VERSION "2021.24.4"

NS_ :

BS_:

BU_: VEH CH Receiver X

BA_DEF_ BO_ "GenMsgSendType" ENUM "Cyclic";
BA_DEF_ BO_ "GenMsgCycleTime" INT 0 10000;

BA_ "GenMsgSendType" BO_ 528 0;
BA_ "GenMsgCycleTime" BO_ 528 100;

BA_ "GenMsgSendType" BO_ 1879 0;
BA_ "GenMsgCycleTime" BO_ 1879 100;

BA_ "GenMsgSendType" BO_ 1621 0;
BA_ "GenMsgCycleTime" BO_ 1621 100;

BA_ "GenMsgSendType" BO_ 1680 0;
BA_ "GenMsgCycleTime" BO_ 1680 100;

BA_ "GenMsgSendType" BO_ 802 0;
BA_ "GenMsgCycleTime" BO_ 802 1000;

BA_ "GenMsgSendType" BO_ 1019 0;
BA_ "GenMsgCycleTime" BO_ 1019 1000;

BA_ "GenMsgSendType" BO_ 12 0;
BA_ "GenMsgCycleTime" BO_ 12 1000;

BO_ 963 VCRIGHT_switchStatus: 8 Vector__XXX
 SG_ VCRIGHT_3RowRightBuckleSwitch m0 : 62|2@1+ (1,0) [0|0] "" Vector__XXX
 SG_ VCRIGHT_3RowLeftBuckleSwitch m0 : 60|2@1+ (1,0) [0|0] "" Vector__XXX
 SG_ VCRIGHT_hvacHeatingAllowedRight m1 : 59|1@1+ (1,0) [0|0] "" Vector__XXX
 SG_ VCRIGHT_3RowRightOccupancySwitch m0 : 58|2@1+ (1,0) [0|0] "" Vector__XXX
 SG_ VCRIGHT_3RowLeftOccupancySwitch m0 : 56|2@1+ (1,0) [0|0] "" Vector__XXX
 SG_ VCRIGHT_frontSeatResistiveOccupancy m1 : 54|2@1+ (1,0) [0|0] "" Vector__XXX
 SG_ VCRIGHT_rearRightOccupancySwitch m0 : 54|2@1+ (1,0) [0|0] "" Vector__XXX
 SG_ VCRIGHT_liftgateShutfaceSwitchPressed m0 : 53|1@1+ (1,0) [0|0] "" Vector__XXX
 SG_ VCRIGHT_btnWindowSwPackAutoDwnRR m0 : 52|1@1+ (1,0) [0|0] "" Vector__XXX
 SG_ VCRIGHT_btnWindowSwPackDownRR m0 : 51|1@1+ (1,0) [0|0] "" Vector__XXX
 SG_ VCRIGHT_btnWindowSwPackAutoUpRR m0 : 50|1@1+ (1,0) [0|0] "" Vector__XXX
 SG_ VCRIGHT_btnWindowSwPackUpRR m0 : 49|1@1+ (1,0) [0|0] "" Vector__XXX
 SG_ VCRIGHT_trunkExtReleasePressed m0 : 48|1@1+ (1,0) [0|0] "" Vector__XXX
 SG_ VCRIGHT_gloveboxLightCurrent m1 : 47|5@1+ (2,0) [0|0] "" Vector__XXX
 SG_ VCRIGHT_rearRightBuckleSwitch m0 : 46|2@1+ (1,0) [0|0] "" Vector__XXX
 SG_ VCRIGHT_rearCenterBuckleSwitch m0 : 44|2@1+ (1,0) [0|0] "" Vector__XXX
 SG_ VCRIGHT_frontOccupancySwitch m0 : 42|2@1+ (1,0) [0|0] "" Vector__XXX
 SG_ VCRIGHT_frontBuckleSwitch m0 : 40|2@1+ (1,0) [0|0] "" Vector__XXX
 SG_ VCRIGHT_rearHandlePWM m1 : 40|7@1+ (1,0) [0|0] "" Vector__XXX
 SG_ VCRIGHT_btnWindowSwPackAutoDwnLR m0 : 39|1@1+ (1,0) [0|0] "" Vector__XXX
 SG_ VCRIGHT_hvacHeatingAllowedLeft m1 : 39|1@1+ (1,0) [0|0] "" Vector__XXX
 SG_ VCRIGHT_btnWindowSwPackDownLR m0 : 38|1@1+ (1,0) [0|0] "" Vector__XXX
 SG_ VCRIGHT_btnWindowSwPackAutoUpLR m0 : 37|1@1+ (1,0) [0|0] "" Vector__XXX
 SG_ VCRIGHT_btnWindowSwPackUpLR m0 : 36|1@1+ (1,0) [0|0] "" Vector__XXX
 SG_ VCRIGHT_btnWindowSwPackAutoDwnLF m0 : 35|1@1+ (1,0) [0|0] "" Vector__XXX
 SG_ VCRIGHT_btnWindowSwPackDownLF m0 : 34|1@1+ (1,0) [0|0] "" Vector__XXX
 SG_ VCRIGHT_btnWindowSwPackAutoUpLF m0 : 33|1@1+ (1,0) [0|0] "" Vector__XXX
 SG_ VCRIGHT_btnWindowSwPackUpLF m0 : 32|1@1+ (1,0) [0|0] "" Vector__XXX
 SG_ VCRIGHT_frontHandlePWM m1 : 32|7@1+ (1,0) [0|0] "" Vector__XXX
 SG_ VCRIGHT_btnWindowAutoDownRR m0 : 31|1@1+ (1,0) [0|0] "" Vector__XXX
 SG_ VCRIGHT_btnWindowDownRR m0 : 30|1@1+ (1,0) [0|0] "" Vector__XXX
 SG_ VCRIGHT_btnWindowAutoUpRR m0 : 29|1@1+ (1,0) [0|0] "" Vector__XXX
 SG_ VCRIGHT_btnWindowUpRR m0 : 28|1@1+ (1,0) [0|0] "" Vector__XXX
 SG_ VCRIGHT_2RowSeatBackrestFoldSwitch m1 : 27|1@1+ (1,0) [0|0] "" Vector__XXX
 SG_ VCRIGHT_btnWindowAutoDownRF m0 : 27|1@1+ (1,0) [0|0] "" Vector__XXX
 SG_ VCRIGHT_2RowSeatReclineSwitch m1 : 26|1@1+ (1,0) [0|0] "" Vector__XXX
 SG_ VCRIGHT_btnWindowDownRF m0 : 26|1@1+ (1,0) [0|0] "" Vector__XXX
 SG_ VCRIGHT_btnWindowAutoUpRF m0 : 25|1@1+ (1,0) [0|0] "" Vector__XXX
 SG_ VCRIGHT_btnWindowUpRF m0 : 24|1@1+ (1,0) [0|0] "" Vector__XXX
 SG_ VCRIGHT_frontSeatLumbarOut m1 : 24|2@1+ (1,0) [0|0] "" Vector__XXX
 SG_ VCRIGHT_frontSeatLumbarIn m1 : 22|2@1+ (1,0) [0|0] "" Vector__XXX
 SG_ VCRIGHT_frontSeatLumbarUp m1 : 20|2@1+ (1,0) [0|0] "" Vector__XXX
 SG_ VCRIGHT_frontSeatLumbarDown m1 : 18|2@1+ (1,0) [0|0] "" Vector__XXX
 SG_ VCRIGHT_frontSeatBackrestForward m1 : 16|2@1+ (1,0) [0|0] "" Vector__XXX
 SG_ VCRIGHT_frontSeatBackrestBack m1 : 14|2@1+ (1,0) [0|0] "" Vector__XXX
 SG_ VCRIGHT_frontSeatLiftUp m1 : 12|2@1+ (1,0) [0|0] "" Vector__XXX
 SG_ VCRIGHT_frontSeatLiftDown m1 : 10|2@1+ (1,0) [0|0] "" Vector__XXX
 SG_ VCRIGHT_frontSeatTiltUp m1 : 8|2@1+ (1,0) [0|0] "" Vector__XXX
 SG_ VCRIGHT_frontSeatTiltDown m1 : 6|2@1+ (1,0) [0|0] "" Vector__XXX
 SG_ VCRIGHT_frontSeatTrackForward m1 : 4|2@1+ (1,0) [0|0] "" Vector__XXX
 SG_ VCRIGHT_frontSeatTrackBack m1 : 2|2@1+ (1,0) [0|0] "" Vector__XXX
 SG_ VCRIGHT_trunkExtReleasePressedPersist m1 : 1|1@1+ (1,0) [0|0] "" Vector__XXX
 SG_ VCRIGHT_switchStatusIndex M : 0|1@1+ (1,0) [0|0] "" Vector__XXX

BO_ 989 CP_loggingSlow: 8 Vector__XXX
 SG_ CP_doorPushLockoutActive m4 : 63|1@1+ (1,0) [0|0] "" Vector__XXX
 SG_ CP_faultLineSetByCP m2 : 62|1@1+ (1,0) [0|0] "" Vector__XXX
 SG_ CP_pilotWakeCounter m6 : 61|3@1+ (1,0) [0|0] "" Vector__XXX
 SG_ CP_proximityWakeCounter m5 : 61|3@1+ (1,0) [0|0] "" Vector__XXX
 SG_ CP_wakeOnPushCounter m4 : 60|3@1+ (1,0) [0|0] "" Vector__XXX
 SG_ CP_backCover2State m1 : 59|3@1+ (1,0) [0|0] "" Vector__XXX
 SG_ CP_inletHeaterDuty m3 : 57|7@1+ (1,0) [0|0] "" Vector__XXX
 SG_ CP_backCoverState m1 : 56|3@1+ (1,0) [0|0] "" Vector__XXX
 SG_ CP_doorCloseLimiterMaxRequestType m5 : 56|5@1+ (1,0) [0|0] "" Vector__XXX
 SG_ CP_uhfDoorRequestCounts m7 : 56|5@1+ (1,0) [0|0] "" Vector__XXX
 SG_ CP_inletHeaterState m3 : 55|2@1+ (1,0) [0|0] "" Vector__XXX
 SG_ CP_acNumRetries m6 : 53|8@1+ (1,0) [0|0] "" Vector__XXX
 SG_ CP_doorCloseLimiterMaxCount m5 : 52|4@1+ (1,0) [0|0] "" Vector__XXX
 SG_ CP_faultLineV m2 : 52|10@1+ (0.004550576735092864,0) [0|0] "" Vector__XXX
 SG_ CP_inlet2HarnessIdValue m3 : 52|3@1+ (1,0) [0|0] "" Vector__XXX
 SG_ CP_inlet2HarnessIdState m3 : 50|2@1+ (1,0) [0|0] "" Vector__XXX
 SG_ CP_inlet2HarnessV m0 : 50|14@1+ (0.001,0) [0|0] "" Vector__XXX
 SG_ CP_doorOpenLimiterMaxRequestType m5 : 48|4@1+ (1,0) [0|0] "" Vector__XXX
 SG_ CP_sensorExtV m1 : 48|8@1+ (0.01968504,0) [0|0] "" Vector__XXX
 SG_ CP_inlet1HarnessIdValue m3 : 47|3@1+ (1,0) [0|0] "" Vector__XXX
 SG_ CP_inlet1HarnessIdState m3 : 45|2@1+ (1,0) [0|0] "" Vector__XXX
 SG_ CP_doorOpenLimiterMaxCount m5 : 44|4@1+ (1,0) [0|0] "" Vector__XXX
 SG_ CP_nvm_pilotDiodeFaultCount m5 : 41|3@1+ (1,0) [0|0] "" Vector__XXX
 SG_ CP_nvm_badPilotDiodeDetected m5 : 40|1@1+ (1,0) [0|0] "" Vector__XXX
 SG_ CP_pilotHighValue_intervalMin10s m2 : 40|12@1- (0.01,0) [0|0] "" Vector__XXX
 SG_ CP_plcV m1 : 40|8@1+ (0.01294118,0) [0|0] "" Vector__XXX
 SG_ CP_nvm_doorPresentValid m5 : 39|1@1+ (1,0) [0|0] "" Vector__XXX
 SG_ CP_acNextRetryTimeoutS m6 : 38|15@1+ (1,0) [0|0] "" Vector__XXX
 SG_ CP_nvm_doorPresent m5 : 38|1@1+ (1,0) [0|0] "" Vector__XXX
 SG_ CP_nvm_doorOpen m5 : 37|1@1+ (1,0) [0|0] "" Vector__XXX
 SG_ CP_doorId_intervalMax10s m4 : 36|8@1+ (0.0196078431372549,0) [0|0] "" Vector__XXX
 SG_ CP_inlet1HarnessV m0 : 36|14@1+ (0.001,0) [0|0] "" Vector__XXX
 SG_ CP_latchI m3 : 33|12@1+ (0.0025,0) [0|0] "" Vector__XXX
 SG_ CP_ivledV m1 : 32|8@1+ (0.01968504,0) [0|0] "" Vector__XXX
 SG_ CP_doorId_intervalMin10s m4 : 28|8@1+ (0.0196078431372549,0) [0|0] "" Vector__XXX
 SG_ CP_inductiveSensorBaseline m7 : 28|28@1+ (0.08083879947662354,0) [0|0] "" Vector__XXX
 SG_ CP_ivledState m1 : 28|2@1+ (1,0) [0|0] "" Vector__XXX
 SG_ CP_pilotHighValue_intervalMax10s m2 : 28|12@1- (0.01,0) [0|0] "" Vector__XXX
 SG_ CP_UHF_selfTestRssi m3 : 25|8@1+ (1,0) [0|0] "" Vector__XXX
 SG_ CP_acRetryTimeoutS m6 : 23|15@1+ (1,0) [0|0] "" Vector__XXX
 SG_ CP_nvm_doorCloseCycles m5 : 21|16@1+ (1,0) [0|0] "" Vector__XXX
 SG_ CP_proximityV_intervalMin10s m0 : 20|16@1+ (0.0001,0) [0|0] "" Vector__XXX
 SG_ CP_refVoltage m4 : 20|8@1+ (0.0070588235,0) [0|0] "" Vector__XXX
 SG_ CP_doorButtonPressDurationMs m7 : 18|10@1+ (1,0) [0|0] "" Vector__XXX
 SG_ CP_UHF_rxNumBytes m3 : 17|8@1+ (1,0) [0|0] "" Vector__XXX
 SG_ CP_UHF_rxOverflow m3 : 16|1@1+ (1,0) [0|0] "" Vector__XXX
 SG_ CP_backCover2Counts m1 : 16|12@1+ (0.025,0) [0|0] "" Vector__XXX
 SG_ CP_pilotLowValue_intervalMin10s m2 : 16|12@1- (0.01,0) [0|0] "" Vector__XXX
 SG_ CP_tlsMemoryUsage_intervalMin10s m6 : 16|7@1+ (0.7874015748031497,0) [0|0] "" Vector__XXX
 SG_ CP_boardTemperature m4 : 12|8@1+ (1.29411764706,-50) [0|0] "" Vector__XXX
 SG_ CP_cpuUtilization_intervalMin10s m7 : 11|7@1+ (0.7874015748031497,0) [0|0] "" Vector__XXX
 SG_ CP_UHF_rssi m3 : 8|8@1+ (1,0) [0|0] "" Vector__XXX
 SG_ CP_tlsMemoryUsage_intervalMax10s m6 : 8|7@1+ (0.7874015748031497,0) [0|0] "" Vector__XXX
 SG_ CP_nvm_doorOpenCycles m5 : 5|16@1+ (1,0) [0|0] "" Vector__XXX
 SG_ CP_5vSwV m4 : 4|8@1+ (0.027450980392156862,0) [0|0] "" Vector__XXX
 SG_ CP_UHF_chipState m3 : 4|3@1+ (1,0) [0|0] "" Vector__XXX
 SG_ CP_backCoverCounts m1 : 4|12@1+ (0.025,0) [0|0] "" Vector__XXX
 SG_ CP_cpuUtilization_intervalMax10s m7 : 4|7@1+ (0.7874015748031497,0) [0|0] "" Vector__XXX
 SG_ CP_nvm_dataValid m5 : 4|1@1+ (1,0) [0|0] "" Vector__XXX
 SG_ CP_pilotLowValue_intervalMax10s m2 : 4|12@1- (0.01,0) [0|0] "" Vector__XXX
 SG_ CP_proximityV_intervalMax10s m0 : 4|16@1+ (0.0001,0) [0|0] "" Vector__XXX
 SG_ CP_loggingSlowSelect M : 0|4@1+ (1,0) [0|0] "" Vector__XXX

BO_ 1014 VCFRONT_lightStatus: 8 Vector__XXX
 SG_ VC_hcmrMigrationWindowOpen m0 : 63|1@1+ (1,0) [0|0] "" Vector__XXX
 SG_ VC_hcmrMigrationStallDetectionEnabled m0 : 62|1@1+ (1,0) [0|0] "" Vector__XXX
 SG_ VC_hcmrMigrationMigrationNotStarted m0 : 61|1@1+ (1,0) [0|0] "" Vector__XXX
 SG_ VC_hcmrMigrationOnLVSupport m0 : 60|1@1+ (1,0) [0|0] "" Vector__XXX
 SG_ VC_hcmrMigrationVehicleUpdateActive m0 : 59|1@1+ (1,0) [0|0] "" Vector__XXX
 SG_ VC_hcmrMigrationOTAStateNotActive m0 : 58|1@1+ (1,0) [0|0] "" Vector__XXX
 SG_ VC_hcmrMigrationOTAStateWasActive m0 : 57|1@1+ (1,0) [0|0] "" Vector__XXX
 SG_ VC_hcmrMigrationValidWeather m0 : 56|1@1+ (1,0) [0|0] "" Vector__XXX
 SG_ VCFRONT_headlampRoadClass m1 : 55|2@1+ (1,0) [0|0] "" Vector__XXX
 SG_ VC_hcmlMigrationWindowOpen m0 : 55|1@1+ (1,0) [0|0] "" Vector__XXX
 SG_ VC_hcmlMigrationStallDetectionEnabled m0 : 54|1@1+ (1,0) [0|0] "" Vector__XXX
 SG_ VC_hcmlMigrationMigrationNotStarted m0 : 53|1@1+ (1,0) [0|0] "" Vector__XXX
 SG_ VC_hcmlMigrationOnLVSupport m0 : 52|1@1+ (1,0) [0|0] "" Vector__XXX
 SG_ VC_hcmlMigrationVehicleUpdateActive m0 : 51|1@1+ (1,0) [0|0] "" Vector__XXX
 SG_ VC_hcmlMigrationOTAStateNotActive m0 : 50|1@1+ (1,0) [0|0] "" Vector__XXX
 SG_ VC_hcmlMigrationOTAStateWasActive m0 : 49|1@1+ (1,0) [0|0] "" Vector__XXX
 SG_ VC_hcmlMigrationValidWeather m0 : 48|1@1+ (1,0) [0|0] "" Vector__XXX
 SG_ VCFRONT_headlampBendAngle m1 : 47|8@1- (0.1,0) [0|0] "" Vector__XXX
 SG_ VCFRONT_advancedDrivingBeamStatus m1 : 45|2@1+ (1,0) [0|0] "" Vector__XXX
 SG_ VCFRONT_isBendLightingAvailable m1 : 44|1@1+ (1,0) [0|0] "" Vector__XXX
 SG_ VCFRONT_isAdaptiveHighBeamFaulted m1 : 43|1@1+ (1,0) [0|0] "" Vector__XXX
 SG_ VCFRONT_isAdaptiveHighBeamAvailable m1 : 42|1@1+ (1,0) [0|0] "" Vector__XXX
 SG_ VCFRONT_lightStatusMuxIndex M : 39|3@1+ (1,0) [0|0] "" Vector__XXX
 SG_ VC_leftHeadlampHealth : 36|3@1+ (1,0) [0|0] "" Vector__XXX
 SG_ VC_rightHeadlampHealth : 33|3@1+ (1,0) [0|0] "" Vector__XXX
 SG_ VCFRONT_lowBeamsOnForDRL : 32|1@1+ (1,0) [0|0] "" Vector__XXX
 SG_ VCFRONT_lowBeamRightReadyForAiming : 31|1@1+ (1,0) [0|0] "" Vector__XXX
 SG_ VCFRONT_lowBeamLeftReadyForAiming : 30|1@1+ (1,0) [0|0] "" Vector__XXX
 SG_ VCFRONT_parkRightStatus : 28|2@1+ (1,0) [0|0] "" Vector__XXX
 SG_ VCFRONT_parkLeftStatus : 26|2@1+ (1,0) [0|0] "" Vector__XXX
 SG_ VCFRONT_turnSignalRightStatus : 24|2@1+ (1,0) [0|0] "" Vector__XXX
 SG_ VCFRONT_turnSignalLeftStatus : 22|2@1+ (1,0) [0|0] "" Vector__XXX
 SG_ VCFRONT_sideRepeaterRightStatus : 20|2@1+ (1,0) [0|0] "" Vector__XXX
 SG_ VCFRONT_sideRepeaterLeftStatus : 18|2@1+ (1,0) [0|0] "" Vector__XXX
 SG_ VCFRONT_sideMarkersStatus : 16|2@1+ (1,0) [0|0] "" Vector__XXX
 SG_ VCFRONT_fogRightStatus : 14|2@1+ (1,0) [0|0] "" Vector__XXX
 SG_ VCFRONT_fogLeftStatus : 12|2@1+ (1,0) [0|0] "" Vector__XXX
 SG_ VCFRONT_DRLRightStatus : 10|2@1+ (1,0) [0|0] "" Vector__XXX
 SG_ VCFRONT_DRLLeftStatus : 8|2@1+ (1,0) [0|0] "" Vector__XXX
 SG_ VCFRONT_highBeamRightStatus : 6|2@1+ (1,0) [0|0] "" Vector__XXX
 SG_ VCFRONT_highBeamLeftStatus : 4|2@1+ (1,0) [0|0] "" Vector__XXX
 SG_ VCFRONT_lowBeamRightStatus : 2|2@1+ (1,0) [0|0] "" Vector__XXX
 SG_ VCFRONT_lowBeamLeftStatus : 0|2@1+ (1,0) [0|0] "" Vector__XXX

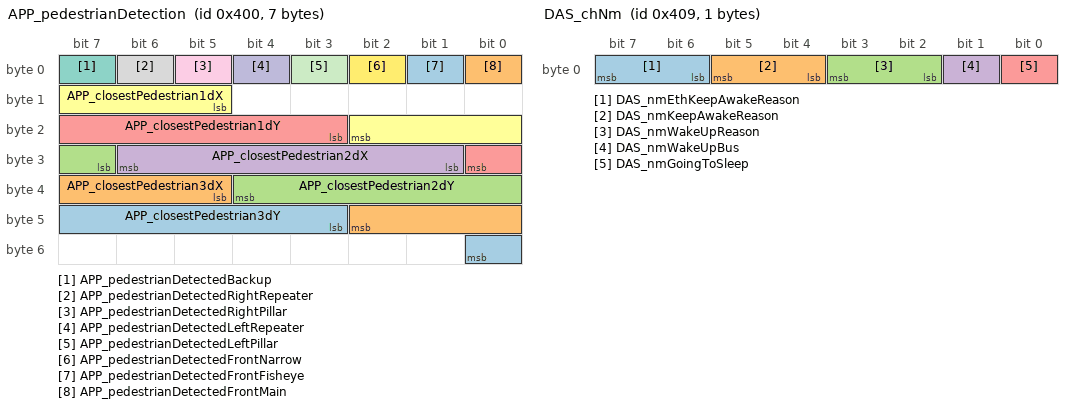
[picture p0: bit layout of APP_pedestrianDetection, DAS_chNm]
BO_ 1024 APP_pedestrianDetection: 7 Vector__XXX
 SG_ APP_closestPedestrian3dY : 43|6@1- (0.4,0) [0|0] "" Vector__XXX
 SG_ APP_closestPedestrian3dX : 37|6@1- (0.4,0) [0|0] "" Vector__XXX
 SG_ APP_closestPedestrian2dY : 31|6@1- (0.4,0) [0|0] "" Vector__XXX
 SG_ APP_closestPedestrian2dX : 25|6@1- (0.4,0) [0|0] "" Vector__XXX
 SG_ APP_closestPedestrian1dY : 19|6@1- (0.4,0) [0|0] "" Vector__XXX
 SG_ APP_closestPedestrian1dX : 13|6@1- (0.4,0) [0|0] "" Vector__XXX
 SG_ APP_pedestrianDetectedBackup : 7|1@1+ (1,0) [0|0] "" Vector__XXX
 SG_ APP_pedestrianDetectedRightRepeater : 6|1@1+ (1,0) [0|0] "" Vector__XXX
 SG_ APP_pedestrianDetectedRightPillar : 5|1@1+ (1,0) [0|0] "" Vector__XXX
 SG_ APP_pedestrianDetectedLeftRepeater : 4|1@1+ (1,0) [0|0] "" Vector__XXX
 SG_ APP_pedestrianDetectedLeftPillar : 3|1@1+ (1,0) [0|0] "" Vector__XXX
 SG_ APP_pedestrianDetectedFrontNarrow : 2|1@1+ (1,0) [0|0] "" Vector__XXX
 SG_ APP_pedestrianDetectedFrontFisheye : 1|1@1+ (1,0) [0|0] "" Vector__XXX
 SG_ APP_pedestrianDetectedFrontMain : 0|1@1+ (1,0) [0|0] "" Vector__XXX

BO_ 1031 DAS_bodyControls2: 8 Vector__XXX
 SG_ DAS_windowLockoutMode : 56|3@1+ (1,0) [0|0] "" Vector__XXX
 SG_ DAS_lightingAnimationRequest : 45|3@1+ (1,0) [0|0] "" Vector__XXX
 SG_ DAS_rearTrunkLockRequest : 43|2@1+ (1,0) [0|0] "" Vector__XXX
 SG_ DAS_doorLockRequestRR : 41|2@1+ (1,0) [0|0] "" Vector__XXX
 SG_ DAS_doorLockRequestRL : 39|2@1+ (1,0) [0|0] "" Vector__XXX
 SG_ DAS_doorLockRequestFR : 37|2@1+ (1,0) [0|0] "" Vector__XXX
 SG_ DAS_doorLockRequestFL : 35|2@1+ (1,0) [0|0] "" Vector__XXX
 SG_ DAS_frunkRequest : 33|2@1+ (1,0) [0|0] "" Vector__XXX
 SG_ DAS_windowRequestActiveRR : 32|1@1+ (1,0) [0|0] "" Vector__XXX
 SG_ DAS_windowRequestActiveRL : 31|1@1+ (1,0) [0|0] "" Vector__XXX
 SG_ DAS_windowRequestActiveFR : 30|1@1+ (1,0) [0|0] "" Vector__XXX
 SG_ DAS_windowRequestActiveFL : 29|1@1+ (1,0) [0|0] "" Vector__XXX
 SG_ DAS_windowRequest : 26|3@1+ (1,0) [0|0] "" Vector__XXX
 SG_ DAS_trunkRequest : 24|2@1+ (1,0) [0|0] "" Vector__XXX
 SG_ DAS_hornRequest : 22|2@1+ (1,0) [0|0] "" Vector__XXX
 SG_ DAS_parkingLightDimRequest : 21|1@1+ (1,0) [0|0] "" Vector__XXX
 SG_ DAS_airTankDischargeCmd : 20|1@1+ (1,0) [0|0] "" Vector__XXX
 SG_ DAS_airCleanPillarBackupCmd : 19|1@1+ (1,0) [0|0] "" Vector__XXX
 SG_ DAS_airCleanRepeaterCmd : 18|1@1+ (1,0) [0|0] "" Vector__XXX
 SG_ DAS_fluidCleanPillarBackupCmd : 17|1@1+ (1,0) [0|0] "" Vector__XXX
 SG_ DAS_fluidCleanRightRepeaterCmd : 16|1@1+ (1,0) [0|0] "" Vector__XXX
 SG_ DAS_fluidCleanLeftRepeaterCmd : 15|1@1+ (1,0) [0|0] "" Vector__XXX
 SG_ DAS_fluidCleanFasciaCmd : 14|1@1+ (1,0) [0|0] "" Vector__XXX
 SG_ DAS_narrowWipeRequest : 13|1@1+ (1,0) [0|0] "" Vector__XXX
 SG_ DAS_narrowWiperWashRequest : 12|1@1+ (1,0) [0|0] "" Vector__XXX
 SG_ DAS_bodyControls2Counter : 8|4@1+ (1,0) [0|0] "" Vector__XXX
 SG_ DAS_bodyControls2Checksum : 0|8@1+ (1,0) [0|0] "" Vector__XXX

BO_ 1033 DAS_chNm: 1 Vector__XXX
 SG_ DAS_nmEthKeepAwakeReason : 6|2@1+ (1,0) [0|0] "" Vector__XXX
 SG_ DAS_nmKeepAwakeReason : 4|2@1+ (1,0) [0|0] "" Vector__XXX
 SG_ DAS_nmWakeUpReason : 2|2@1+ (1,0) [0|0] "" Vector__XXX
 SG_ DAS_nmWakeUpBus : 1|1@1+ (1,0) [0|0] "" Vector__XXX
 SG_ DAS_nmGoingToSleep : 0|1@1+ (1,0) [0|0] "" Vector__XXX

BO_ 1044 GTW_chargingID: 8 Vector__XXX
 SG_ GTW_chargingIDHigh m16 : 47|24@0+ (1,0) [0|0] "" Vector__XXX
 SG_ GTW_chargingIDLow m18 : 15|56@0+ (1,0) [0|0] "" Vector__XXX
 SG_ GTW_chargingIDMid m17 : 15|56@0+ (1,0) [0|0] "" Vector__XXX
 SG_ GTW_chargingIDIndex M : 7|8@0+ (1,0) [0|0] "" Vector__XXX

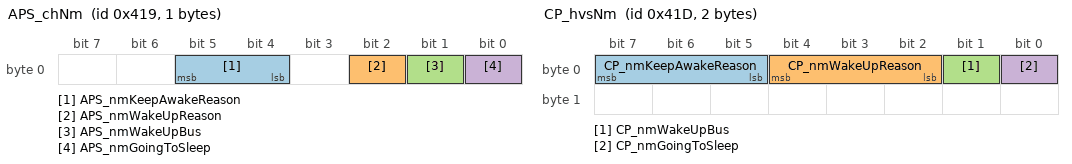
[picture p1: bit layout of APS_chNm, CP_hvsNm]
BO_ 1049 APS_chNm: 1 Vector__XXX
 SG_ APS_nmKeepAwakeReason : 4|2@1+ (1,0) [0|0] "" Vector__XXX
 SG_ APS_nmWakeUpReason : 2|1@1+ (1,0) [0|0] "" Vector__XXX
 SG_ APS_nmWakeUpBus : 1|1@1+ (1,0) [0|0] "" Vector__XXX
 SG_ APS_nmGoingToSleep : 0|1@1+ (1,0) [0|0] "" Vector__XXX

BO_ 1053 CP_hvsNm: 2 Vector__XXX
 SG_ CP_nmKeepAwakeReason : 5|3@1+ (1,0) [0|0] "" Vector__XXX
 SG_ CP_nmWakeUpReason : 2|3@1+ (1,0) [0|0] "" Vector__XXX
 SG_ CP_nmWakeUpBus : 1|1@1+ (1,0) [0|0] "" Vector__XXX
 SG_ CP_nmGoingToSleep : 0|1@1+ (1,0) [0|0] "" Vector__XXX

BO_ 1056 APS_state: 8 Vector__XXX
 SG_ APS_stateCounter : 55|4@1+ (1,0) [0|0] "" Vector__XXX
 SG_ APS_B_faultInduced : 54|1@1+ (1,0) [0|0] "" Vector__XXX
 SG_ APS_A_faultInduced : 53|1@1+ (1,0) [0|0] "" Vector__XXX
 SG_ APS_eplannerState : 50|3@1+ (1,0) [0|0] "" Vector__XXX
 SG_ APS_B_autosteerMonitorState : 47|3@1+ (1,0) [0|0] "" Vector__XXX
 SG_ APS_A_autosteerMonitorState : 44|3@1+ (1,0) [0|0] "" Vector__XXX
 SG_ APS_B_faultState : 39|5@1+ (1,0) [0|0] "" Vector__XXX
 SG_ APS_B_resetState : 36|3@1+ (1,0) [0|0] "" Vector__XXX
 SG_ APS_B_sleepState : 32|4@1+ (1,0) [0|0] "" Vector__XXX
 SG_ APS_B_powerState : 27|5@1+ (1,0) [0|0] "" Vector__XXX
 SG_ APS_B_arbState : 24|3@1+ (1,0) [0|0] "" Vector__XXX
 SG_ APS_secondaryTurbo : 22|2@1+ (1,0) [0|0] "" Vector__XXX
 SG_ APS_A_faultState : 17|5@1+ (1,0) [0|0] "" Vector__XXX
 SG_ APS_A_resetState : 14|3@1+ (1,0) [0|0] "" Vector__XXX
 SG_ APS_A_sleepState : 10|4@1+ (1,0) [0|0] "" Vector__XXX
 SG_ APS_A_powerState : 5|5@1+ (1,0) [0|0] "" Vector__XXX
 SG_ APS_A_arbState : 2|3@1+ (1,0) [0|0] "" Vector__XXX
 SG_ APS_primaryTurbo : 0|2@1+ (1,0) [0|0] "" Vector__XXX

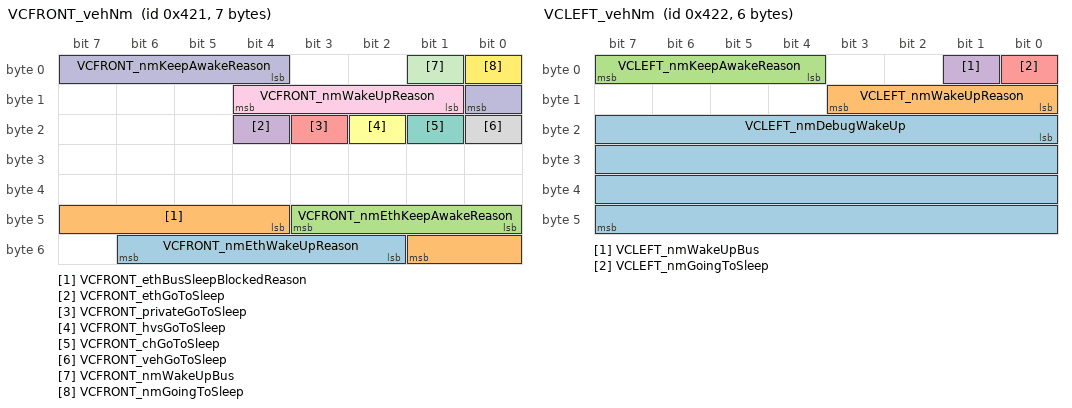
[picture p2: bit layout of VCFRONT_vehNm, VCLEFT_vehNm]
BO_ 1057 VCFRONT_vehNm: 7 Vector__XXX
 SG_ VCFRONT_nmEthWakeUpReason : 50|5@1+ (1,0) [0|0] "" Vector__XXX
 SG_ VCFRONT_ethBusSleepBlockedReason : 44|6@1+ (1,0) [0|0] "" Vector__XXX
 SG_ VCFRONT_nmEthKeepAwakeReason : 40|4@1+ (1,0) [0|0] "" Vector__XXX
 SG_ VCFRONT_ethGoToSleep : 20|1@1+ (1,0) [0|0] "" Vector__XXX
 SG_ VCFRONT_privateGoToSleep : 19|1@1+ (1,0) [0|0] "" Vector__XXX
 SG_ VCFRONT_hvsGoToSleep : 18|1@1+ (1,0) [0|0] "" Vector__XXX
 SG_ VCFRONT_chGoToSleep : 17|1@1+ (1,0) [0|0] "" Vector__XXX
 SG_ VCFRONT_vehGoToSleep : 16|1@1+ (1,0) [0|0] "" Vector__XXX
 SG_ VCFRONT_nmWakeUpReason : 9|4@1+ (1,0) [0|0] "" Vector__XXX
 SG_ VCFRONT_nmKeepAwakeReason : 4|5@1+ (1,0) [0|0] "" Vector__XXX
 SG_ VCFRONT_nmWakeUpBus : 1|1@1+ (1,0) [0|0] "" Vector__XXX
 SG_ VCFRONT_nmGoingToSleep : 0|1@1+ (1,0) [0|0] "" Vector__XXX

BO_ 1058 VCLEFT_vehNm: 6 Vector__XXX
 SG_ VCLEFT_nmDebugWakeUp : 16|32@1+ (1,0) [0|0] "" Vector__XXX
 SG_ VCLEFT_nmWakeUpReason : 8|4@1+ (1,0) [0|0] "" Vector__XXX
 SG_ VCLEFT_nmKeepAwakeReason : 4|4@1+ (1,0) [0|0] "" Vector__XXX
 SG_ VCLEFT_nmWakeUpBus : 1|1@1+ (1,0) [0|0] "" Vector__XXX
 SG_ VCLEFT_nmGoingToSleep : 0|1@1+ (1,0) [0|0] "" Vector__XXX

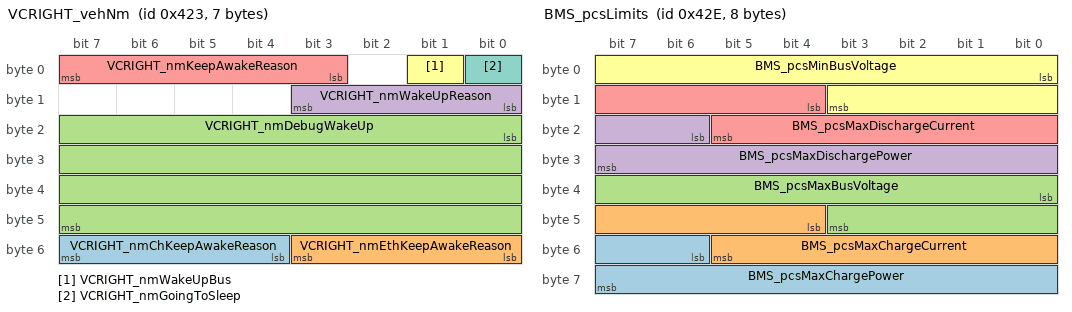
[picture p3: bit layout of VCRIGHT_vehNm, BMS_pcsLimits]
BO_ 1059 VCRIGHT_vehNm: 7 Vector__XXX
 SG_ VCRIGHT_nmChKeepAwakeReason : 52|4@1+ (1,0) [0|0] "" Vector__XXX
 SG_ VCRIGHT_nmEthKeepAwakeReason : 48|4@1+ (1,0) [0|0] "" Vector__XXX
 SG_ VCRIGHT_nmDebugWakeUp : 16|32@1+ (1,0) [0|0] "" Vector__XXX
 SG_ VCRIGHT_nmWakeUpReason : 8|4@1+ (1,0) [0|0] "" Vector__XXX
 SG_ VCRIGHT_nmKeepAwakeReason : 3|5@1+ (1,0) [0|0] "" Vector__XXX
 SG_ VCRIGHT_nmWakeUpBus : 1|1@1+ (1,0) [0|0] "" Vector__XXX
 SG_ VCRIGHT_nmGoingToSleep : 0|1@1+ (1,0) [0|0] "" Vector__XXX

BO_ 1070 BMS_pcsLimits: 8 Vector__XXX
 SG_ BMS_pcsMaxChargePower : 54|10@1+ (0.025,0) [0|0] "" Vector__XXX
 SG_ BMS_pcsMaxChargeCurrent : 44|10@1+ (0.1,0) [0|0] "" Vector__XXX
 SG_ BMS_pcsMaxBusVoltage : 32|12@1+ (0.25,0) [0|0] "" Vector__XXX
 SG_ BMS_pcsMaxDischargePower : 22|10@1+ (0.025,0) [0|0] "" Vector__XXX
 SG_ BMS_pcsMaxDischargeCurrent : 12|10@1+ (0.1,0) [0|0] "" Vector__XXX
 SG_ BMS_pcsMinBusVoltage : 0|12@1+ (0.25,0) [0|0] "" Vector__XXX

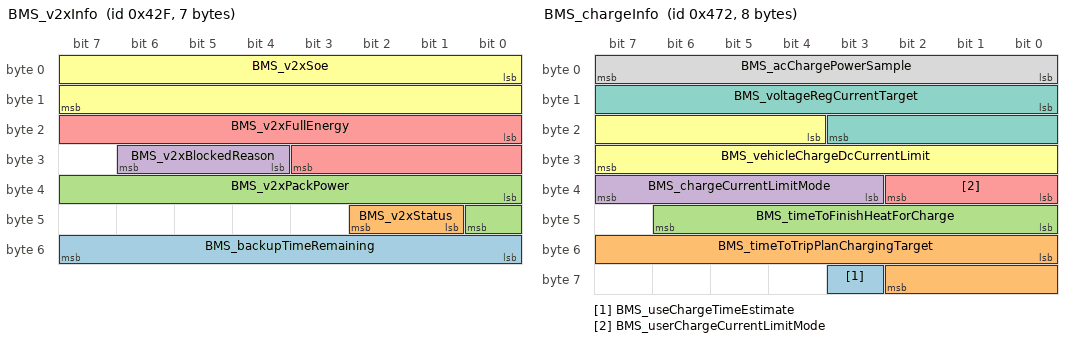
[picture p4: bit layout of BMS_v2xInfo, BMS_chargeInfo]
BO_ 1071 BMS_v2xInfo: 7 Vector__XXX
 SG_ BMS_backupTimeRemaining : 48|8@1+ (1,0) [0|0] "" Vector__XXX
 SG_ BMS_v2xStatus : 41|2@1+ (1,0) [0|0] "" Vector__XXX
 SG_ BMS_v2xPackPower : 32|9@1+ (0.1,-25) [0|0] "" Vector__XXX
 SG_ BMS_v2xBlockedReason : 28|3@1+ (1,0) [0|0] "" Vector__XXX
 SG_ BMS_v2xFullEnergy : 16|12@1+ (0.05,0) [0|0] "" Vector__XXX
 SG_ BMS_v2xSoe : 0|16@1+ (0.002,0) [0|0] "" Vector__XXX

BO_ 1083 VCSEC_peripheralOTAStatus: 8 Vector__XXX
 SG_ VCSEC_TPMSUpdateRetryLimitReached0 m0 : 59|1@1+ (1,0) [0|0] "" Vector__XXX
 SG_ VCSEC_TPMSUpdateRetryLimitReached1 m1 : 59|1@1+ (1,0) [0|0] "" Vector__XXX
 SG_ VCSEC_TPMSUpdateRetryLimitReached2 m2 : 59|1@1+ (1,0) [0|0] "" Vector__XXX
 SG_ VCSEC_TPMSUpdateRetryLimitReached3 m3 : 59|1@1+ (1,0) [0|0] "" Vector__XXX
 SG_ VCSEC_TPMSUpdateHasStarted0 m0 : 58|1@1+ (1,0) [0|0] "" Vector__XXX
 SG_ VCSEC_TPMSUpdateHasStarted1 m1 : 58|1@1+ (1,0) [0|0] "" Vector__XXX
 SG_ VCSEC_TPMSUpdateHasStarted2 m2 : 58|1@1+ (1,0) [0|0] "" Vector__XXX
 SG_ VCSEC_TPMSUpdateHasStarted3 m3 : 58|1@1+ (1,0) [0|0] "" Vector__XXX
 SG_ VCSEC_TPMSUpdateHasUpdated0 m0 : 57|1@1+ (1,0) [0|0] "" Vector__XXX
 SG_ VCSEC_TPMSUpdateHasUpdated1 m1 : 57|1@1+ (1,0) [0|0] "" Vector__XXX
 SG_ VCSEC_TPMSUpdateHasUpdated2 m2 : 57|1@1+ (1,0) [0|0] "" Vector__XXX
 SG_ VCSEC_TPMSUpdateHasUpdated3 m3 : 57|1@1+ (1,0) [0|0] "" Vector__XXX
 SG_ VCSEC_keyWhitelistIndexBeingUpdated m4 : 57|5@1+ (1,0) [0|0] "" Vector__XXX
 SG_ VCSEC_KeyfobUpdateExpectReconnect m4 : 56|1@1+ (1,0) [0|0] "" Vector__XXX
 SG_ VCSEC_TPMSUpdateExpectReconnect0 m0 : 56|1@1+ (1,0) [0|0] "" Vector__XXX
 SG_ VCSEC_TPMSUpdateExpectReconnect1 m1 : 56|1@1+ (1,0) [0|0] "" Vector__XXX
 SG_ VCSEC_TPMSUpdateExpectReconnect2 m2 : 56|1@1+ (1,0) [0|0] "" Vector__XXX
 SG_ VCSEC_TPMSUpdateExpectReconnect3 m3 : 56|1@1+ (1,0) [0|0] "" Vector__XXX
 SG_ VCSEC_KeyfobUpdateWaitForFlashCount m4 : 52|4@1+ (1,0) [0|0] "" Vector__XXX
 SG_ VCSEC_TPMSUpdateWaitForFlashCount0 m0 : 52|4@1+ (1,0) [0|0] "" Vector__XXX
 SG_ VCSEC_TPMSUpdateWaitForFlashCount1 m1 : 52|4@1+ (1,0) [0|0] "" Vector__XXX
 SG_ VCSEC_TPMSUpdateWaitForFlashCount2 m2 : 52|4@1+ (1,0) [0|0] "" Vector__XXX
 SG_ VCSEC_TPMSUpdateWaitForFlashCount3 m3 : 52|4@1+ (1,0) [0|0] "" Vector__XXX
 SG_ VCSEC_KeyfobUpdateStalledBlockCount m4 : 48|4@1+ (1,0) [0|0] "" Vector__XXX
 SG_ VCSEC_TPMSUpdateStalledBlockCount0 m0 : 48|4@1+ (1,0) [0|0] "" Vector__XXX
 SG_ VCSEC_TPMSUpdateStalledBlockCount1 m1 : 48|4@1+ (1,0) [0|0] "" Vector__XXX
 SG_ VCSEC_TPMSUpdateStalledBlockCount2 m2 : 48|4@1+ (1,0) [0|0] "" Vector__XXX
 SG_ VCSEC_TPMSUpdateStalledBlockCount3 m3 : 48|4@1+ (1,0) [0|0] "" Vector__XXX
 SG_ VCSEC_KeyfobUpdateLocationSetCount m4 : 44|4@1+ (1,0) [0|0] "" Vector__XXX
 SG_ VCSEC_TPMSUpdateLocationSetCount0 m0 : 44|4@1+ (1,0) [0|0] "" Vector__XXX
 SG_ VCSEC_TPMSUpdateLocationSetCount1 m1 : 44|4@1+ (1,0) [0|0] "" Vector__XXX
 SG_ VCSEC_TPMSUpdateLocationSetCount2 m2 : 44|4@1+ (1,0) [0|0] "" Vector__XXX
 SG_ VCSEC_TPMSUpdateLocationSetCount3 m3 : 44|4@1+ (1,0) [0|0] "" Vector__XXX
 SG_ VCSEC_KeyfobUpdateCRCRequestTimeoutCount m4 : 40|4@1+ (1,0) [0|0] "" Vector__XXX
 SG_ VCSEC_TPMSUpdateCRCRequestTimeoutCount0 m0 : 40|4@1+ (1,0) [0|0] "" Vector__XXX
 SG_ VCSEC_TPMSUpdateCRCRequestTimeoutCount1 m1 : 40|4@1+ (1,0) [0|0] "" Vector__XXX
 SG_ VCSEC_TPMSUpdateCRCRequestTimeoutCount2 m2 : 40|4@1+ (1,0) [0|0] "" Vector__XXX
 SG_ VCSEC_TPMSUpdateCRCRequestTimeoutCount3 m3 : 40|4@1+ (1,0) [0|0] "" Vector__XXX
 SG_ VCSEC_KeyfobUpdateBlockErrorCount m4 : 36|4@1+ (1,0) [0|0] "" Vector__XXX
 SG_ VCSEC_TPMSUpdateBlockErrorCount0 m0 : 36|4@1+ (1,0) [0|0] "" Vector__XXX
 SG_ VCSEC_TPMSUpdateBlockErrorCount1 m1 : 36|4@1+ (1,0) [0|0] "" Vector__XXX
 SG_ VCSEC_TPMSUpdateBlockErrorCount2 m2 : 36|4@1+ (1,0) [0|0] "" Vector__XXX
 SG_ VCSEC_TPMSUpdateBlockErrorCount3 m3 : 36|4@1+ (1,0) [0|0] "" Vector__XXX
 SG_ VCSEC_KeyfobUpdateBlockTimeoutCount m4 : 32|4@1+ (1,0) [0|0] "" Vector__XXX
 SG_ VCSEC_TPMSUpdateBlockTimeoutCount0 m0 : 32|4@1+ (1,0) [0|0] "" Vector__XXX
 SG_ VCSEC_TPMSUpdateBlockTimeoutCount1 m1 : 32|4@1+ (1,0) [0|0] "" Vector__XXX
 SG_ VCSEC_TPMSUpdateBlockTimeoutCount2 m2 : 32|4@1+ (1,0) [0|0] "" Vector__XXX
 SG_ VCSEC_TPMSUpdateBlockTimeoutCount3 m3 : 32|4@1+ (1,0) [0|0] "" Vector__XXX
 SG_ VCSEC_KeyfobUpdateLastRespStatus m4 : 24|8@1+ (1,0) [0|0] "" Vector__XXX
 SG_ VCSEC_TPMSUpdateLastStatus0 m0 : 24|8@1+ (1,0) [0|0] "" Vector__XXX
 SG_ VCSEC_TPMSUpdateLastStatus1 m1 : 24|8@1+ (1,0) [0|0] "" Vector__XXX
 SG_ VCSEC_TPMSUpdateLastStatus2 m2 : 24|8@1+ (1,0) [0|0] "" Vector__XXX
 SG_ VCSEC_TPMSUpdateLastStatus3 m3 : 24|8@1+ (1,0) [0|0] "" Vector__XXX
 SG_ VCSEC_KeyfobUpdateLastTxStatus m4 : 16|8@1+ (1,0) [0|0] "" Vector__XXX
 SG_ VCSEC_TPMSUpdateState0 m0 : 16|8@1+ (1,0) [0|0] "" Vector__XXX
 SG_ VCSEC_TPMSUpdateState1 m1 : 16|8@1+ (1,0) [0|0] "" Vector__XXX
 SG_ VCSEC_TPMSUpdateState2 m2 : 16|8@1+ (1,0) [0|0] "" Vector__XXX
 SG_ VCSEC_TPMSUpdateState3 m3 : 16|8@1+ (1,0) [0|0] "" Vector__XXX
 SG_ VCSEC_KeyfobStagingProgress m4 : 8|7@1+ (1,0) [0|0] "" Vector__XXX
 SG_ VCSEC_TPMSStagingProgress0 m0 : 8|7@1+ (1,0) [0|0] "" Vector__XXX
 SG_ VCSEC_TPMSStagingProgress1 m1 : 8|7@1+ (1,0) [0|0] "" Vector__XXX
 SG_ VCSEC_TPMSStagingProgress2 m2 : 8|7@1+ (1,0) [0|0] "" Vector__XXX
 SG_ VCSEC_TPMSStagingProgress3 m3 : 8|7@1+ (1,0) [0|0] "" Vector__XXX
 SG_ VCSEC_peripheralOTAStatusIndex M : 0|3@1+ (1,0) [0|0] "" Vector__XXX

BO_ 1089 VC_pcsInterface: 8 Vector__XXX
 SG_ VC_pcsInterfaceChecksum : 56|8@1+ (1,0) [0|0] "" Vector__XXX
 SG_ VC_pcsInterfaceCounter : 50|4@1+ (1,0) [0|0] "" Vector__XXX
 SG_ VC_pcsInterfaceMuxIndex M : 48|1@1+ (1,0) [0|0] "" Vector__XXX
 SG_ VC_LVBatteryCannotSupportVehicle m0 : 47|1@1+ (1,0) [0|0] "" Vector__XXX
 SG_ VC_goodForPCSPowerCycle m0 : 46|1@1+ (1,0) [0|0] "" Vector__XXX
 SG_ VC_lvBatteryDischargeRequest m1 : 42|1@1+ (1,0) [0|0] "" Vector__XXX
 SG_ VC_lvHwProtSelfTestActive m1 : 41|1@1+ (1,0) [0|0] "" Vector__XXX
 SG_ VC_defaultPcsLVVoltageTarget m1 : 28|13@1+ (0.01,0) [0|0] "" Vector__XXX
 SG_ VC_pcsLVMaxVoltageLimit m0 : 27|13@1+ (0.01,0) [0|0] "" Vector__XXX
 SG_ VC_pcsLVMaxDchrgCurrentLimit m1 : 16|12@1+ (0.1,0) [0|0] "" Vector__XXX
 SG_ VC_pcsLVMinVoltageLimit m0 : 13|13@1+ (0.01,0) [0|0] "" Vector__XXX
 SG_ VC_pcsLVVoltageTarget m0 : 0|13@1+ (0.01,0) [0|0] "" Vector__XXX
 SG_ VC_pcsResistanceFiltered m1 : 0|16@1+ (0.01,0) [0|0] "" Vector__XXX

BO_ 1091 VC_pcsManagement: 6 Vector__XXX
 SG_ VC_dcdcLVInputPowerLimit m0 : 36|8@1+ (50,0) [0|0] "" Vector__XXX
 SG_ VC_dcdcLVVoltageTargetMin m0 : 26|10@1+ (0.1,0) [0|0] "" Vector__XXX
 SG_ VC_dcdcLVVoltageTargetMax m0 : 16|10@1+ (0.1,0) [0|0] "" Vector__XXX
 SG_ VC_pcsManagementMuxIndex M : 12|1@1+ (1,0) [0|0] "" Vector__XXX
 SG_ VC_pcsManagementCounter : 8|4@1+ (1,0) [0|0] "" Vector__XXX
 SG_ VC_pcsManagementChecksum : 0|8@1+ (1,0) [0|0] "" Vector__XXX

BO_ 1106 BMS_voltageRegGain: 3 Vector__XXX
 SG_ BMS_driveGainKi : 10|11@1+ (1,0) [0|0] "" Vector__XXX
 SG_ BMS_driveGainKp : 0|10@1+ (8,0) [0|0] "" Vector__XXX

BO_ 1107 VEH_billing: 4 Vector__XXX
 SG_ VEH_pricebookId : 0|32@1+ (1,0) [0|0] "" Vector__XXX

BO_ 1114 VCRIGHT_AP_hvacState10Hz: 8 Vector__XXX
 SG_ VCRIGHT_AP_solarFluxOnLeftWindow m1 : 56|8@1+ (5,0) [0|0] "" Vector__XXX
 SG_ VCRIGHT_AP_tempDuctDefrost m0 : 56|8@1+ (0.5,-22) [0|0] "" Vector__XXX
 SG_ VCRIGHT_AP_hvacMassflowTarget m0 : 48|8@1+ (1,0) [0|0] "" Vector__XXX
 SG_ VCRIGHT_AP_solarFluxOnRightWindow m1 : 48|8@1+ (5,0) [0|0] "" Vector__XXX
 SG_ VCRIGHT_AP_hvacEstimateWindshieldRH m0 : 40|8@1+ (1,0) [0|0] "" Vector__XXX
 SG_ VCRIGHT_AP_turnCameraFanOffReason m1 : 38|3@1+ (1,0) [0|0] "" Vector__XXX
 SG_ VCRIGHT_AP_hvacAirDistributionMode m0 : 37|3@1+ (1,0) [0|0] "" Vector__XXX
 SG_ VCRIGHT_AP_turnForwardCameraHeaterOnReason m1 : 34|4@1+ (1,0) [0|0] "" Vector__XXX
 SG_ VCRIGHT_AP_hvacRecircDoorPercent m0 : 31|6@1+ (1.6,0) [0|0] "" Vector__XXX
 SG_ VCRIGHT_ah_defogSystemState m1 : 31|3@1+ (1,0) [0|0] "" Vector__XXX
 SG_ VCRIGHT_AP_cameraFanDutyRequest m1 : 24|7@1+ (1,0) [0|0] "" Vector__XXX
 SG_ VCRIGHT_AP_cabinTempSideGlassLeft m0 : 23|8@1+ (0.5,-40) [0|0] "" Vector__XXX
 SG_ VCRIGHT_ah_defoggingTimeNeeded m1 : 19|5@1+ (1,0) [0|0] "" Vector__XXX
 SG_ VCRIGHT_AP_cabinTempSideGlassRight m0 : 15|8@1+ (0.5,-40) [0|0] "" Vector__XXX
 SG_ VCRIGHT_ah_hvacFaultSurvivabilityTime m1 : 14|5@1+ (10,0) [0|0] "" Vector__XXX
 SG_ VCRIGHT_AP_cameraDefogType m1 : 11|3@1+ (1,0) [0|0] "" Vector__XXX
 SG_ VCRIGHT_AP_cabinTempWindshield m0 : 7|8@1+ (0.5,-40) [0|0] "" Vector__XXX
 SG_ VCRIGHT_AP_hvacModelInitStatus m0 : 4|3@1+ (1,0) [0|0] "" Vector__XXX
 SG_ VCRIGHT_AP_hvacFlashFoggingDetected m0 : 3|1@1+ (1,0) [0|0] "" Vector__XXX
 SG_ VCRIGHT_AP_autoDefogAvailable m0 : 2|1@1+ (1,0) [0|0] "" Vector__XXX
 SG_ VCRIGHT_AP_cameraTurnOnTime m1 : 2|9@1+ (5,0) [0|0] "" Vector__XXX
 SG_ VCRIGHT_AP_hvacState10HzIndex M : 0|2@1+ (1,0) [0|0] "" Vector__XXX

BO_ 1115 VCRIGHT_AP_hvacState0Point1Hz: 2 Vector__XXX
 SG_ VCRIGHT_AP_VOCPurgeRunCount m0 : 2|10@1+ (1,0) [0|0] "" Vector__XXX
 SG_ VCRIGHT_AP_hvacState0Point1HzIndex M : 0|1@1+ (1,0) [0|0] "" Vector__XXX

BO_ 1138 BMS_chargeInfo: 8 Vector__XXX
 SG_ BMS_useChargeTimeEstimate : 59|1@1+ (1,0) [0|0] "" Vector__XXX
 SG_ BMS_timeToTripPlanChargingTarget : 48|11@1+ (1,0) [0|0] "" Vector__XXX
 SG_ BMS_timeToFinishHeatForCharge : 40|7@1+ (5,0) [0|0] "" Vector__XXX
 SG_ BMS_chargeCurrentLimitMode : 35|5@1+ (1,0) [0|0] "" Vector__XXX
 SG_ BMS_userChargeCurrentLimitMode : 32|3@1+ (1,0) [0|0] "" Vector__XXX
 SG_ BMS_vehicleChargeDcCurrentLimit : 20|12@1+ (0.5,0) [0|0] "" Vector__XXX
 SG_ BMS_voltageRegCurrentTarget : 8|12@1+ (0.5,0) [0|0] "" Vector__XXX
 SG_ BMS_acChargePowerSample : 0|8@1+ (0.1,0) [0|0] "" Vector__XXX

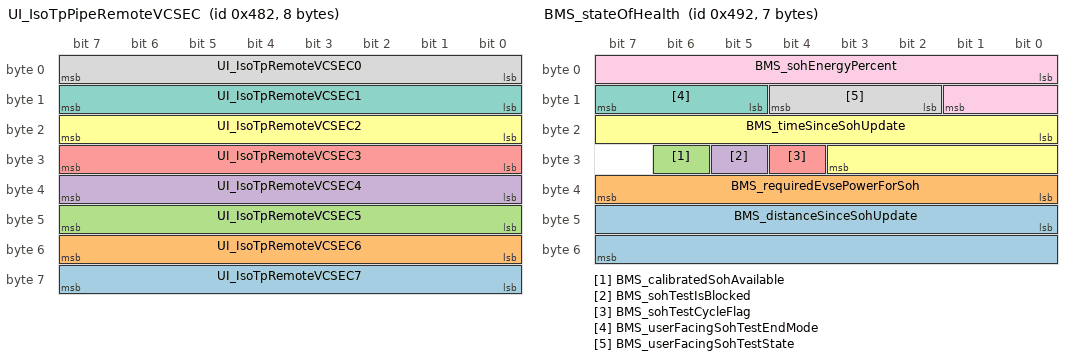
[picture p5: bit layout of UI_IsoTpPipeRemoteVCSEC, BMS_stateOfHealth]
BO_ 1154 UI_IsoTpPipeRemoteVCSEC: 8 Vector__XXX
 SG_ UI_IsoTpRemoteVCSEC7 : 63|8@0+ (1,0) [0|0] "" Vector__XXX
 SG_ UI_IsoTpRemoteVCSEC6 : 55|8@0+ (1,0) [0|0] "" Vector__XXX
 SG_ UI_IsoTpRemoteVCSEC5 : 47|8@0+ (1,0) [0|0] "" Vector__XXX
 SG_ UI_IsoTpRemoteVCSEC4 : 39|8@0+ (1,0) [0|0] "" Vector__XXX
 SG_ UI_IsoTpRemoteVCSEC3 : 31|8@0+ (1,0) [0|0] "" Vector__XXX
 SG_ UI_IsoTpRemoteVCSEC2 : 23|8@0+ (1,0) [0|0] "" Vector__XXX
 SG_ UI_IsoTpRemoteVCSEC1 : 15|8@0+ (1,0) [0|0] "" Vector__XXX
 SG_ UI_IsoTpRemoteVCSEC0 : 7|8@0+ (1,0) [0|0] "" Vector__XXX

BO_ 1170 BMS_stateOfHealth: 7 Vector__XXX
 SG_ BMS_distanceSinceSohUpdate : 40|16@1+ (1,0) [0|0] "" Vector__XXX
 SG_ BMS_requiredEvsePowerForSoh : 32|8@1+ (0.125,0) [0|0] "" Vector__XXX
 SG_ BMS_calibratedSohAvailable : 30|1@1+ (1,0) [0|0] "" Vector__XXX
 SG_ BMS_sohTestIsBlocked : 29|1@1+ (1,0) [0|0] "" Vector__XXX
 SG_ BMS_sohTestCycleFlag : 28|1@1+ (1,0) [0|0] "" Vector__XXX
 SG_ BMS_timeSinceSohUpdate : 16|12@1+ (1,0) [0|0] "" Vector__XXX
 SG_ BMS_userFacingSohTestEndMode : 13|3@1+ (1,0) [0|0] "" Vector__XXX
 SG_ BMS_userFacingSohTestState : 10|3@1+ (1,0) [0|0] "" Vector__XXX
 SG_ BMS_sohEnergyPercent : 0|10@1+ (0.1,0) [0|0] "" Vector__XXX

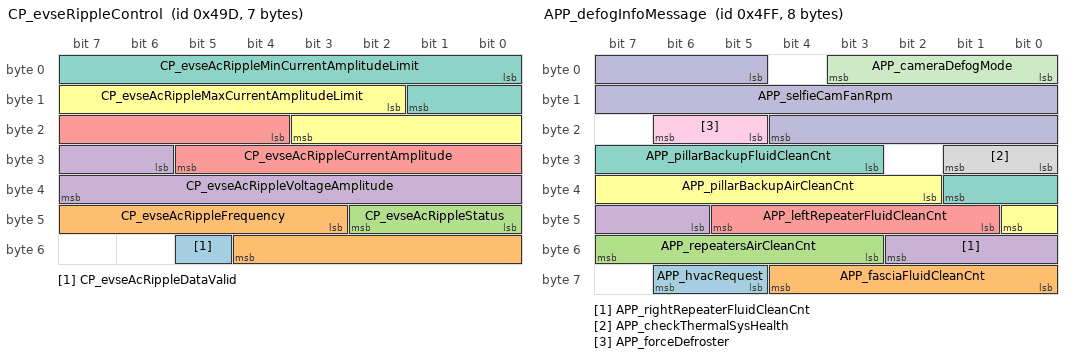
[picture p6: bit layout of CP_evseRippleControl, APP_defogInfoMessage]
BO_ 1181 CP_evseRippleControl: 7 Vector__XXX
 SG_ CP_evseAcRippleDataValid : 53|1@1+ (1,0) [0|0] "" Vector__XXX
 SG_ CP_evseAcRippleFrequency : 43|10@1+ (1,0) [0|0] "" Vector__XXX
 SG_ CP_evseAcRippleStatus : 40|3@1+ (1,0) [0|0] "" Vector__XXX
 SG_ CP_evseAcRippleVoltageAmplitude : 30|10@1+ (1,0) [0|0] "" Vector__XXX
 SG_ CP_evseAcRippleCurrentAmplitude : 20|10@1+ (1,0) [0|0] "" Vector__XXX
 SG_ CP_evseAcRippleMaxCurrentAmplitudeLimit : 10|10@1+ (1,0) [0|0] "" Vector__XXX
 SG_ CP_evseAcRippleMinCurrentAmplitudeLimit : 0|10@1+ (1,0) [0|0] "" Vector__XXX

BO_ 1267 UI_frontSeatRequests: 4 Vector__XXX
 SG_ UI_seatAdjustmentSource : 24|3@1+ (1,0) [0|0] "" Vector__XXX
 SG_ UI_frontRightSeatLumbarOut : 23|1@1+ (1,0) [0|0] "" Vector__XXX
 SG_ UI_frontRightSeatLumbarIn : 22|1@1+ (1,0) [0|0] "" Vector__XXX
 SG_ UI_frontLeftSeatLumbarOut : 21|1@1+ (1,0) [0|0] "" Vector__XXX
 SG_ UI_frontLeftSeatLumbarIn : 20|1@1+ (1,0) [0|0] "" Vector__XXX
 SG_ UI_frontRightSeatLumbarDown : 19|1@1+ (1,0) [0|0] "" Vector__XXX
 SG_ UI_frontRightSeatLumbarUp : 18|1@1+ (1,0) [0|0] "" Vector__XXX
 SG_ UI_frontLeftSeatLumbarDown : 17|1@1+ (1,0) [0|0] "" Vector__XXX
 SG_ UI_frontLeftSeatLumbarUp : 16|1@1+ (1,0) [0|0] "" Vector__XXX
 SG_ UI_frontLeftSeatLiftDown : 15|1@1+ (1,0) [0|0] "" Vector__XXX
 SG_ UI_frontLeftSeatLiftUp : 14|1@1+ (1,0) [0|0] "" Vector__XXX
 SG_ UI_frontRightSeatLiftDown : 13|1@1+ (1,0) [0|0] "" Vector__XXX
 SG_ UI_frontRightSeatLiftUp : 12|1@1+ (1,0) [0|0] "" Vector__XXX
 SG_ UI_frontLeftSeatTiltDown : 11|1@1+ (1,0) [0|0] "" Vector__XXX
 SG_ UI_frontLeftSeatTiltUp : 10|1@1+ (1,0) [0|0] "" Vector__XXX
 SG_ UI_frontRightSeatTiltDown : 9|1@1+ (1,0) [0|0] "" Vector__XXX
 SG_ UI_frontRightSeatTiltUp : 8|1@1+ (1,0) [0|0] "" Vector__XXX
 SG_ UI_frontLeftSeatBackrestForward : 7|1@1+ (1,0) [0|0] "" Vector__XXX
 SG_ UI_frontLeftSeatBackrestBack : 6|1@1+ (1,0) [0|0] "" Vector__XXX
 SG_ UI_frontRightSeatBackrestForward : 5|1@1+ (1,0) [0|0] "" Vector__XXX
 SG_ UI_frontRightSeatBackrestBack : 4|1@1+ (1,0) [0|0] "" Vector__XXX
 SG_ UI_frontLeftSeatTrackBack : 3|1@1+ (1,0) [0|0] "" Vector__XXX
 SG_ UI_frontLeftSeatTrackForward : 2|1@1+ (1,0) [0|0] "" Vector__XXX
 SG_ UI_frontRightSeatTrackBack : 1|1@1+ (1,0) [0|0] "" Vector__XXX
 SG_ UI_frontRightSeatTrackForward : 0|1@1+ (1,0) [0|0] "" Vector__XXX

BO_ 1279 APP_defogInfoMessage: 8 Vector__XXX
 SG_ APP_hvacRequest : 61|2@1+ (1,0) [0|0] "" Vector__XXX
 SG_ APP_fasciaFluidCleanCnt : 56|5@1+ (1,0) [0|0] "" Vector__XXX
 SG_ APP_repeatersAirCleanCnt : 51|5@1+ (1,0) [0|0] "" Vector__XXX
 SG_ APP_rightRepeaterFluidCleanCnt : 46|5@1+ (1,0) [0|0] "" Vector__XXX
 SG_ APP_leftRepeaterFluidCleanCnt : 41|5@1+ (1,0) [0|0] "" Vector__XXX
 SG_ APP_pillarBackupAirCleanCnt : 34|7@1+ (1,0) [0|0] "" Vector__XXX
 SG_ APP_pillarBackupFluidCleanCnt : 27|7@1+ (1,0) [0|0] "" Vector__XXX
 SG_ APP_checkThermalSysHealth : 24|2@1+ (1,0) [0|0] "" Vector__XXX
 SG_ APP_forceDefroster : 21|2@1+ (1,0) [0|0] "" Vector__XXX
 SG_ APP_selfieCamFanRpm : 5|16@1+ (1,0) [0|0] "" Vector__XXX
 SG_ APP_cameraDefogMode : 0|4@1+ (1,0) [0|0] "" Vector__XXX

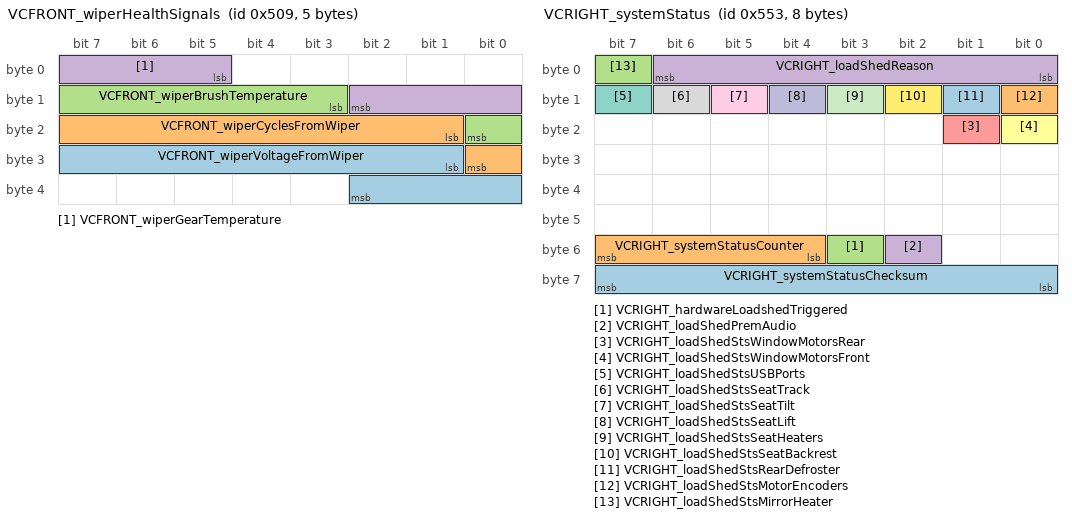
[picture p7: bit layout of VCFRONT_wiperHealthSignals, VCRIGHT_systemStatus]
BO_ 1289 VCFRONT_wiperHealthSignals: 5 Vector__XXX
 SG_ VCFRONT_wiperVoltageFromWiper : 25|10@1+ (0.01,8) [0|0] "" Vector__XXX
 SG_ VCFRONT_wiperCyclesFromWiper : 17|8@1+ (6000,0) [0|0] "" Vector__XXX
 SG_ VCFRONT_wiperBrushTemperature : 11|6@1+ (1.6,100) [0|0] "" Vector__XXX
 SG_ VCFRONT_wiperGearTemperature : 5|6@1+ (1,40) [0|0] "" Vector__XXX

BO_ 1304 VCRIGHT_alertCleared: 2 Vector__XXX
 SG_ VCRIGHT_alertClearedID : 0|10@1+ (1,0) [0|0] "" Vector__XXX

BO_ 1314 VCLEFT_alertCleared: 2 Vector__XXX
 SG_ VCLEFT_alertClearedID : 0|10@1+ (1,0) [0|0] "" Vector__XXX

BO_ 1321 SCCM_bootID: 8 Vector__XXX
 SG_ SCCM_firmwareType : 48|2@1+ (1,0) [0|0] "" Vector__XXX
 SG_ SCCM_usageID : 32|16@1+ (1,0) [0|0] "" Vector__XXX
 SG_ SCCM_assemblyID : 24|8@1+ (1,0) [0|0] "" Vector__XXX
 SG_ SCCM_pcbaID : 16|8@1+ (1,0) [0|0] "" Vector__XXX
 SG_ SCCM_componentID : 0|16@1+ (1,0) [0|0] "" Vector__XXX

BO_ 1327 GTW_epochTimeGtw: 8 Vector__XXX
 SG_ GTW_epoch_ns : 7|64@0+ (1,0) [0|0] "" Vector__XXX

BO_ 1349 VCFRONT_systemStatus: 8 Vector__XXX
 SG_ VCFRONT_systemStatusChecksum : 56|8@1+ (1,0) [0|0] "" Vector__XXX
 SG_ VCFRONT_systemStatusCounter : 52|4@1+ (1,0) [0|0] "" Vector__XXX
 SG_ VCFRONT_loadShedAutoPilot m2 : 51|1@1+ (1,0) [0|0] "" Vector__XXX
 SG_ VCFRONT_loadShedUI m2 : 50|1@1+ (1,0) [0|0] "" Vector__XXX
 SG_ VCFRONT_LVUnhealthyVehicleLoadShedActive m1 : 46|1@1+ (1,0) [0|0] "" Vector__XXX
 SG_ VCFRONT_HVFaultLoadShedStateDBG m1 : 44|2@1+ (1,0) [0|0] "" Vector__XXX
 SG_ VCFRONT_loadShedPCSLeakyBktCtDBG m2 : 44|6@1+ (100,0) [0|0] "" Vector__XXX
 SG_ VCFRONT_DIVehLoadShedActive m1 : 43|1@1+ (1,0) [0|0] "" Vector__XXX
 SG_ VCFRONT_anyVehicleLoadShedActive m1 : 42|1@1+ (1,0) [0|0] "" Vector__XXX
 SG_ VCFRONT_factoryVehicleLoadShedActive m1 : 41|1@1+ (1,0) [0|0] "" Vector__XXX
 SG_ VCFRONT_HVFaultVehicleLoadShedActive m1 : 40|1@1+ (1,0) [0|0] "" Vector__XXX
 SG_ VCFRONT_vcrightVoltage m0 : 40|12@1+ (0.005443676098,0) [0|0] "" Vector__XXX
 SG_ VCFRONT_postCrashVehicleLoadShedActive m1 : 39|1@1+ (1,0) [0|0] "" Vector__XXX
 SG_ VCFRONT_HVFaultVehicleLoadShedRequest m1 : 38|1@1+ (1,0) [0|0] "" Vector__XXX
 SG_ VCFRONT_loadShedBackStopBktCntDBG m2 : 38|5@1+ (0.05,0) [0|0] "" Vector__XXX
 SG_ VCFRONT_loadShedTAS m2 : 37|1@1+ (1,0) [0|0] "" Vector__XXX
 SG_ VCFRONT_loadShedPCSMIATriggerDBG m2 : 36|1@1+ (1,0) [0|0] "" Vector__XXX
 SG_ VCFRONT_vehicleLoadShedStage m1 : 36|2@1+ (1,0) [0|0] "" Vector__XXX
 SG_ VCFRONT_loadShedGTWDownstrmRails m2 : 35|1@1+ (1,0) [0|0] "" Vector__XXX
 SG_ VCFRONT_loadShedPcs m2 : 33|1@1+ (1,0) [0|0] "" Vector__XXX
 SG_ VCFRONT_DCDCSaturationLoadShedStage m1 : 28|5@1+ (1,0) [0|0] "" Vector__XXX
 SG_ VCFRONT_vcleftVoltage m0 : 28|12@1+ (0.005443676098,0) [0|0] "" Vector__XXX
 SG_ VCFRONT_loadShedAhLeakyBktCntDBG m2 : 23|9@1+ (0.001,0) [0|0] "" Vector__XXX
 SG_ VCFRONT_VCLeftEFuseLoadShedStage m1 : 20|5@1+ (1,0) [0|0] "" Vector__XXX
 SG_ VCFRONT_IBSCurrentRMS_loadShed m2 : 16|7@1+ (0.05,0) [0|0] "" Vector__XXX
 SG_ VCFRONT_vcrightCurrent m0 : 16|12@1+ (0.05,0) [0|0] "" Vector__XXX
 SG_ VCFRONT_loadShedStsMCUGraphics m2 : 15|1@1+ (1,0) [0|0] "" Vector__XXX
 SG_ VCFRONT_loadShedStsAPGlassHeater m2 : 14|1@1+ (1,0) [0|0] "" Vector__XXX
 SG_ VCFRONT_loadShedStsBatteryPump m2 : 13|1@1+ (1,0) [0|0] "" Vector__XXX
 SG_ VCFRONT_VCRightEFuseLoadShedStage m1 : 12|5@1+ (1,0) [0|0] "" Vector__XXX
 SG_ VCFRONT_loadShedPCSSatTriggerDBG m2 : 12|1@1+ (1,0) [0|0] "" Vector__XXX
 SG_ VCFRONT_loadShedHVDownTriggerDBG m2 : 11|1@1+ (1,0) [0|0] "" Vector__XXX
 SG_ VCFRONT_loadShedMCUAudio m2 : 10|1@1+ (1,0) [0|0] "" Vector__XXX
 SG_ VCFRONT_loadShedStsPTPump m2 : 6|1@1+ (1,0) [0|0] "" Vector__XXX
 SG_ VCFRONT_vcleftCurrent m0 : 4|12@1+ (0.05,0) [0|0] "" Vector__XXX
 SG_ VCFRONT_loadShedReason m1 : 3|9@1+ (1,0) [0|0] "" Vector__XXX
 SG_ VCFRONT_loadShedStsCondenserFan m2 : 3|1@1+ (1,0) [0|0] "" Vector__XXX
 SG_ VCFRONT_systemStatusMuxIndex M : 0|2@1+ (1,0) [0|0] "" Vector__XXX

BO_ 1362 VCLEFT_systemStatus: 8 Vector__XXX
 SG_ VCLEFT_systemStatusChecksum : 56|8@1+ (1,0) [0|0] "" Vector__XXX
 SG_ VCLEFT_systemStatusCounter : 52|4@1+ (1,0) [0|0] "" Vector__XXX
 SG_ VCLEFT_alcoholInterlockState : 22|2@1+ (1,0) [0|0] "" Vector__XXX
 SG_ VCLEFT_loadShedStsWindowMotorsRear : 21|1@1+ (1,0) [0|0] "" Vector__XXX
 SG_ VCLEFT_loadShedStsWindowMotorsFront : 20|1@1+ (1,0) [0|0] "" Vector__XXX
 SG_ VCLEFT_loadShedStsUSBPorts : 19|1@1+ (1,0) [0|0] "" Vector__XXX
 SG_ VCLEFT_loadShedStsSTWUpDown : 18|1@1+ (1,0) [0|0] "" Vector__XXX
 SG_ VCLEFT_loadShedStsSTWInOut : 17|1@1+ (1,0) [0|0] "" Vector__XXX
 SG_ VCLEFT_loadShedStsSeatTrack : 16|1@1+ (1,0) [0|0] "" Vector__XXX
 SG_ VCLEFT_loadShedStsSeatTilt : 15|1@1+ (1,0) [0|0] "" Vector__XXX
 SG_ VCLEFT_loadShedStsSeatLift : 14|1@1+ (1,0) [0|0] "" Vector__XXX
 SG_ VCLEFT_loadShedStsSeatHeaters : 13|1@1+ (1,0) [0|0] "" Vector__XXX
 SG_ VCLEFT_loadShedStsSeatBackrest : 12|1@1+ (1,0) [0|0] "" Vector__XXX
 SG_ VCLEFT_loadShedStsMotorEncoders : 11|1@1+ (1,0) [0|0] "" Vector__XXX
 SG_ VCLEFT_loadShedStsMirrorHeater : 10|1@1+ (1,0) [0|0] "" Vector__XXX
 SG_ VCLEFT_loadShedStsLiftgate : 9|1@1+ (1,0) [0|0] "" Vector__XXX
 SG_ VCLEFT_loadShedStsHVACBlower : 8|1@1+ (1,0) [0|0] "" Vector__XXX
 SG_ VCLEFT_loadShedSts12VAUXLoads : 7|1@1+ (1,0) [0|0] "" Vector__XXX
 SG_ VCLEFT_loadShedReason : 0|7@1+ (1,0) [0|0] "" Vector__XXX

BO_ 1363 VCRIGHT_systemStatus: 8 Vector__XXX
 SG_ VCRIGHT_systemStatusChecksum : 56|8@1+ (1,0) [0|0] "" Vector__XXX
 SG_ VCRIGHT_systemStatusCounter : 52|4@1+ (1,0) [0|0] "" Vector__XXX
 SG_ VCRIGHT_hardwareLoadshedTriggered : 51|1@1+ (1,0) [0|0] "" Vector__XXX
 SG_ VCRIGHT_loadShedPremAudio : 50|1@1+ (1,0) [0|0] "" Vector__XXX
 SG_ VCRIGHT_loadShedStsWindowMotorsRear : 17|1@1+ (1,0) [0|0] "" Vector__XXX
 SG_ VCRIGHT_loadShedStsWindowMotorsFront : 16|1@1+ (1,0) [0|0] "" Vector__XXX
 SG_ VCRIGHT_loadShedStsUSBPorts : 15|1@1+ (1,0) [0|0] "" Vector__XXX
 SG_ VCRIGHT_loadShedStsSeatTrack : 14|1@1+ (1,0) [0|0] "" Vector__XXX
 SG_ VCRIGHT_loadShedStsSeatTilt : 13|1@1+ (1,0) [0|0] "" Vector__XXX
 SG_ VCRIGHT_loadShedStsSeatLift : 12|1@1+ (1,0) [0|0] "" Vector__XXX
 SG_ VCRIGHT_loadShedStsSeatHeaters : 11|1@1+ (1,0) [0|0] "" Vector__XXX
 SG_ VCRIGHT_loadShedStsSeatBackrest : 10|1@1+ (1,0) [0|0] "" Vector__XXX
 SG_ VCRIGHT_loadShedStsRearDefroster : 9|1@1+ (1,0) [0|0] "" Vector__XXX
 SG_ VCRIGHT_loadShedStsMotorEncoders : 8|1@1+ (1,0) [0|0] "" Vector__XXX
 SG_ VCRIGHT_loadShedStsMirrorHeater : 7|1@1+ (1,0) [0|0] "" Vector__XXX
 SG_ VCRIGHT_loadShedReason : 0|7@1+ (1,0) [0|0] "" Vector__XXX

BO_ 1364 PMR_mfgData: 7 Vector__XXX
 SG_ PMR_processorDieIdY : 44|12@1+ (1,0) [0|0] "" Vector__XXX
 SG_ PMR_processorDieIdX : 32|12@1+ (1,0) [0|0] "" Vector__XXX
 SG_ PMR_processorDieIdWafer : 24|8@1+ (1,0) [0|0] "" Vector__XXX
 SG_ PMR_processorDieIdLot : 0|24@1+ (1,0) [0|0] "" Vector__XXX

BO_ 1524 PMR_bootID: 8 Vector__XXX
 SG_ PMR_firmwareType : 63|8@0+ (1,0) [0|0] "" Vector__XXX
 SG_ PMR_usageID : 39|16@0+ (1,0) [0|0] "" Vector__XXX
 SG_ PMR_assemblyID : 31|8@0+ (1,0) [0|0] "" Vector__XXX
 SG_ PMR_pcbaID : 23|8@0+ (1,0) [0|0] "" Vector__XXX
 SG_ PMR_componentID : 7|16@0+ (1,0) [0|0] "" Vector__XXX

BO_ 1536 UDS_vcfrontRequest: 8 Vector__XXX
 SG_ UDS_vcfrontRequestData : 7|64@0+ (1,0) [0|0] "" Vector__XXX

BO_ 1537 VCFRONT_udsResponse: 8 Vector__XXX
 SG_ VCFRONT_udsResponseData : 7|64@0+ (1,0) [0|0] "" Vector__XXX

BO_ 1541 UDS_difRequest: 8 Vector__XXX
 SG_ UDS_difRequestData : 7|64@0+ (1,0) [0|0] "" Vector__XXX

BO_ 1542 UDS_dirRequest: 8 Vector__XXX
 SG_ UDS_dirRequestData : 7|64@0+ (1,0) [0|0] "" Vector__XXX

BO_ 1544 UDS_vcrightRequest: 8 Vector__XXX
 SG_ UDS_vcrightRequestData_L : 39|32@0+ (1,0) [0|0] "" Vector__XXX
 SG_ UDS_vcrightRequestData_H : 7|32@0+ (1,0) [0|0] "" Vector__XXX

BO_ 1545 VCRIGHT_udsResponse: 8 Vector__XXX
 SG_ VCRIGHT_udsResponseData_L : 39|32@0+ (1,0) [0|0] "" Vector__XXX
 SG_ VCRIGHT_udsResponseData_H : 7|32@0+ (1,0) [0|0] "" Vector__XXX

BO_ 1546 UDS_vcsecRequest: 8 Vector__XXX
 SG_ UDS_vcsecRequestData : 7|64@0+ (1,0) [0|0] "" Vector__XXX

BO_ 1547 VCSEC_udsResponse: 8 Vector__XXX
 SG_ VCSEC_udsResponseData : 7|64@0+ (1,0) [0|0] "" Vector__XXX

BO_ 1550 UDS_cpRequest: 8 Vector__XXX
 SG_ UDS_cpRequestData : 7|64@0+ (1,0) [0|0] "" Vector__XXX

BO_ 1558 DIR_udsResponse: 8 Vector__XXX
 SG_ DIR_udsResponseData : 7|64@0+ (1,0) [0|0] "" Vector__XXX

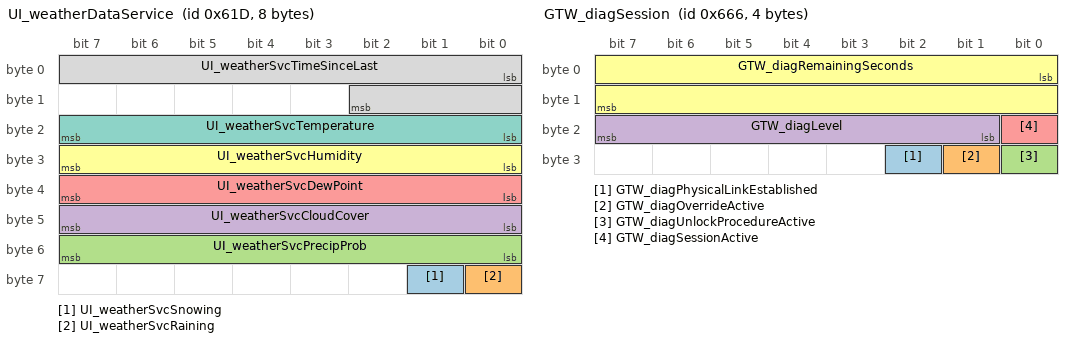
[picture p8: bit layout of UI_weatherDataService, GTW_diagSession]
BO_ 1565 UI_weatherDataService: 8 Vector__XXX
 SG_ UI_weatherSvcSnowing : 57|1@1+ (1,0) [0|0] "" Vector__XXX
 SG_ UI_weatherSvcRaining : 56|1@1+ (1,0) [0|0] "" Vector__XXX
 SG_ UI_weatherSvcPrecipProb : 48|8@1+ (0.5,0) [0|0] "" Vector__XXX
 SG_ UI_weatherSvcCloudCover : 40|8@1+ (0.5,0) [0|0] "" Vector__XXX
 SG_ UI_weatherSvcDewPoint : 32|8@1+ (0.5,0) [0|0] "" Vector__XXX
 SG_ UI_weatherSvcHumidity : 24|8@1+ (0.5,0) [0|0] "" Vector__XXX
 SG_ UI_weatherSvcTemperature : 16|8@1- (0.5,0) [0|0] "" Vector__XXX
 SG_ UI_weatherSvcTimeSinceLast : 0|11@1+ (1,0) [0|0] "" Vector__XXX

BO_ 1566 CP_udsResponse: 8 Vector__XXX
 SG_ CP_udsResponseData : 7|64@0+ (1,0) [0|0] "" Vector__XXX

BO_ 1570 UDS_vcleftRequest: 8 Vector__XXX
 SG_ UDS_vcleftRequestData_L : 39|32@0+ (1,0) [0|0] "" Vector__XXX
 SG_ UDS_vcleftRequestData_H : 7|32@0+ (1,0) [0|0] "" Vector__XXX

BO_ 1571 VCLEFT_udsResponse: 8 Vector__XXX
 SG_ VCLEFT_udsResponseData_L : 39|32@0+ (1,0) [0|0] "" Vector__XXX
 SG_ VCLEFT_udsResponseData_H : 7|32@0+ (1,0) [0|0] "" Vector__XXX

BO_ 1572 UDS_epblRequest: 8 Vector__XXX
 SG_ UDS_epblRequestData_L : 39|32@0+ (1,0) [0|0] "" Vector__XXX
 SG_ UDS_epblRequestData_H : 7|32@0+ (1,0) [0|0] "" Vector__XXX

BO_ 1573 EPBL_udsResponse: 8 Vector__XXX
 SG_ EPBL_udsResponseData_L : 39|32@0+ (1,0) [0|0] "" Vector__XXX
 SG_ EPBL_udsResponseData_H : 7|32@0+ (1,0) [0|0] "" Vector__XXX

BO_ 1574 UDS_epbrRequest: 8 Vector__XXX
 SG_ UDS_epbrRequestData_L : 39|32@0+ (1,0) [0|0] "" Vector__XXX
 SG_ UDS_epbrRequestData_H : 7|32@0+ (1,0) [0|0] "" Vector__XXX

BO_ 1575 EPBR_udsResponse: 8 Vector__XXX
 SG_ EPBR_udsResponseData_L : 39|32@0+ (1,0) [0|0] "" Vector__XXX
 SG_ EPBR_udsResponseData_H : 7|32@0+ (1,0) [0|0] "" Vector__XXX

BO_ 1576 UDS_pcsRequest: 8 Vector__XXX
 SG_ UDS_pcsRequestData : 7|64@0+ (1,0) [0|0] "" Vector__XXX

BO_ 1577 PCS_udsResponse: 8 Vector__XXX
 SG_ PCS_udsResponseData : 7|64@0+ (1,0) [0|0] "" Vector__XXX

BO_ 1588 CMPD_bootID: 8 Vector__XXX
 SG_ CMPD_bootFirmwareType : 63|8@0+ (1,0) [0|0] "" Vector__XXX
 SG_ CMPD_bootUsageId : 39|16@0+ (1,0) [0|0] "" Vector__XXX
 SG_ CMPD_bootAssemblyId : 31|8@0+ (1,0) [0|0] "" Vector__XXX
 SG_ CMPD_bootPcbaId : 23|8@0+ (1,0) [0|0] "" Vector__XXX
 SG_ CMPD_bootComponentId : 7|16@0+ (1,0) [0|0] "" Vector__XXX

BO_ 1617 RCM_udsResponse: 8 Vector__XXX
 SG_ RCM_udsResponseData : 7|64@0+ (1,0) [0|0] "" Vector__XXX

BO_ 1638 GTW_diagSession: 4 Vector__XXX
 SG_ GTW_diagPhysicalLinkEstablished : 26|1@1+ (1,0) [0|0] "" Vector__XXX
 SG_ GTW_diagOverrideActive : 25|1@1+ (1,0) [0|0] "" Vector__XXX
 SG_ GTW_diagUnlockProcedureActive : 24|1@1+ (1,0) [0|0] "" Vector__XXX
 SG_ GTW_diagLevel : 17|7@1+ (1,0) [0|0] "" Vector__XXX
 SG_ GTW_diagSessionActive : 16|1@1+ (1,0) [0|0] "" Vector__XXX
 SG_ GTW_diagRemainingSeconds : 0|16@1+ (1,0) [0|0] "" Vector__XXX

BO_ 1651 VEH_isoTpToEvse: 8 Vector__XXX
 SG_ VEH_isoTpToEvseData : 0|64@1+ (1,0) [0|0] "" Vector__XXX

BO_ 1655 VC_LVBMS_statusHigh: 8 Vector__XXX
 SG_ VC_LVBMS_minBrickVoltageIndex m4 : 56|8@1+ (1,0) [0|0] "" Vector__XXX
 SG_ VC_LVBMS_MOSTemperature m0 : 50|12@1+ (0.5,-50) [0|0] "" Vector__XXX
 SG_ VC_LVBMS_maxAllowedDischargeCurrent m3 : 50|13@1+ (0.1,0) [0|0] "" Vector__XXX
 SG_ VC_LVBMS_estimatedPackOcv m2 : 48|16@1+ (0.001,0) [0|0] "" Vector__XXX
 SG_ VC_LVBMS_packTemperature m0 : 41|9@1+ (0.5,-50) [0|0] "" Vector__XXX
 SG_ VC_LVBMS_maxBrickVoltageIndex m1 : 40|8@1+ (1,0) [0|0] "" Vector__XXX
 SG_ VC_LVBMS_minBrickVoltage m4 : 40|13@1+ (0.001,0) [0|0] "" Vector__XXX
 SG_ VC_LVBMS_maxAllowedChargeCurrent m3 : 37|13@1+ (0.1,0) [0|0] "" Vector__XXX
 SG_ VC_LVPackCurrent m2 : 34|14@1- (0.1,0) [0|0] "" Vector__XXX
 SG_ VC_LVBMS_packVoltage m0 : 25|16@1+ (0.001,0) [0|0] "" Vector__XXX
 SG_ VC_LVBMS_avgBrickVoltage m4 : 24|13@1+ (0.001,0) [0|0] "" Vector__XXX
 SG_ VC_LVBMS_maxBrickVoltage m1 : 24|13@1+ (0.001,0) [0|0] "" Vector__XXX
 SG_ VC_LVPackChargeCurrentLimit m2 : 22|12@1+ (0.1,0) [0|0] "" Vector__XXX
 SG_ VC_LVBMS_cellAndArcProtEnabled m4 : 19|1@1+ (1,0) [0|0] "" Vector__XXX
 SG_ VC_LVBMS_currentTarget m3 : 19|18@1+ (0.001,-122) [0|0] "" Vector__XXX
 SG_ VC_LVBMS_chargeType m4 : 16|3@1+ (1,0) [0|0] "" Vector__XXX
 SG_ VC_LVBMS_LINWakeDisabled m4 : 14|1@1+ (1,0) [0|0] "" Vector__XXX
 SG_ VC_LVBMS_VehicleState m4 : 12|2@1+ (1,0) [0|0] "" Vector__XXX
 SG_ VC_LVBMS_MOSState m4 : 10|2@1+ (1,0) [0|0] "" Vector__XXX
 SG_ VC_LVBMS_ECPAState m4 : 8|2@1+ (1,0) [0|0] "" Vector__XXX
 SG_ VC_LVBMS_sumCellVoltage m1 : 8|16@1+ (0.001,0) [0|0] "" Vector__XXX
 SG_ VC_totalLVLoadCurrent m2 : 8|14@1- (0.1,0) [0|0] "" Vector__XXX
 SG_ VC_LVBMS_EnterHibernationCommand m4 : 7|1@1+ (1,0) [0|0] "" Vector__XXX
 SG_ VC_LVBMS_ResetLVBMSCommand m4 : 6|1@1+ (1,0) [0|0] "" Vector__XXX
 SG_ VC_LVBMS_ClearHistoricFaultCommand m4 : 5|1@1+ (1,0) [0|0] "" Vector__XXX
 SG_ VC_LVBMS_ClearErrorCntrCommand m4 : 4|1@1+ (1,0) [0|0] "" Vector__XXX
 SG_ VC_LVBMS_MOSCommand m4 : 3|1@1+ (1,0) [0|0] "" Vector__XXX
 SG_ VC_LVBMS_packCurrent m0 : 3|22@1+ (0.001,-2000) [0|0] "" Vector__XXX
 SG_ VC_LVBMS_voltageTarget m3 : 3|16@1+ (0.001,0) [0|0] "" Vector__XXX
 SG_ VC_lvbmsStatusHighIndex M : 0|3@1+ (1,0) [0|0] "" Vector__XXX

BO_ 1662 EVSE_isoTpToVeh: 8 Vector__XXX
 SG_ EVSE_isoTpToVehData : 0|64@1+ (1,0) [0|0] "" Vector__XXX

BO_ 1666 HVP_hvpFaults: 8 Vector__XXX
 SG_ HVP_hvpFaultsChecksum : 56|8@1+ (1,0) [0|0] "" Vector__XXX
 SG_ HVP_hvpFaultsCounter : 52|4@1+ (1,0) [0|0] "" Vector__XXX
 SG_ HVP_shuntOverTemperature : 51|1@1+ (1,0) [0|0] "" Vector__XXX
 SG_ HVP_bmbBmbDataIntegrityLossFault : 49|1@1+ (1,0) [0|0] "" Vector__XXX
 SG_ HVP_bmbCommunicationFault : 48|1@1+ (1,0) [0|0] "" Vector__XXX
 SG_ HVP_configMinorVersion : 40|8@1+ (1,0) [0|0] "" Vector__XXX
 SG_ HVP_configMajorVersion : 32|8@1+ (1,0) [0|0] "" Vector__XXX
 SG_ HVP_hvilStatus : 30|2@1+ (1,0) [0|0] "" Vector__XXX
 SG_ HVP_hvilFault : 26|1@1+ (1,0) [0|0] "" Vector__XXX
 SG_ HVP_unsupportedBmbAsicType : 25|1@1+ (1,0) [0|0] "" Vector__XXX
 SG_ HVP_missingPartNumber : 24|1@1+ (1,0) [0|0] "" Vector__XXX
 SG_ HVP_missingConfigBlock : 23|1@1+ (1,0) [0|0] "" Vector__XXX
 SG_ HVP_fastVshFailureFault : 22|1@1+ (1,0) [0|0] "" Vector__XXX
 SG_ HVP_gpoRequestActive : 21|1@1+ (1,0) [0|0] "" Vector__XXX
 SG_ HVP_battery12vDisconnected : 20|1@1+ (1,0) [0|0] "" Vector__XXX
 SG_ HVP_packNegativeCtrArcFault : 19|1@1+ (1,0) [0|0] "" Vector__XXX
 SG_ HVP_packPositiveCtrArcFault : 18|1@1+ (1,0) [0|0] "" Vector__XXX
 SG_ HVP_ensMiaFault : 17|1@1+ (1,0) [0|0] "" Vector__XXX
 SG_ HVP_crashEvent : 16|1@1+ (1,0) [0|0] "" Vector__XXX
 SG_ HVP_packVoltageMismatchFault : 15|1@1+ (1,0) [0|0] "" Vector__XXX
 SG_ HVP_supply12vFault : 14|1@1+ (1,0) [0|0] "" Vector__XXX
 SG_ HVP_fcContactorHwFault : 13|1@1+ (1,0) [0|0] "" Vector__XXX
 SG_ HVP_packContactorHwFault : 12|1@1+ (1,0) [0|0] "" Vector__XXX
 SG_ HVP_pyroMiaWarning : 11|1@1+ (1,0) [0|0] "" Vector__XXX
 SG_ HVP_pyroMiaFault : 10|1@1+ (1,0) [0|0] "" Vector__XXX
 SG_ HVP_shuntHwAndBmsMiaFault : 9|1@1+ (1,0) [0|0] "" Vector__XXX
 SG_ HVP_shuntHwMiaFault : 8|1@1+ (1,0) [0|0] "" Vector__XXX
 SG_ HVP_cpFault : 7|1@1+ (1,0) [0|0] "" Vector__XXX
 SG_ HVP_pcsMiaFault : 6|1@1+ (1,0) [0|0] "" Vector__XXX
 SG_ HVP_cpMiaFault : 5|1@1+ (1,0) [0|0] "" Vector__XXX
 SG_ HVP_bmsMiaFault : 4|1@1+ (1,0) [0|0] "" Vector__XXX
 SG_ HVP_primaryBmbMiaFault : 3|1@1+ (1,0) [0|0] "" Vector__XXX
 SG_ HVP_underVoltageFault : 2|1@1+ (1,0) [0|0] "" Vector__XXX
 SG_ HVP_overVoltageFault : 1|1@1+ (1,0) [0|0] "" Vector__XXX
 SG_ HVP_overTemperatureFault : 0|1@1+ (1,0) [0|0] "" Vector__XXX

BO_ 1698 PMR_stateLowFlow: 4 Vector__XXX
 SG_ PMR_fluidError : 24|7@1+ (0.01,0) [0|0] "" Vector__XXX
 SG_ PMR_deltahsError : 16|7@1+ (0.01,0) [0|0] "" Vector__XXX
 SG_ PMR_hs2Error : 8|7@1+ (0.01,0) [0|0] "" Vector__XXX
 SG_ PMR_hs1Error : 0|7@1+ (0.01,0) [0|0] "" Vector__XXX

BO_ 1723 UDS_sdcrRequest: 8 Vector__XXX
 SG_ UDS_sdcrRequestData : 7|64@0+ (1,0) [0|0] "" Vector__XXX

BO_ 1736 EPBL_statsOutput: 8 Vector__XXX
 SG_ EPBL_staticApplyCountsVeryCold m0 : 44|20@1+ (1,0) [0|0] "" Vector__XXX
 SG_ EPBL_staticApplyCountsCold m0 : 24|20@1+ (1,0) [0|0] "" Vector__XXX
 SG_ EPBL_dynamicApplyCounts m1 : 8|32@1+ (1,0) [0|0] "" Vector__XXX
 SG_ EPBL_staticApplyCounts m0 : 2|20@1+ (1,0) [0|0] "" Vector__XXX
 SG_ EPBL_statsOutputIndex M : 0|2@1+ (1,0) [0|0] "" Vector__XXX

BO_ 1768 EPBR_statsOutput: 8 Vector__XXX
 SG_ EPBR_staticApplyCountsVeryCold m0 : 44|20@1+ (1,0) [0|0] "" Vector__XXX
 SG_ EPBR_staticApplyCountsCold m0 : 24|20@1+ (1,0) [0|0] "" Vector__XXX
 SG_ EPBR_dynamicApplyCounts m1 : 8|32@1+ (1,0) [0|0] "" Vector__XXX
 SG_ EPBR_staticApplyCounts m0 : 2|20@1+ (1,0) [0|0] "" Vector__XXX
 SG_ EPBR_statsOutputIndex M : 0|2@1+ (1,0) [0|0] "" Vector__XXX

BO_ 1799 DBG_intrusionSensor: 8 Vector__XXX
 SG_ DBG_IS_Reserved_06 : 23|1@1+ (1,0) [0|0] "" Vector__XXX
 SG_ DBG_IS_Siren_Alarm_Cycles : 22|1@1+ (1,0) [0|0] "" Vector__XXX
 SG_ DBG_IS_Siren_Tone : 21|1@1+ (1,0) [0|0] "" Vector__XXX
 SG_ DBG_IS_Siren_Beep_Duration : 19|2@1+ (1,0) [0|0] "" Vector__XXX
 SG_ DBG_IS_Siren_Beep_Type : 17|2@1+ (1,0) [0|0] "" Vector__XXX
 SG_ DBG_IS_Siren_Alarm : 16|1@1+ (1,0) [0|0] "" Vector__XXX
 SG_ DBG_IS_Reserved_05 : 15|1@1+ (1,0) [0|0] "" Vector__XXX
 SG_ DBG_IS_Reserved_04 : 14|1@1+ (1,0) [0|0] "" Vector__XXX
 SG_ DBG_IS_Reserved_03 : 13|1@1+ (1,0) [0|0] "" Vector__XXX
 SG_ DBG_IS_Reserved_02 : 12|1@1+ (1,0) [0|0] "" Vector__XXX
 SG_ DBG_IS_Vehicles_Settings : 8|4@1+ (1,0) [0|0] "" Vector__XXX
 SG_ DBG_IS_Suspensions : 7|1@1+ (1,0) [0|0] "" Vector__XXX
 SG_ DBG_IS_Reserved_01 : 6|1@1+ (1,0) [0|0] "" Vector__XXX
 SG_ DBG_IS_Window : 5|1@1+ (1,0) [0|0] "" Vector__XXX
 SG_ DBG_IS_Heater : 4|1@1+ (1,0) [0|0] "" Vector__XXX
 SG_ DBG_IS_Air_Conditioned : 3|1@1+ (1,0) [0|0] "" Vector__XXX
 SG_ DBG_IS_USS_Operation : 0|3@1+ (1,0) [0|0] "" Vector__XXX

BO_ 1800 EPBL_CPULoad: 5 Vector__XXX
 SG_ EPBL_CPULoad1000msTask : 32|8@1+ (1,0) [0|0] "" Vector__XXX
 SG_ EPBL_CPULoad100msTask : 24|8@1+ (1,0) [0|0] "" Vector__XXX
 SG_ EPBL_CPULoad10msTask : 16|8@1+ (1,0) [0|0] "" Vector__XXX
 SG_ EPBL_CPULoad1msTask : 8|8@1+ (1,0) [0|0] "" Vector__XXX
 SG_ EPBL_CPULoadTotal : 0|8@1+ (1,0) [0|0] "" Vector__XXX

BO_ 1802 VCLEFT_logging0point1Hz: 5 Vector__XXX
 SG_ VCLEFT_leftBrakeLightCurrentSenseState m0 : 37|3@1+ (1,0) [0|0] "" Vector__XXX
 SG_ VCLEFT_leftBrakeLightCurrent m0 : 28|9@1+ (0.005,0) [0|0] "" Vector__XXX
 SG_ VCLEFT_leftRearTurnLightCurrentSenseState m0 : 24|3@1+ (1,0) [0|0] "" Vector__XXX
 SG_ VCLEFT_leftRearTurnLightCurrent m0 : 14|9@1+ (0.002,0) [0|0] "" Vector__XXX
 SG_ VCLEFT_leftTailLightCurrentSenseState m0 : 11|3@1+ (1,0) [0|0] "" Vector__XXX
 SG_ VCLEFT_leftTailLightCurrent m0 : 2|9@1+ (0.002,0) [0|0] "" Vector__XXX
 SG_ VCLEFT_logging0point1HzIndex M : 0|1@1+ (1,0) [0|0] "" Vector__XXX

BO_ 1803 VCRIGHT_logging0point1Hz: 8 Vector__XXX
 SG_ VCRIGHT_exteriorNightLightCurrentSenseState m0 : 61|3@1+ (1,0) [0|0] "" Vector__XXX
 SG_ VCRIGHT_leftTrunkLightCurrentSenseState m1 : 61|3@1+ (1,0) [0|0] "" Vector__XXX
 SG_ VCRIGHT_cabinTempBreathLevelF5minCooling m8 : 56|8@1+ (0.5,-40) [0|0] "" Vector__XXX
 SG_ VCRIGHT_hvacIntakeEndStop m3 : 56|8@1+ (0.02,0) [0|0] "" Vector__XXX
 SG_ VCRIGHT_hvacIntakeZeroStop m4 : 56|8@1+ (0.02,0) [0|0] "" Vector__XXX
 SG_ VCRIGHT_interiorCameraLedCurrent m6 : 56|8@1+ (8,0) [0|0] "" Vector__XXX
 SG_ VCRIGHT_airDistributionModeAdjustmentFactor m2 : 55|9@1+ (0.001,1) [0|0] "" Vector__XXX
 SG_ VCRIGHT_exteriorNightLightCurrent m0 : 52|9@1+ (0.002,0) [0|0] "" Vector__XXX
 SG_ VCRIGHT_leftTrunkLightCurrent m1 : 52|9@1+ (0.002,0) [0|0] "" Vector__XXX
 SG_ VCRIGHT_rearFogLightCurrentSenseState m1 : 49|3@1+ (1,0) [0|0] "" Vector__XXX
 SG_ VCRIGHT_rightTailLightCurrentSenseState m0 : 49|3@1+ (1,0) [0|0] "" Vector__XXX
 SG_ VCRIGHT_cabinTempBreathLevelF5minHeating m8 : 48|8@1+ (0.5,-40) [0|0] "" Vector__XXX
 SG_ VCRIGHT_hvacLowerModeEndStop m3 : 48|8@1+ (0.02,0) [0|0] "" Vector__XXX
 SG_ VCRIGHT_hvacLowerModeZeroStop m4 : 48|8@1+ (0.02,0) [0|0] "" Vector__XXX
 SG_ VCRIGHT_silentWakeRecordCount m6 : 48|5@1+ (1,0) [0|0] "" Vector__XXX
 SG_ VCRIGHT_cabinTempBreathLevelFOff m2 : 47|8@1+ (0.5,-40) [0|0] "" Vector__XXX
 SG_ VCRIGHT_cabinFilterHealthScore m2 : 40|7@1+ (1,0) [0|0] "" Vector__XXX
 SG_ VCRIGHT_cabinTempBreathLevelF10minCooling m8 : 40|8@1+ (0.5,-40) [0|0] "" Vector__XXX
 SG_ VCRIGHT_hvacUpperModeEndStop m3 : 40|8@1+ (0.02,0) [0|0] "" Vector__XXX
 SG_ VCRIGHT_hvacUpperModeZeroStop m4 : 40|8@1+ (0.02,0) [0|0] "" Vector__XXX
 SG_ VCRIGHT_rearFogLightCurrent m1 : 40|9@1+ (0.002,0) [0|0] "" Vector__XXX
 SG_ VCRIGHT_rightTailLightCurrent m0 : 40|9@1+ (0.002,0) [0|0] "" Vector__XXX
 SG_ VCRIGHT_thsSolarIrradianceLimp m6 : 40|8@1+ (5,0) [0|0] "" Vector__XXX
 SG_ VCRIGHT_rightBrakeLightCurrentSenseState m0 : 37|3@1+ (1,0) [0|0] "" Vector__XXX
 SG_ VCRIGHT_rightTrunkLightCurrentSenseState m1 : 37|3@1+ (1,0) [0|0] "" Vector__XXX
 SG_ VCRIGHT_cabinTempBreathLevelF10minHeating m8 : 32|8@1+ (0.5,-40) [0|0] "" Vector__XXX
 SG_ VCRIGHT_hepaFilterHealthScore m2 : 32|7@1+ (1,0) [0|0] "" Vector__XXX
 SG_ VCRIGHT_hvacRHVaneEndStop m3 : 32|8@1+ (0.02,0) [0|0] "" Vector__XXX
 SG_ VCRIGHT_hvacRHVaneZeroStop m4 : 32|8@1+ (0.02,0) [0|0] "" Vector__XXX
 SG_ VCRIGHT_thsCabinWaterMassLimp m6 : 32|8@1+ (0.5,0) [0|0] "" Vector__XXX
 SG_ VCRIGHT_rightBrakeLightCurrent m0 : 28|9@1+ (0.005,0) [0|0] "" Vector__XXX
 SG_ VCRIGHT_rightTrunkLightCurrent m1 : 28|9@1+ (0.002,0) [0|0] "" Vector__XXX
 SG_ VCRIGHT_rightPTCCompromisedRod m2 : 27|3@1+ (1,0) [0|0] "" Vector__XXX
 SG_ VCRIGHT_leftLiftgateTailLightCurrentSenseState m0 : 25|3@1+ (1,0) [0|0] "" Vector__XXX
 SG_ VCRIGHT_reverseLightCurrentSenseState m1 : 25|3@1+ (1,0) [0|0] "" Vector__XXX
 SG_ VCRIGHT_hvacLHVaneEndStop m3 : 24|8@1+ (0.02,0) [0|0] "" Vector__XXX
 SG_ VCRIGHT_hvacLHVaneZeroStop m4 : 24|8@1+ (0.02,0) [0|0] "" Vector__XXX
 SG_ VCRIGHT_leftPTCCompromisedRod m2 : 24|3@1+ (1,0) [0|0] "" Vector__XXX
 SG_ VCRIGHT_tempIncarCabinDeep m8 : 24|8@1+ (0.5,-40) [0|0] "" Vector__XXX
 SG_ VCRIGHT_thsTempLimp m6 : 24|8@1+ (0.5,-40) [0|0] "" Vector__XXX
 SG_ VCRIGHT_rightRearTurnLightCurrentSenseState m0 : 22|3@1+ (1,0) [0|0] "" Vector__XXX
 SG_ VCRIGHT_HEPAAirFilterLifeRemaining m2 : 17|7@1+ (1,0) [0|0] "" Vector__XXX
 SG_ VCRIGHT_cabinProbeTempLimp m6 : 16|8@1+ (0.5,-40) [0|0] "" Vector__XXX
 SG_ VCRIGHT_evapLoadInRecirc m8 : 16|8@1+ (35,0) [0|0] "" Vector__XXX
 SG_ VCRIGHT_hvacRHBleedEndStop m3 : 16|8@1+ (0.02,0) [0|0] "" Vector__XXX
 SG_ VCRIGHT_hvacRHBleedZeroStop m4 : 16|8@1+ (0.02,0) [0|0] "" Vector__XXX
 SG_ VCRIGHT_reverseLightCurrent m1 : 16|9@1+ (0.002,0) [0|0] "" Vector__XXX
 SG_ VCRIGHT_licensePlateLightCurrentSenseState m1 : 13|3@1+ (1,0) [0|0] "" Vector__XXX
 SG_ VCRIGHT_rightRearTurnLightCurrent m0 : 13|9@1+ (0.002,0) [0|0] "" Vector__XXX
 SG_ VCRIGHT_cabinAirFilterLifeRemaining m2 : 10|7@1+ (1,0) [0|0] "" Vector__XXX
 SG_ VCRIGHT_ambientTempLimp m6 : 8|8@1+ (0.5,-40) [0|0] "" Vector__XXX
 SG_ VCRIGHT_evapCondensateMass m7 : 8|8@1+ (2,0) [0|0] "" Vector__XXX
 SG_ VCRIGHT_evapLoadInFresh m8 : 8|8@1+ (35,0) [0|0] "" Vector__XXX
 SG_ VCRIGHT_hvacLHBleedEndStop m3 : 8|8@1+ (0.02,0) [0|0] "" Vector__XXX
 SG_ VCRIGHT_hvacLHBleedZeroStop m4 : 8|8@1+ (0.02,0) [0|0] "" Vector__XXX
 SG_ VCRIGHT_foggingMonitorRuntime m9 : 4|12@1+ (10,0) [0|0] "" Vector__XXX
 SG_ VCRIGHT_leftLiftgateTailLightCurrent m0 : 4|7@1+ (0.002,0) [0|0] "" Vector__XXX
 SG_ VCRIGHT_licensePlateLightCurrent m1 : 4|9@1+ (0.002,0) [0|0] "" Vector__XXX
 SG_ VCRIGHT_logging0point1HzIndex M : 0|4@1+ (1,0) [0|0] "" Vector__XXX

BO_ 1810 BMS_packTemperatureMeasurements: 8 Vector__XXX
 SG_ BMS_packTemperature12 m3 : 48|16@1- (0.01,0) [0|0] "" Vector__XXX
 SG_ BMS_packTemperature15 m4 : 48|16@1- (0.01,0) [0|0] "" Vector__XXX
 SG_ BMS_packTemperature18 m5 : 48|16@1- (0.01,0) [0|0] "" Vector__XXX
 SG_ BMS_packTemperature3 m0 : 48|16@1- (0.01,0) [0|0] "" Vector__XXX
 SG_ BMS_packTemperature6 m1 : 48|16@1- (0.01,0) [0|0] "" Vector__XXX
 SG_ BMS_packTemperature9 m2 : 48|16@1- (0.01,0) [0|0] "" Vector__XXX
 SG_ BMS_packTemperature11 m3 : 32|16@1- (0.01,0) [0|0] "" Vector__XXX
 SG_ BMS_packTemperature14 m4 : 32|16@1- (0.01,0) [0|0] "" Vector__XXX
 SG_ BMS_packTemperature17 m5 : 32|16@1- (0.01,0) [0|0] "" Vector__XXX
 SG_ BMS_packTemperature2 m0 : 32|16@1- (0.01,0) [0|0] "" Vector__XXX
 SG_ BMS_packTemperature5 m1 : 32|16@1- (0.01,0) [0|0] "" Vector__XXX
 SG_ BMS_packTemperature8 m2 : 32|16@1- (0.01,0) [0|0] "" Vector__XXX
 SG_ BMS_packTemperature1 m0 : 16|16@1- (0.01,0) [0|0] "" Vector__XXX
 SG_ BMS_packTemperature10 m3 : 16|16@1- (0.01,0) [0|0] "" Vector__XXX
 SG_ BMS_packTemperature13 m4 : 16|16@1- (0.01,0) [0|0] "" Vector__XXX
 SG_ BMS_packTemperature16 m5 : 16|16@1- (0.01,0) [0|0] "" Vector__XXX
 SG_ BMS_packTemperature4 m1 : 16|16@1- (0.01,0) [0|0] "" Vector__XXX
 SG_ BMS_packTemperature7 m2 : 16|16@1- (0.01,0) [0|0] "" Vector__XXX
 SG_ BMS_packTemperatureCounter : 14|2@1+ (1,0) [0|0] "" Vector__XXX
 SG_ BMS_packTemperatureStatus12 m3 : 12|2@1+ (1,0) [0|0] "" Vector__XXX
 SG_ BMS_packTemperatureStatus15 m4 : 12|2@1+ (1,0) [0|0] "" Vector__XXX
 SG_ BMS_packTemperatureStatus18 m5 : 12|2@1+ (1,0) [0|0] "" Vector__XXX
 SG_ BMS_packTemperatureStatus3 m0 : 12|2@1+ (1,0) [0|0] "" Vector__XXX
 SG_ BMS_packTemperatureStatus6 m1 : 12|2@1+ (1,0) [0|0] "" Vector__XXX
 SG_ BMS_packTemperatureStatus9 m2 : 12|2@1+ (1,0) [0|0] "" Vector__XXX
 SG_ BMS_packTemperatureStatus11 m3 : 10|2@1+ (1,0) [0|0] "" Vector__XXX
 SG_ BMS_packTemperatureStatus14 m4 : 10|2@1+ (1,0) [0|0] "" Vector__XXX
 SG_ BMS_packTemperatureStatus17 m5 : 10|2@1+ (1,0) [0|0] "" Vector__XXX
 SG_ BMS_packTemperatureStatus2 m0 : 10|2@1+ (1,0) [0|0] "" Vector__XXX
 SG_ BMS_packTemperatureStatus5 m1 : 10|2@1+ (1,0) [0|0] "" Vector__XXX
 SG_ BMS_packTemperatureStatus8 m2 : 10|2@1+ (1,0) [0|0] "" Vector__XXX
 SG_ BMS_packTemperatureStatus1 m0 : 8|2@1+ (1,0) [0|0] "" Vector__XXX
 SG_ BMS_packTemperatureStatus10 m3 : 8|2@1+ (1,0) [0|0] "" Vector__XXX
 SG_ BMS_packTemperatureStatus13 m4 : 8|2@1+ (1,0) [0|0] "" Vector__XXX
 SG_ BMS_packTemperatureStatus16 m5 : 8|2@1+ (1,0) [0|0] "" Vector__XXX
 SG_ BMS_packTemperatureStatus4 m1 : 8|2@1+ (1,0) [0|0] "" Vector__XXX
 SG_ BMS_packTemperatureStatus7 m2 : 8|2@1+ (1,0) [0|0] "" Vector__XXX
 SG_ BMS_packTemperatureMultiplexer M : 0|8@1+ (1,0) [0|0] "" Vector__XXX

BO_ 1815 RCM_imuOffsets: 7 Vector__XXX
 SG_ RCM_CGZdistance m2 : 40|16@1+ (1,-32768) [0|0] "" Vector__XXX
 SG_ RCM_rollRateOffset m0 : 40|16@1- (0.0001,0) [0|0] "" Vector__XXX
 SG_ RCM_verticalAccelOffset m1 : 40|16@1- (0.00125,0) [0|0] "" Vector__XXX
 SG_ RCM_CGYdistance m2 : 24|16@1+ (1,-32768) [0|0] "" Vector__XXX
 SG_ RCM_lateralAccelOffset m1 : 24|16@1- (0.00125,0) [0|0] "" Vector__XXX
 SG_ RCM_pitchRateOffset m0 : 24|16@1- (0.0001,0) [0|0] "" Vector__XXX
 SG_ RCM_CGXdistance m2 : 8|16@1+ (1,-32768) [0|0] "" Vector__XXX
 SG_ RCM_longitudinalAccelOffset m1 : 8|16@1- (0.00125,0) [0|0] "" Vector__XXX
 SG_ RCM_yawRateOffset m0 : 8|16@1- (0.0001,0) [0|0] "" Vector__XXX
 SG_ RCM_imuOffsetsIndex M : 0|2@1+ (1,0) [0|0] "" Vector__XXX

BO_ 1816 VC_LVBMS_statusLow: 8 Vector__XXX
 SG_ VC_LVBMS_MosfetStuckOpenError m0 : 51|1@1+ (1,0) [0|0] "" Vector__XXX
 SG_ VC_LVBMS_MosfetStuckCloseError m0 : 50|1@1+ (1,0) [0|0] "" Vector__XXX
 SG_ VC_LVBMS_SamplingError m0 : 49|1@1+ (1,0) [0|0] "" Vector__XXX
 SG_ VC_LVBMS_DeepDischargeFlag m0 : 48|1@1+ (1,0) [0|0] "" Vector__XXX
 SG_ VC_LVBMS_SOP m1 : 48|8@1+ (20,0) [0|0] "" Vector__XXX
 SG_ VC_LVBMS_NTCTempDiffWarnLevel1 m0 : 47|1@1+ (1,0) [0|0] "" Vector__XXX
 SG_ VC_LVBMS_MOSStateFault m0 : 46|1@1+ (1,0) [0|0] "" Vector__XXX
 SG_ VC_LVBMS_BalanceCircuitFault m0 : 45|1@1+ (1,0) [0|0] "" Vector__XXX
 SG_ VC_LVBMS_KBValueLostFault m0 : 44|1@1+ (1,0) [0|0] "" Vector__XXX
 SG_ VC_LVBMS_MOSFETOTLevel1 m0 : 43|1@1+ (1,0) [0|0] "" Vector__XXX
 SG_ VC_LVBMS_ChrgOCLevel2 m0 : 42|1@1+ (1,0) [0|0] "" Vector__XXX
 SG_ VC_LVBMS_ChrgOCLevel1 m0 : 41|1@1+ (1,0) [0|0] "" Vector__XXX
 SG_ VC_LVBMS_usableEnergyAvailable m4 : 41|12@1+ (1,0) [0|0] "" Vector__XXX
 SG_ VC_LVBMS_DischrgOCLevel2 m0 : 40|1@1+ (1,0) [0|0] "" Vector__XXX
 SG_ VC_LVBMS_MaxSleepCurrent m3 : 40|16@1+ (0.01,-200) [0|0] "" Vector__XXX
 SG_ VC_LVBMS_MinSleepCurrent m2 : 40|16@1+ (0.01,-200) [0|0] "" Vector__XXX
 SG_ VC_LVBMS_dynamicSOCCorrection m4 : 40|1@1+ (1,0) [0|0] "" Vector__XXX
 SG_ VC_LVBMS_DischrgOCLevel1 m0 : 39|1@1+ (1,0) [0|0] "" Vector__XXX
 SG_ VC_LVBMS_staticSOCCorrection m4 : 39|1@1+ (1,0) [0|0] "" Vector__XXX
 SG_ VC_LVBMS_PackOVLevel2 m0 : 38|1@1+ (1,0) [0|0] "" Vector__XXX
 SG_ VC_LVBMS_PackOVLevel1 m0 : 37|1@1+ (1,0) [0|0] "" Vector__XXX
 SG_ VC_LVBMS_ModuleOTLevel1 m0 : 36|1@1+ (1,0) [0|0] "" Vector__XXX
 SG_ VC_LVBMS_CellUVLevel2 m0 : 35|1@1+ (1,0) [0|0] "" Vector__XXX
 SG_ VC_LVBMS_CellUVLevel1 m0 : 34|1@1+ (1,0) [0|0] "" Vector__XXX
 SG_ VC_LVBMS_CellOVLevel3 m0 : 33|1@1+ (1,0) [0|0] "" Vector__XXX
 SG_ VC_LVBMS_CellOVLevel2 m0 : 32|1@1+ (1,0) [0|0] "" Vector__XXX
 SG_ VC_LVBMS_minCellSOC m4 : 32|7@1+ (1,0) [0|0] "" Vector__XXX
 SG_ VC_LVBMS_CellOVLevel1 m0 : 31|1@1+ (1,0) [0|0] "" Vector__XXX
 SG_ VC_LVBMS_SOH m0 : 24|7@1+ (1,0) [0|0] "" Vector__XXX
 SG_ VC_LVBMS_TimeSlept m1 : 24|24@1+ (1,0) [0|0] "" Vector__XXX
 SG_ VC_LVBMS_maxCellSOC m4 : 24|7@1+ (1,0) [0|0] "" Vector__XXX
 SG_ VC_LVBMS_SOE m0 : 16|7@1+ (1,0) [0|0] "" Vector__XXX
 SG_ VC_LVBMS_AhCharged m2 : 8|32@1+ (0.001,0) [0|0] "" Vector__XXX
 SG_ VC_LVBMS_AhDischarged m3 : 8|32@1+ (0.001,0) [0|0] "" Vector__XXX
 SG_ VC_LVBMS_AvgSleepCurrent m1 : 8|16@1+ (0.01,-200) [0|0] "" Vector__XXX
 SG_ VC_LVBMS_SOC m0 : 8|7@1+ (1,0) [0|0] "" Vector__XXX
 SG_ VC_LVBMS_sumCellVoltageFiltered m4 : 8|16@1+ (0.001,0) [0|0] "" Vector__XXX
 SG_ VC_lvbmsStatusLowIndex M : 0|3@1+ (1,0) [0|0] "" Vector__XXX

BO_ 1824 VCSEC_ecuConfig: 5 Vector__XXX
 SG_ VCSEC_requestForConfig : 33|1@1+ (1,0) [0|0] "" Vector__XXX
 SG_ VCSEC_autoWriteConfig : 32|1@1+ (1,0) [0|0] "" Vector__XXX
 SG_ VCSEC_ECUConfigCRC32 : 0|32@1+ (1,0) [0|0] "" Vector__XXX

BO_ 1828 VCFRONT_loadShedDebugStatus: 3 Vector__XXX
 SG_ VCFRONT_loadShedStsBatteryPump_duty m1 : 16|7@1+ (1,0) [0|0] "" Vector__XXX
 SG_ VCFRONT_loadShedStsCondenserFan_duty m2 : 16|7@1+ (1,0) [0|0] "" Vector__XXX
 SG_ VCFRONT_loadShedStsPTPump_duty m3 : 16|7@1+ (1,0) [0|0] "" Vector__XXX
 SG_ VCFRONT_loadShedReasonAPHeater m0 : 4|9@1+ (1,0) [0|0] "" Vector__XXX
 SG_ VCFRONT_loadShedReasonAutopilot m5 : 4|9@1+ (1,0) [0|0] "" Vector__XXX
 SG_ VCFRONT_loadShedReasonBatteryPump m1 : 4|9@1+ (1,0) [0|0] "" Vector__XXX
 SG_ VCFRONT_loadShedReasonCondenserFan m2 : 4|9@1+ (1,0) [0|0] "" Vector__XXX
 SG_ VCFRONT_loadShedReasonMCUAudio m8 : 4|9@1+ (1,0) [0|0] "" Vector__XXX
 SG_ VCFRONT_loadShedReasonMCUGraphic m7 : 4|9@1+ (1,0) [0|0] "" Vector__XXX
 SG_ VCFRONT_loadShedReasonPCS m9 : 4|9@1+ (1,0) [0|0] "" Vector__XXX
 SG_ VCFRONT_loadShedReasonPTPump m3 : 4|9@1+ (1,0) [0|0] "" Vector__XXX
 SG_ VCFRONT_loadShedReasonTAS m4 : 4|9@1+ (1,0) [0|0] "" Vector__XXX
 SG_ VCFRONT_loadShedReasonUI m6 : 4|9@1+ (1,0) [0|0] "" Vector__XXX
 SG_ VCFRONT_loadShedDebugStatusIndex M : 0|4@1+ (1,0) [0|0] "" Vector__XXX

BO_ 1830 VCLEFT_loadShedDebugStatus: 3 Vector__XXX
 SG_ VCLEFT_loadShedStsHVACBlower_duty m1 : 16|7@1+ (1,0) [0|0] "" Vector__XXX
 SG_ VCLEFT_loadShedReason12VAuxLoads m0 : 8|7@1+ (1,0) [0|0] "" Vector__XXX
 SG_ VCLEFT_loadShedReasonHVACBlower m1 : 8|7@1+ (1,0) [0|0] "" Vector__XXX
 SG_ VCLEFT_loadShedReasonLiftgate m2 : 8|7@1+ (1,0) [0|0] "" Vector__XXX
 SG_ VCLEFT_loadShedReasonMirrorHeater m3 : 8|7@1+ (1,0) [0|0] "" Vector__XXX
 SG_ VCLEFT_loadShedReasonMotorEncoders m4 : 8|7@1+ (1,0) [0|0] "" Vector__XXX
 SG_ VCLEFT_loadShedReasonSTWInOut m10 : 8|7@1+ (1,0) [0|0] "" Vector__XXX
 SG_ VCLEFT_loadShedReasonSTWUpDown m11 : 8|7@1+ (1,0) [0|0] "" Vector__XXX
 SG_ VCLEFT_loadShedReasonSeatBackrest m5 : 8|7@1+ (1,0) [0|0] "" Vector__XXX
 SG_ VCLEFT_loadShedReasonSeatHeaters m7 : 8|7@1+ (1,0) [0|0] "" Vector__XXX
 SG_ VCLEFT_loadShedReasonSeatLift m6 : 8|7@1+ (1,0) [0|0] "" Vector__XXX
 SG_ VCLEFT_loadShedReasonSeatTilt m8 : 8|7@1+ (1,0) [0|0] "" Vector__XXX
 SG_ VCLEFT_loadShedReasonSeatTrack m9 : 8|7@1+ (1,0) [0|0] "" Vector__XXX
 SG_ VCLEFT_loadShedReasonUSBPorts m12 : 8|7@1+ (1,0) [0|0] "" Vector__XXX
 SG_ VCLEFT_loadShedReasonWindowMotorsFront m13 : 8|7@1+ (1,0) [0|0] "" Vector__XXX
 SG_ VCLEFT_loadShedReasonWindowMotorsRear m14 : 8|7@1+ (1,0) [0|0] "" Vector__XXX
 SG_ VCLEFT_loadShedDebugStatusIndex M : 0|4@1+ (1,0) [0|0] "" Vector__XXX

BO_ 1831 VCRIGHT_loadShedDebugStatus: 2 Vector__XXX
 SG_ VCRIGHT_loadShedReasonMirrorHeater m0 : 8|7@1+ (1,0) [0|0] "" Vector__XXX
 SG_ VCRIGHT_loadShedReasonMotorEncoders m1 : 8|7@1+ (1,0) [0|0] "" Vector__XXX
 SG_ VCRIGHT_loadShedReasonPremAudio m2 : 8|7@1+ (1,0) [0|0] "" Vector__XXX
 SG_ VCRIGHT_loadShedReasonRearDefroster m3 : 8|7@1+ (1,0) [0|0] "" Vector__XXX
 SG_ VCRIGHT_loadShedReasonSeatBackrest m4 : 8|7@1+ (1,0) [0|0] "" Vector__XXX
 SG_ VCRIGHT_loadShedReasonSeatHeaters m5 : 8|7@1+ (1,0) [0|0] "" Vector__XXX
 SG_ VCRIGHT_loadShedReasonSeatLift m6 : 8|7@1+ (1,0) [0|0] "" Vector__XXX
 SG_ VCRIGHT_loadShedReasonSeatTilt m7 : 8|7@1+ (1,0) [0|0] "" Vector__XXX
 SG_ VCRIGHT_loadShedReasonSeatTrack m8 : 8|7@1+ (1,0) [0|0] "" Vector__XXX
 SG_ VCRIGHT_loadShedReasonUSBPorts m9 : 8|7@1+ (1,0) [0|0] "" Vector__XXX
 SG_ VCRIGHT_loadShedReasonWindowMotorsFront m10 : 8|7@1+ (1,0) [0|0] "" Vector__XXX
 SG_ VCRIGHT_loadShedReasonWindowMotorsRear m11 : 8|7@1+ (1,0) [0|0] "" Vector__XXX
 SG_ VCRIGHT_loadShedDebugStatusIndex M : 0|4@1+ (1,0) [0|0] "" Vector__XXX

BO_ 1834 BMS_serialNumber: 8 Vector__XXX
 SG_ BMS_packSerialNumberByte07 m0 : 56|8@1+ (1,0) [0|0] "" Vector__XXX
 SG_ BMS_packSerialNumberByte14 m1 : 56|8@1+ (1,0) [0|0] "" Vector__XXX
 SG_ BMS_packSerialNumberByte06 m0 : 48|8@1+ (1,0) [0|0] "" Vector__XXX
 SG_ BMS_packSerialNumberByte13 m1 : 48|8@1+ (1,0) [0|0] "" Vector__XXX
 SG_ BMS_packSerialNumberByte05 m0 : 40|8@1+ (1,0) [0|0] "" Vector__XXX
 SG_ BMS_packSerialNumberByte12 m1 : 40|8@1+ (1,0) [0|0] "" Vector__XXX
 SG_ BMS_packSerialNumberByte04 m0 : 32|8@1+ (1,0) [0|0] "" Vector__XXX
 SG_ BMS_packSerialNumberByte11 m1 : 32|8@1+ (1,0) [0|0] "" Vector__XXX
 SG_ BMS_packSerialNumberByte03 m0 : 24|8@1+ (1,0) [0|0] "" Vector__XXX
 SG_ BMS_packSerialNumberByte10 m1 : 24|8@1+ (1,0) [0|0] "" Vector__XXX
 SG_ BMS_packSerialNumberByte02 m0 : 16|8@1+ (1,0) [0|0] "" Vector__XXX
 SG_ BMS_packSerialNumberByte09 m1 : 16|8@1+ (1,0) [0|0] "" Vector__XXX
 SG_ BMS_packSerialBirthDateBinned m2 : 8|32@1+ (1,0) [0|0] "" Vector__XXX
 SG_ BMS_packSerialNumberByte01 m0 : 8|8@1+ (1,0) [0|0] "" Vector__XXX
 SG_ BMS_packSerialNumberByte08 m1 : 8|8@1+ (1,0) [0|0] "" Vector__XXX
 SG_ BMS_serialNumberMultiplexer M : 0|2@1+ (1,0) [0|0] "" Vector__XXX

BO_ 1847 VCFRONT_LVBMS_info: 7 Vector__XXX
 SG_ VCFRONT_LVBMS_mfgYear m4 : 48|7@1+ (1,2011) [0|0] "" Vector__XXX
 SG_ VCFRONT_LVBMS_SubUsageId m0 : 40|16@1+ (1,0) [0|0] "" Vector__XXX
 SG_ VCFRONT_LVBMS_mfgMonth m4 : 40|4@1+ (1,0) [0|0] "" Vector__XXX
 SG_ VCFRONT_LVBMS_mfgDay m4 : 32|5@1+ (1,0) [0|0] "" Vector__XXX
 SG_ VCFRONT_LVBMS_AppCRC m1 : 24|32@1+ (1,0) [0|0] "" Vector__XXX
 SG_ VCFRONT_LVBMS_AssemblyId m0 : 24|16@1+ (1,0) [0|0] "" Vector__XXX
 SG_ VCFRONT_LVBMS_FWBuildType m3 : 8|8@1+ (1,0) [0|0] "" Vector__XXX
 SG_ VCFRONT_LVBMS_GitHash m2 : 8|16@1+ (1,0) [0|0] "" Vector__XXX
 SG_ VCFRONT_LVBMS_PcbaId m0 : 8|16@1+ (1,0) [0|0] "" Vector__XXX
 SG_ VCFRONT_LVBMS_UsageId m1 : 8|16@1+ (1,0) [0|0] "" Vector__XXX
 SG_ VCFRONT_LVBMS_serialNumber m4 : 8|24@1+ (1,0) [0|0] "" Vector__XXX
 SG_ VCFRONT_LVBMS_InfoIndex M : 0|8@1+ (1,0) [0|0] "" Vector__XXX

BO_ 1849 VCSEC_CPULoad: 5 Vector__XXX
 SG_ VCSEC_CPULoad1000msTask : 32|8@1+ (1,0) [0|0] "" Vector__XXX
 SG_ VCSEC_CPULoad100msTask : 24|8@1+ (1,0) [0|0] "" Vector__XXX
 SG_ VCSEC_CPULoad10msTask : 16|8@1+ (1,0) [0|0] "" Vector__XXX
 SG_ VCSEC_CPULoad1msTask : 8|8@1+ (1,0) [0|0] "" Vector__XXX
 SG_ VCSEC_CPULoadTotal : 0|8@1+ (1,0) [0|0] "" Vector__XXX

BO_ 1850 VC_LVBMS_brickMeasurements: 8 Vector__XXX
 SG_ VC_LVBMS_brickBalancingState2 m1 : 57|1@1+ (1,0) [0|0] "" Vector__XXX
 SG_ VC_LVBMS_brickBalancingState4 m2 : 57|1@1+ (1,0) [0|0] "" Vector__XXX
 SG_ VC_LVBMS_brickBalancingState1 m1 : 56|1@1+ (1,0) [0|0] "" Vector__XXX
 SG_ VC_LVBMS_brickBalancingState3 m2 : 56|1@1+ (1,0) [0|0] "" Vector__XXX
 SG_ VC_LVBMS_brickVoltage4 m0 : 50|13@1+ (0.001,0) [0|0] "" Vector__XXX
 SG_ VC_LVBMS_brickVoltage3 m0 : 37|13@1+ (0.001,0) [0|0] "" Vector__XXX
 SG_ VC_LVBMS_brickBalancingAh2 m1 : 32|24@1+ (0.001,0) [0|0] "" Vector__XXX
 SG_ VC_LVBMS_brickBalancingAh4 m2 : 32|24@1+ (0.001,0) [0|0] "" Vector__XXX
 SG_ VC_LVBMS_brickVoltage2 m0 : 24|13@1+ (0.001,0) [0|0] "" Vector__XXX
 SG_ VC_LVBMS_brickBalancingAh1 m1 : 8|24@1+ (0.001,0) [0|0] "" Vector__XXX
 SG_ VC_LVBMS_brickBalancingAh3 m2 : 8|24@1+ (0.001,0) [0|0] "" Vector__XXX
 SG_ VC_LVBMS_brickVoltage1 m0 : 8|13@1+ (0.001,0) [0|0] "" Vector__XXX
 SG_ VC_LVBMS_brickMeasurementsMultiplexer M : 0|6@1+ (1,0) [0|0] "" Vector__XXX

BO_ 1858 VCBATT1_LVBMS_statusHigh: 8 Vector__XXX
 SG_ VCBATT1_LVBMS_minBrickVoltageIndex m4 : 56|8@1+ (1,0) [0|0] "" Vector__XXX
 SG_ VCBATT1_LVBMS_MOSTemperature m0 : 50|12@1+ (0.5,-50) [0|0] "" Vector__XXX
 SG_ VCBATT1_LVBMS_maxAllowedDischargeCurrent m3 : 50|13@1+ (0.1,0) [0|0] "" Vector__XXX
 SG_ VCBATT1_LVBMS_estimatedPackOcv m2 : 48|16@1+ (0.001,0) [0|0] "" Vector__XXX
 SG_ VCBATT1_LVBMS_packTemperature m0 : 41|9@1+ (0.5,-50) [0|0] "" Vector__XXX
 SG_ VCBATT1_LVBMS_maxBrickVoltageIndex m1 : 40|8@1+ (1,0) [0|0] "" Vector__XXX
 SG_ VCBATT1_LVBMS_minBrickVoltage m4 : 40|13@1+ (0.001,0) [0|0] "" Vector__XXX
 SG_ VCBATT1_LVBMS_maxAllowedChargeCurrent m3 : 37|13@1+ (0.1,0) [0|0] "" Vector__XXX
 SG_ VCBATT1_LVPackCurrent m2 : 34|14@1- (0.1,0) [0|0] "" Vector__XXX
 SG_ VCBATT1_LVBMS_packVoltage m0 : 25|16@1+ (0.001,0) [0|0] "" Vector__XXX
 SG_ VCBATT1_LVBMS_avgBrickVoltage m4 : 24|13@1+ (0.001,0) [0|0] "" Vector__XXX
 SG_ VCBATT1_LVBMS_maxBrickVoltage m1 : 24|13@1+ (0.001,0) [0|0] "" Vector__XXX
 SG_ VCBATT1_LVPackChargeCurrentLimit m2 : 22|12@1+ (0.1,0) [0|0] "" Vector__XXX
 SG_ VCBATT1_LVBMS_cellAndArcProtEnabled m4 : 19|1@1+ (1,0) [0|0] "" Vector__XXX
 SG_ VCBATT1_LVBMS_currentTarget m3 : 19|18@1+ (0.001,-122) [0|0] "" Vector__XXX
 SG_ VCBATT1_LVBMS_chargeType m4 : 16|3@1+ (1,0) [0|0] "" Vector__XXX
 SG_ VCBATT1_LVBMS_LINWakeDisabled m4 : 14|1@1+ (1,0) [0|0] "" Vector__XXX
 SG_ VCBATT1_LVBMS_VehicleState m4 : 12|2@1+ (1,0) [0|0] "" Vector__XXX
 SG_ VCBATT1_LVBMS_MOSState m4 : 10|2@1+ (1,0) [0|0] "" Vector__XXX
 SG_ VCBATT1_LVBMS_ECPAState m4 : 8|2@1+ (1,0) [0|0] "" Vector__XXX
 SG_ VCBATT1_LVBMS_sumCellVoltage m1 : 8|16@1+ (0.001,0) [0|0] "" Vector__XXX
 SG_ VCBATT1_totalLVLoadCurrent m2 : 8|14@1- (0.1,0) [0|0] "" Vector__XXX
 SG_ VCBATT1_LVBMS_EnterHibernationCommand m4 : 7|1@1+ (1,0) [0|0] "" Vector__XXX
 SG_ VCBATT1_LVBMS_ResetLVBMSCommand m4 : 6|1@1+ (1,0) [0|0] "" Vector__XXX
 SG_ VCBATT1_LVBMS_ClearHistoricFaultCommand m4 : 5|1@1+ (1,0) [0|0] "" Vector__XXX
 SG_ VCBATT1_LVBMS_ClearErrorCntrCommand m4 : 4|1@1+ (1,0) [0|0] "" Vector__XXX
 SG_ VCBATT1_LVBMS_MOSCommand m4 : 3|1@1+ (1,0) [0|0] "" Vector__XXX
 SG_ VCBATT1_LVBMS_packCurrent m0 : 3|22@1+ (0.001,-2000) [0|0] "" Vector__XXX
 SG_ VCBATT1_LVBMS_voltageTarget m3 : 3|16@1+ (0.001,0) [0|0] "" Vector__XXX
 SG_ VCBATT1_lvbmsStatusHighIndex M : 0|3@1+ (1,0) [0|0] "" Vector__XXX

BO_ 1864 EPBR_CPULoad: 5 Vector__XXX
 SG_ EPBR_CPULoad1000msTask : 32|8@1+ (1,0) [0|0] "" Vector__XXX
 SG_ EPBR_CPULoad100msTask : 24|8@1+ (1,0) [0|0] "" Vector__XXX
 SG_ EPBR_CPULoad10msTask : 16|8@1+ (1,0) [0|0] "" Vector__XXX
 SG_ EPBR_CPULoad1msTask : 8|8@1+ (1,0) [0|0] "" Vector__XXX
 SG_ EPBR_CPULoadTotal : 0|8@1+ (1,0) [0|0] "" Vector__XXX

BO_ 1870 XCP_pmRequest: 8 Vector__XXX
 SG_ XCP_pmRequestData : 7|64@0+ (1,0) [0|0] "" Vector__XXX

BO_ 1871 PM_xcpResponse: 8 Vector__XXX
 SG_ PM_xcpResponseData : 7|64@0+ (1,0) [0|0] "" Vector__XXX

BO_ 1897 VCBATT1_xcpResponse: 8 Vector__XXX
 SG_ VCBATT1_xcpResponseData : 0|64@1+ (1,0) [0|0] "" Vector__XXX

BO_ 1914 HVP_log1hz: 8 Vector__XXX
 SG_ HVP_shuntAsicChipYCoordinate m0 : 56|8@1+ (1,0) [0|0] "" Vector__XXX
 SG_ HVP_energyReserveAvg m1 : 48|16@1- (0.001,0) [0|0] "" Vector__XXX
 SG_ HVP_shuntAsicChipXCoordinate m0 : 48|8@1+ (1,0) [0|0] "" Vector__XXX
 SG_ HVP_energyReserveMax m1 : 32|16@1- (0.001,0) [0|0] "" Vector__XXX
 SG_ HVP_pyroSquibResistance m0 : 32|16@1+ (0.001,0) [0|0] "" Vector__XXX
 SG_ HVP_energyReserveMin m1 : 16|16@1- (0.001,0) [0|0] "" Vector__XXX
 SG_ HVP_shuntAsicChipWaferNumber m1 : 8|8@1+ (1,0) [0|0] "" Vector__XXX
 SG_ HVP_shuntCurrentAuxLog m0 : 8|24@1- (0.001,0) [0|0] "" Vector__XXX
 SG_ HVP_gpioPcsEnable m1 : 7|1@1+ (1,0) [0|0] "" Vector__XXX
 SG_ HVP_gpioPcsChargePwmEnable m1 : 6|1@1+ (1,0) [0|0] "" Vector__XXX
 SG_ HVP_gpioPcsDcdcPwmEnable m1 : 5|1@1+ (1,0) [0|0] "" Vector__XXX
 SG_ HVP_bmbAsicType m0 : 3|2@1+ (1,0) [0|0] "" Vector__XXX
 SG_ HVP_hvilCalType m1 : 3|2@1+ (1,0) [0|0] "" Vector__XXX
 SG_ HVP_log1HzIndex M : 0|3@1+ (1,0) [0|0] "" Vector__XXX

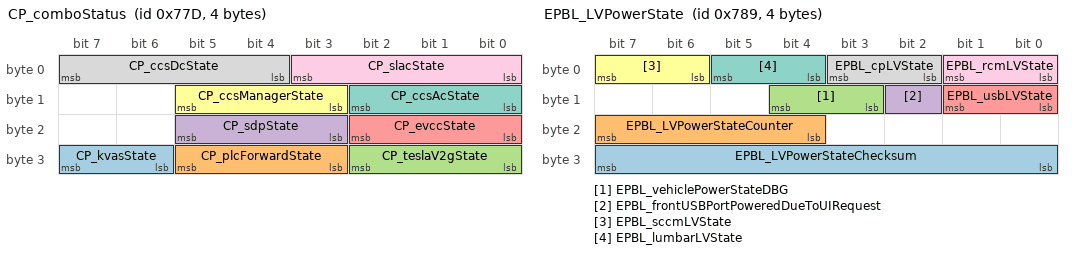
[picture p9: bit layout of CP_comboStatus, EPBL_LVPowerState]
BO_ 1917 CP_comboStatus: 4 Vector__XXX
 SG_ CP_kvasState : 30|2@1+ (1,0) [0|0] "" Vector__XXX
 SG_ CP_plcForwardState : 27|3@1+ (1,0) [0|0] "" Vector__XXX
 SG_ CP_teslaV2gState : 24|3@1+ (1,0) [0|0] "" Vector__XXX
 SG_ CP_sdpState : 19|3@1+ (1,0) [0|0] "" Vector__XXX
 SG_ CP_evccState : 16|3@1+ (1,0) [0|0] "" Vector__XXX
 SG_ CP_ccsManagerState : 11|3@1+ (1,0) [0|0] "" Vector__XXX
 SG_ CP_ccsAcState : 8|3@1+ (1,0) [0|0] "" Vector__XXX
 SG_ CP_ccsDcState : 4|4@1+ (1,0) [0|0] "" Vector__XXX
 SG_ CP_slacState : 0|4@1+ (1,0) [0|0] "" Vector__XXX

BO_ 1928 EPBL_debugOutput: 8 Vector__XXX
 SG_ EPBL_uiNotAvailable m0 : 62|1@1+ (1,0) [0|0] "" Vector__XXX
 SG_ EPBL_driverIsLeavingDisabled m0 : 61|1@1+ (1,0) [0|0] "" Vector__XXX
 SG_ EPBL_slopeParkable m0 : 60|1@1+ (1,0) [0|0] "" Vector__XXX
 SG_ EPBL_epbOpenUnableToPark m0 : 59|1@1+ (1,0) [0|0] "" Vector__XXX
 SG_ EPBL_brakePressHeld m0 : 58|1@1+ (1,0) [0|0] "" Vector__XXX
 SG_ EPBL_esmCaliperRequest m0 : 55|3@1+ (1,0) [0|0] "" Vector__XXX
 SG_ EPBL_12VFilt m1 : 52|9@1+ (0.043549408784,0) [0|0] "" Vector__XXX
 SG_ EPBL_lockoutUnlockCount m0 : 49|6@1+ (1,0) [0|0] "" Vector__XXX
 SG_ EPBL_brakeDiscWipeAccumul m2 : 48|8@1+ (1,0) [0|0] "" Vector__XXX
 SG_ EPBL_lockoutCommandDI m2 : 41|1@1+ (1,0) [0|0] "" Vector__XXX
 SG_ EPBL_lockoutOutputDI m2 : 40|1@1+ (1,0) [0|0] "" Vector__XXX
 SG_ EPBL_pid_error m1 : 40|12@1+ (0.016997132,-37.55274262) [0|0] "" Vector__XXX
 SG_ EPBL_currentVariance m0 : 35|14@1- (0.0007629394535064697,0) [0|0] "" Vector__XXX
 SG_ EPBL_atEndStop m0 : 34|1@1+ (1,0) [0|0] "" Vector__XXX
 SG_ EPBL_oocViolation m0 : 33|1@1+ (1,0) [0|0] "" Vector__XXX
 SG_ EPBL_nFault m0 : 32|1@1+ (1,0) [0|0] "" Vector__XXX
 SG_ EPBL_ramp m1 : 32|8@1+ (0.392157,0) [0|0] "" Vector__XXX
 SG_ EPBL_caliperState m0 : 29|3@1+ (1,0) [0|0] "" Vector__XXX
 SG_ EPBL_filteredCurrentPeak m2 : 28|12@1+ (0.01,0) [0|0] "" Vector__XXX
 SG_ EPBL_pid_duty m1 : 22|10@1- (0.2,0) [0|0] "" Vector__XXX
 SG_ EPBL_pvFilt m0 : 20|9@1+ (0.043549408784,0) [0|0] "" Vector__XXX
 SG_ EPBL_currentOffset m2 : 16|12@1+ (0.016997132,-37.55274262) [0|0] "" Vector__XXX
 SG_ EPBL_driverLockedOut m2 : 15|1@1+ (1,0) [0|0] "" Vector__XXX
 SG_ EPBL_dynamicManagerReady m2 : 14|1@1+ (1,0) [0|0] "" Vector__XXX
 SG_ EPBL_emergencyOperationMode m2 : 12|2@1+ (1,0) [0|0] "" Vector__XXX
 SG_ EPBL_pid_uI m1 : 12|10@1- (0.2,0) [0|0] "" Vector__XXX
 SG_ EPBL_nvFilt m0 : 11|9@1+ (0.043549408784,0) [0|0] "" Vector__XXX
 SG_ EPBL_12VFilt_SW m0 : 2|9@1+ (0.043549408784,0) [0|0] "" Vector__XXX
 SG_ EPBL_limpToDecelTimer m2 : 2|10@1+ (1,0) [0|0] "" Vector__XXX
 SG_ EPBL_pid_uP m1 : 2|10@1- (0.2,0) [0|0] "" Vector__XXX
 SG_ EPBL_debugOutputIndex M : 0|2@1+ (1,0) [0|0] "" Vector__XXX

BO_ 1929 EPBL_LVPowerState: 4 Vector__XXX
 SG_ EPBL_LVPowerStateChecksum : 24|8@1+ (1,0) [0|0] "" Vector__XXX
 SG_ EPBL_LVPowerStateCounter : 20|4@1+ (1,0) [0|0] "" Vector__XXX
 SG_ EPBL_vehiclePowerStateDBG : 11|2@1+ (1,0) [0|0] "" Vector__XXX
 SG_ EPBL_frontUSBPortPoweredDueToUIRequest : 10|1@1+ (1,0) [0|0] "" Vector__XXX
 SG_ EPBL_usbLVState : 8|2@1+ (1,0) [0|0] "" Vector__XXX
 SG_ EPBL_sccmLVState : 6|2@1+ (1,0) [0|0] "" Vector__XXX
 SG_ EPBL_lumbarLVState : 4|2@1+ (1,0) [0|0] "" Vector__XXX
 SG_ EPBL_cpLVState : 2|2@1+ (1,0) [0|0] "" Vector__XXX
 SG_ EPBL_rcmLVState : 0|2@1+ (1,0) [0|0] "" Vector__XXX

BO_ 1930 HVP_pyroDeviceDbg: 8 Vector__XXX
 SG_ HVP_pyroAoutEr2 m1 : 48|16@1+ (0.001,0) [0|0] "" Vector__XXX
 SG_ HVP_pyroAoutGnd m5 : 48|16@1+ (0.001,0) [0|0] "" Vector__XXX
 SG_ HVP_pyroAoutLeakIgl1 m2 : 48|16@1+ (0.001,0) [0|0] "" Vector__XXX
 SG_ HVP_pyroAoutRref m3 : 48|16@1+ (0.001,0) [0|0] "" Vector__XXX
 SG_ HVP_pyroAoutSquibResIgl1 m4 : 48|16@1+ (0.001,0) [0|0] "" Vector__XXX
 SG_ HVP_pyroAoutVst2 m0 : 48|16@1+ (0.001,0) [0|0] "" Vector__XXX
 SG_ HVP_pyroAoutEr1 m1 : 32|16@1+ (0.001,0) [0|0] "" Vector__XXX
 SG_ HVP_pyroAoutHighsideSwitchIgh1 m5 : 32|16@1+ (0.001,0) [0|0] "" Vector__XXX
 SG_ HVP_pyroAoutLeakIgh1 m2 : 32|16@1+ (0.001,0) [0|0] "" Vector__XXX
 SG_ HVP_pyroAoutLowsideSwitchIgl1 m6 : 32|16@1+ (0.001,0) [0|0] "" Vector__XXX
 SG_ HVP_pyroAoutRm m3 : 32|16@1+ (0.001,0) [0|0] "" Vector__XXX
 SG_ HVP_pyroAoutSquibResIgh1 m4 : 32|16@1+ (0.001,0) [0|0] "" Vector__XXX
 SG_ HVP_pyroAoutVst1 m0 : 32|16@1+ (0.001,0) [0|0] "" Vector__XXX
 SG_ HVP_pyroAoutMultiplexer M : 16|3@1+ (1,0) [0|0] "" Vector__XXX
 SG_ HVP_pyroFiringHandle : 10|4@1+ (1,0) [0|0] "" Vector__XXX
 SG_ HVP_pyroSquibFired : 9|1@1+ (1,0) [0|0] "" Vector__XXX
 SG_ HVP_pyroTestPyroLeakFailed : 8|1@1+ (1,0) [0|0] "" Vector__XXX
 SG_ HVP_pyroTestLowSideSwitchFailed : 7|1@1+ (1,0) [0|0] "" Vector__XXX
 SG_ HVP_pyroTestHighSideSwitchFailed : 6|1@1+ (1,0) [0|0] "" Vector__XXX
 SG_ HVP_pyroTestVstFailed : 5|1@1+ (1,0) [0|0] "" Vector__XXX
 SG_ HVP_pyroTestErFailed : 4|1@1+ (1,0) [0|0] "" Vector__XXX
 SG_ HVP_pyroTestSquibResFailed : 3|1@1+ (1,0) [0|0] "" Vector__XXX
 SG_ HVP_pyroTestRefCurrentFailed : 2|1@1+ (1,0) [0|0] "" Vector__XXX
 SG_ HVP_pyroStatus : 0|2@1+ (1,0) [0|0] "" Vector__XXX

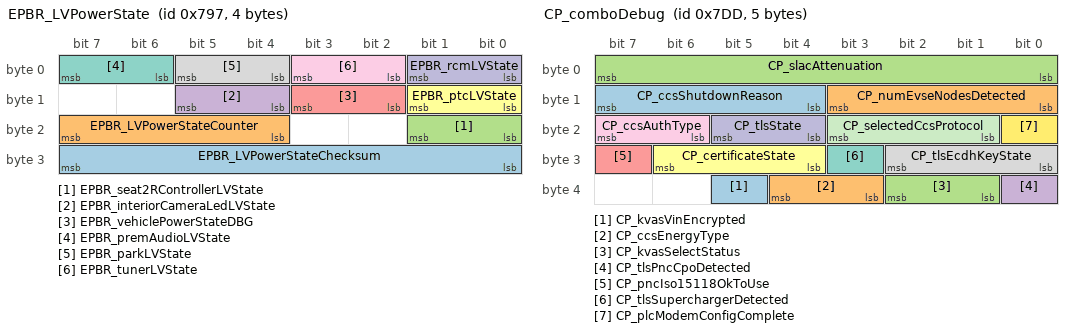
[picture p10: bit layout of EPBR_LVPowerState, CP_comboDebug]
BO_ 1943 EPBR_LVPowerState: 4 Vector__XXX
 SG_ EPBR_LVPowerStateChecksum : 24|8@1+ (1,0) [0|0] "" Vector__XXX
 SG_ EPBR_LVPowerStateCounter : 20|4@1+ (1,0) [0|0] "" Vector__XXX
 SG_ EPBR_seat2RControllerLVState : 16|2@1+ (1,0) [0|0] "" Vector__XXX
 SG_ EPBR_interiorCameraLedLVState : 12|2@1+ (1,0) [0|0] "" Vector__XXX
 SG_ EPBR_vehiclePowerStateDBG : 10|2@1+ (1,0) [0|0] "" Vector__XXX
 SG_ EPBR_ptcLVState : 8|2@1+ (1,0) [0|0] "" Vector__XXX
 SG_ EPBR_premAudioLVState : 6|2@1+ (1,0) [0|0] "" Vector__XXX
 SG_ EPBR_parkLVState : 4|2@1+ (1,0) [0|0] "" Vector__XXX
 SG_ EPBR_tunerLVState : 2|2@1+ (1,0) [0|0] "" Vector__XXX
 SG_ EPBR_rcmLVState : 0|2@1+ (1,0) [0|0] "" Vector__XXX

BO_ 1944 EPBL_remoteADC: 8 Vector__XXX
 SG_ EPBL_remoteADCChecksum : 56|8@1+ (1,0) [0|0] "" Vector__XXX
 SG_ EPBL_remoteADCCounter : 52|4@1+ (1,0) [0|0] "" Vector__XXX
 SG_ EPBL_2ndRowLeftCushionTemp m3 : 34|10@1+ (0.0009775171065493646,0) [0|0] "" Vector__XXX
 SG_ EPBL_chargePortMonitor m4 : 34|10@1+ (0.017595307917888565,0) [0|0] "" Vector__XXX
 SG_ EPBL_liftGateStrutOpenMonitor m1 : 34|10@1+ (0.017595307917888565,0) [0|0] "" Vector__XXX
 SG_ EPBL_seatFrontTiltUpMonitor m0 : 34|10@1+ (0.017595307917888565,0) [0|0] "" Vector__XXX
 SG_ EPBL_steeringColumnUpMonitor m2 : 34|10@1+ (0.017595307917888565,0) [0|0] "" Vector__XXX
 SG_ EPBL_2ndRowCenterCushionTemp m3 : 24|10@1+ (0.0009775171065493646,0) [0|0] "" Vector__XXX
 SG_ EPBL_accessoryFeedAlwaysOnMonitor m2 : 24|10@1+ (0.017595307917888565,0) [0|0] "" Vector__XXX
 SG_ EPBL_liftGateStrutCloseMonitor m1 : 24|10@1+ (0.017595307917888565,0) [0|0] "" Vector__XXX
 SG_ EPBL_seatFrontLiftUpMonitor m0 : 24|10@1+ (0.017595307917888565,0) [0|0] "" Vector__XXX
 SG_ EPBL_securityControllerMonitor m4 : 24|10@1+ (0.017595307917888565,0) [0|0] "" Vector__XXX
 SG_ EPBL_2ndRowRightCushionTemp m3 : 13|10@1+ (0.0009775171065493646,0) [0|0] "" Vector__XXX
 SG_ EPBL_BLEMonitor m4 : 13|10@1+ (0.017595307917888565,0) [0|0] "" Vector__XXX
 SG_ EPBL_efuseNonContinuousMonitor m1 : 13|10@1+ (0.017595307917888565,0) [0|0] "" Vector__XXX
 SG_ EPBL_mirrorDimMonitor m2 : 13|10@1+ (0.004887585532746823,0) [0|0] "" Vector__XXX
 SG_ EPBL_windowLiftRearDownMonitor m0 : 13|10@1+ (0.017595307917888565,0) [0|0] "" Vector__XXX
 SG_ EPBL_PCBATemp m4 : 3|10@1+ (0.0009775171065493646,0) [0|0] "" Vector__XXX
 SG_ EPBL_efuseContinousMonitor m1 : 3|10@1+ (0.017595307917888565,0) [0|0] "" Vector__XXX
 SG_ EPBL_frontCushionTemp m3 : 3|10@1+ (0.0009775171065493646,0) [0|0] "" Vector__XXX
 SG_ EPBL_seatFrontBackRestUpMonitor m2 : 3|10@1+ (0.017595307917888565,0) [0|0] "" Vector__XXX
 SG_ EPBL_trailerAuxMonitor m6 : 3|10@1+ (0.017595307917888565,0) [0|0] "" Vector__XXX
 SG_ EPBL_windowLiftFrontUpMonitor m0 : 3|10@1+ (0.017595307917888565,0) [0|0] "" Vector__XXX
 SG_ EPBL_remoteADCIndex M : 0|3@1+ (1,0) [0|0] "" Vector__XXX

BO_ 1949 V2G_evseLogData: 8 Vector__XXX
 SG_ V2G_chgParamRes_isoState_val m7 : 62|1@1+ (1,0) [0|0] "" Vector__XXX
 SG_ V2G_currDemRes_isoState m11 : 61|3@1+ (1,0) [0|0] "" Vector__XXX
 SG_ V2G_currDemRes_evseMaxPower_val m11 : 60|1@1+ (1,0) [0|0] "" Vector__XXX
 SG_ V2G_chgParamRes_isoState m7 : 59|3@1+ (1,0) [0|0] "" Vector__XXX
 SG_ V2G_chgParamRes_evseMaxPower_val m7 : 58|1@1+ (1,0) [0|0] "" Vector__XXX
 SG_ V2G_currDemRes_evseMaxPowerLim m11 : 52|8@1+ (5.9766,0) [0|0] "" Vector__XXX
 SG_ V2G_currDemRes_evseMaxVLim_val m11 : 51|1@1+ (1,0) [0|0] "" Vector__XXX
 SG_ V2G_chgParamRes_evseMaxPowerLim m7 : 50|8@1+ (5.9766,0) [0|0] "" Vector__XXX
 SG_ V2G_currDemRes_evseMaxVLim m11 : 43|8@1+ (4.688,0) [0|0] "" Vector__XXX
 SG_ V2G_chgParamRes_evseMinVLim m7 : 42|8@1+ (4.688,0) [0|0] "" Vector__XXX
 SG_ V2G_currDemRes_evseMaxILim_val m11 : 42|1@1+ (1,0) [0|0] "" Vector__XXX
 SG_ V2G_prechargeRes_isoState_val m9 : 35|1@1+ (1,0) [0|0] "" Vector__XXX
 SG_ V2G_chgParamRes_evseMinILim m7 : 34|8@1+ (7.032,0) [0|0] "" Vector__XXX
 SG_ V2G_currDemRes_evseMaxILim m11 : 34|8@1+ (7.032,0) [0|0] "" Vector__XXX
 SG_ V2G_prechargeRes_isoState m9 : 32|3@1+ (1,0) [0|0] "" Vector__XXX
 SG_ V2G_chgParamRes_evseMaxVLim m7 : 26|8@1+ (4.688,0) [0|0] "" Vector__XXX
 SG_ V2G_chargingStatusRes_rcd m12 : 24|1@1+ (1,0) [0|0] "" Vector__XXX
 SG_ V2G_currDemRes_outputI m11 : 24|10@1+ (1.7578125,0) [0|0] "" Vector__XXX
 SG_ V2G_cableCheckRes_isoState_val m8 : 23|1@1+ (1,0) [0|0] "" Vector__XXX
 SG_ V2G_chargingStatusRes_maxI_val m12 : 23|1@1+ (1,0) [0|0] "" Vector__XXX
 SG_ V2G_pwrDelEndRes_isoState_val m13 : 23|1@1+ (1,0) [0|0] "" Vector__XXX
 SG_ V2G_pwrDelStartRes_isoState_val m10 : 23|1@1+ (1,0) [0|0] "" Vector__XXX
 SG_ V2G_cableCheckRes_isoState m8 : 20|3@1+ (1,0) [0|0] "" Vector__XXX
 SG_ V2G_prechargeRes_outputV m9 : 20|10@1+ (1.171875,0) [0|0] "" Vector__XXX
 SG_ V2G_pwrDelEndRes_isoState m13 : 20|3@1+ (1,0) [0|0] "" Vector__XXX
 SG_ V2G_pwrDelStartRes_isoState m10 : 20|3@1+ (1,0) [0|0] "" Vector__XXX
 SG_ V2G_chgParamRes_evseMaxILim m7 : 18|8@1+ (7.032,0) [0|0] "" Vector__XXX
 SG_ V2G_cableCheckRes_evseStatus m8 : 16|4@1+ (1,0) [0|0] "" Vector__XXX
 SG_ V2G_chargingStatusRes_maxI m12 : 16|7@1+ (1,0) [0|0] "" Vector__XXX
 SG_ V2G_powerDelEndRes_evseStatus m13 : 16|4@1+ (1,0) [0|0] "" Vector__XXX
 SG_ V2G_powerDelStartRes_evseStatus m10 : 16|4@1+ (1,0) [0|0] "" Vector__XXX
 SG_ V2G_prechargeRes_evseStatus m9 : 16|4@1+ (1,0) [0|0] "" Vector__XXX
 SG_ V2G_serviceDiscRes_dcExtended m2 : 16|1@1+ (1,0) [0|0] "" Vector__XXX
 SG_ V2G_serviceDiscRes_evChgAvail m2 : 15|1@1+ (1,0) [0|0] "" Vector__XXX
 SG_ V2G_chgParamRes_evseStatus m7 : 14|4@1+ (1,0) [0|0] "" Vector__XXX
 SG_ V2G_currDemRes_outputV m11 : 14|10@1+ (1.171875,0) [0|0] "" Vector__XXX
 SG_ V2G_serviceDiscRes_pncAvail m2 : 14|1@1+ (1,0) [0|0] "" Vector__XXX
 SG_ V2G_cableCheckRes_finished m8 : 13|1@1+ (1,0) [0|0] "" Vector__XXX
 SG_ V2G_chgParamRes_finished m7 : 13|1@1+ (1,0) [0|0] "" Vector__XXX
 SG_ V2G_contractAuthRes_finished m6 : 13|1@1+ (1,0) [0|0] "" Vector__XXX
 SG_ V2G_serviceDiscRes_extPayAvail m2 : 13|1@1+ (1,0) [0|0] "" Vector__XXX
 SG_ V2G_currDemRes_evseStatus m11 : 10|4@1+ (1,0) [0|0] "" Vector__XXX
 SG_ V2G_cableCheckRes_respCode m8 : 8|5@1+ (1,0) [0|0] "" Vector__XXX
 SG_ V2G_chargingStatusRes_respCode m12 : 8|5@1+ (1,0) [0|0] "" Vector__XXX
 SG_ V2G_chgParamRes_respCode m7 : 8|5@1+ (1,0) [0|0] "" Vector__XXX
 SG_ V2G_contractAuthRes_respCode m6 : 8|5@1+ (1,0) [0|0] "" Vector__XXX
 SG_ V2G_paymentDetailsRes_respCode m5 : 8|5@1+ (1,0) [0|0] "" Vector__XXX
 SG_ V2G_powerDelEndRes_respCode m13 : 8|5@1+ (1,0) [0|0] "" Vector__XXX
 SG_ V2G_powerDelStartRes_respCode m10 : 8|5@1+ (1,0) [0|0] "" Vector__XXX
 SG_ V2G_prechargeRes_respCode m9 : 8|5@1+ (1,0) [0|0] "" Vector__XXX
 SG_ V2G_serviceDetailRes_respCode m3 : 8|5@1+ (1,0) [0|0] "" Vector__XXX
 SG_ V2G_serviceDiscoveryRes_respCode m2 : 8|5@1+ (1,0) [0|0] "" Vector__XXX
 SG_ V2G_servicePaymntSelRes_respCode m4 : 8|5@1+ (1,0) [0|0] "" Vector__XXX
 SG_ V2G_sessionSetupRes_respCode m1 : 8|5@1+ (1,0) [0|0] "" Vector__XXX
 SG_ V2G_sessionStopRes_respCode m14 : 8|5@1+ (1,0) [0|0] "" Vector__XXX
 SG_ V2G_suppAppProtocolRes_schemaId m0 : 8|8@1+ (1,0) [0|0] "" Vector__XXX
 SG_ V2G_currDemRes_isoState_val m13 : 5|1@1+ (1,0) [0|0] "" Vector__XXX
 SG_ V2G_currDemRes_respCode m11 : 5|5@1+ (1,0) [0|0] "" Vector__XXX
 SG_ V2G_suppAppProtocolRes_respCode m0 : 5|2@1+ (1,0) [0|0] "" Vector__XXX
 SG_ V2G_evseLogDataSelect M : 0|5@1+ (1,0) [0|0] "" Vector__XXX

BO_ 1960 EPBR_debugOutput: 8 Vector__XXX
 SG_ EPBR_uiNotAvailable m0 : 62|1@1+ (1,0) [0|0] "" Vector__XXX
 SG_ EPBR_driverIsLeavingDisabled m0 : 61|1@1+ (1,0) [0|0] "" Vector__XXX
 SG_ EPBR_slopeParkable m0 : 60|1@1+ (1,0) [0|0] "" Vector__XXX
 SG_ EPBR_epbOpenUnableToPark m0 : 59|1@1+ (1,0) [0|0] "" Vector__XXX
 SG_ EPBR_brakePressHeld m0 : 58|1@1+ (1,0) [0|0] "" Vector__XXX
 SG_ EPBR_esmCaliperRequest m0 : 55|3@1+ (1,0) [0|0] "" Vector__XXX
 SG_ EPBR_12VFilt m1 : 52|9@1+ (0.043549408784,0) [0|0] "" Vector__XXX
 SG_ EPBR_lockoutUnlockCount m0 : 49|6@1+ (1,0) [0|0] "" Vector__XXX
 SG_ EPBR_brakeDiscWipeAccumul m2 : 48|8@1+ (1,0) [0|0] "" Vector__XXX
 SG_ EPBR_lockoutCommandHVC m2 : 43|1@1+ (1,0) [0|0] "" Vector__XXX
 SG_ EPBR_lockoutOutputHVC m2 : 42|1@1+ (1,0) [0|0] "" Vector__XXX
 SG_ EPBR_lockoutCmdContactor m2 : 41|1@1+ (1,0) [0|0] "" Vector__XXX
 SG_ EPBR_lockoutOutContactor m2 : 40|1@1+ (1,0) [0|0] "" Vector__XXX
 SG_ EPBR_pid_error m1 : 40|12@1+ (0.016997132,-37.55274262) [0|0] "" Vector__XXX
 SG_ EPBR_currentVariance m0 : 35|14@1- (0.0007629394535064697,0) [0|0] "" Vector__XXX
 SG_ EPBR_atEndStop m0 : 34|1@1+ (1,0) [0|0] "" Vector__XXX
 SG_ EPBR_oocViolation m0 : 33|1@1+ (1,0) [0|0] "" Vector__XXX
 SG_ EPBR_nFault m0 : 32|1@1+ (1,0) [0|0] "" Vector__XXX
 SG_ EPBR_ramp m1 : 32|8@1+ (0.392157,0) [0|0] "" Vector__XXX
 SG_ EPBR_caliperState m0 : 29|3@1+ (1,0) [0|0] "" Vector__XXX
 SG_ EPBR_filteredCurrentPeak m2 : 28|12@1+ (0.01,0) [0|0] "" Vector__XXX
 SG_ EPBR_pid_duty m1 : 22|10@1- (0.2,0) [0|0] "" Vector__XXX
 SG_ EPBR_pvFilt m0 : 20|9@1+ (0.043549408784,0) [0|0] "" Vector__XXX
 SG_ EPBR_currentOffset m2 : 16|12@1+ (0.016997132,-37.55274262) [0|0] "" Vector__XXX
 SG_ EPBR_driverLockedOut m2 : 15|1@1+ (1,0) [0|0] "" Vector__XXX
 SG_ EPBR_dynamicManagerReady m2 : 14|1@1+ (1,0) [0|0] "" Vector__XXX
 SG_ EPBR_emergencyOperationMode m2 : 12|2@1+ (1,0) [0|0] "" Vector__XXX
 SG_ EPBR_pid_uI m1 : 12|10@1- (0.2,0) [0|0] "" Vector__XXX
 SG_ EPBR_nvFilt m0 : 11|9@1+ (0.043549408784,0) [0|0] "" Vector__XXX
 SG_ EPBR_12VFilt_SW m0 : 2|9@1+ (0.043549408784,0) [0|0] "" Vector__XXX
 SG_ EPBR_limpToDecelTimer m2 : 2|10@1+ (1,0) [0|0] "" Vector__XXX
 SG_ EPBR_pid_uP m1 : 2|10@1- (0.2,0) [0|0] "" Vector__XXX
 SG_ EPBR_debugOutputIndex M : 0|2@1+ (1,0) [0|0] "" Vector__XXX

BO_ 1973 PM_itpmsDisplay: 3 Vector__XXX
 SG_ PM_indirectTPMSDisplayWarningIndicatorRR m0 : 20|2@1+ (1,0) [0|0] "" Vector__XXX
 SG_ PM_indirectTPMSDisplayWarningIndicatorRL m0 : 18|2@1+ (1,0) [0|0] "" Vector__XXX
 SG_ PM_indirectTPMSDisplayWarningIndicatorFR m0 : 16|2@1+ (1,0) [0|0] "" Vector__XXX
 SG_ PM_indirectTPMSRecommendedColdPressureRear m1 : 16|8@1+ (0.025,0) [0|0] "" Vector__XXX
 SG_ PM_indirectTPMSDisplayWarningIndicatorFL m0 : 13|2@1+ (1,0) [0|0] "" Vector__XXX
 SG_ PM_fusedPressureEstimateFrR m2 : 11|9@1+ (0.008,0) [0|0] "" Vector__XXX
 SG_ PM_fusedPressureEstimateReR m3 : 11|9@1+ (0.008,0) [0|0] "" Vector__XXX
 SG_ PM_indirectTPMSDisplayProgress m0 : 8|5@1+ (0.05,0) [0|0] "" Vector__XXX
 SG_ PM_indirectTPMSRecommendedColdPressureFront m1 : 8|8@1+ (0.025,0) [0|0] "" Vector__XXX
 SG_ PM_indirectTPMSDisplayState m0 : 4|2@1+ (1,0) [0|0] "" Vector__XXX
 SG_ PM_fusedPressureEstimateFrL m2 : 2|9@1+ (0.008,0) [0|0] "" Vector__XXX
 SG_ PM_fusedPressureEstimateReL m3 : 2|9@1+ (0.008,0) [0|0] "" Vector__XXX
 SG_ PM_indirectTPMSTellTale m0 : 2|2@1+ (1,0) [0|0] "" Vector__XXX
 SG_ PM_itpmsDisplaySelector M : 0|2@1+ (1,0) [0|0] "" Vector__XXX

BO_ 1976 EPBR_remoteADC: 8 Vector__XXX
 SG_ EPBR_remoteADCChecksum : 56|8@1+ (1,0) [0|0] "" Vector__XXX
 SG_ EPBR_remoteADCCounter : 52|4@1+ (1,0) [0|0] "" Vector__XXX
 SG_ EPBR_2rSeatInboardFloorSensor m5 : 34|10@1+ (0.004887585532746823,0) [0|0] "" Vector__XXX
 SG_ EPBR_PCBATemp m2 : 34|10@1+ (0.0009775171065493646,0) [0|0] "" Vector__XXX
 SG_ EPBR_gloveBoxReleaseMonitor m1 : 34|10@1+ (0.017595307917888565,0) [0|0] "" Vector__XXX
 SG_ EPBR_hvacLeftLowerVentDuctTemp m3 : 34|10@1+ (0.0009775171065493646,0) [0|0] "" Vector__XXX
 SG_ EPBR_premiumAmpCurrent m4 : 34|10@1+ (0.029296875,0) [0|0] "" Vector__XXX
 SG_ EPBR_seatFrontTiltUpMonitor m0 : 34|10@1+ (0.017595307917888565,0) [0|0] "" Vector__XXX
 SG_ EPBR_2rSeatOutboardFloorSensor m5 : 24|10@1+ (0.004887585532746823,0) [0|0] "" Vector__XXX
 SG_ EPBR_ecallStandbyPowerMonitor m2 : 24|10@1+ (0.02932551319648094,0) [0|0] "" Vector__XXX
 SG_ EPBR_gloveBoxLatchUpstreamI m4 : 24|10@1+ (0.019550342130987292,0) [0|0] "" Vector__XXX
 SG_ EPBR_hvacRightLowerVentDuctTemp m3 : 24|10@1+ (0.0009775171065493646,0) [0|0] "" Vector__XXX
 SG_ EPBR_seatFrontLiftUpMonitor m0 : 24|10@1+ (0.017595307917888565,0) [0|0] "" Vector__XXX
 SG_ EPBR_seatFrontTrackForwardMonitor m1 : 24|10@1+ (0.017595307917888565,0) [0|0] "" Vector__XXX
 SG_ EPBR_efuseNonContinuousMonitor m1 : 13|10@1+ (0.017595307917888565,0) [0|0] "" Vector__XXX
 SG_ EPBR_frontCushionTemp m5 : 13|10@1+ (0.0009775171065493646,0) [0|0] "" Vector__XXX
 SG_ EPBR_hvContactorsMonitor m4 : 13|10@1+ (0.017595307917888565,0) [0|0] "" Vector__XXX
 SG_ EPBR_hvacLeftVentDuctTemp m3 : 13|10@1+ (0.0009775171065493646,0) [0|0] "" Vector__XXX
 SG_ EPBR_seatFrontBackRestUpMonitor m2 : 13|10@1+ (0.017595307917888565,0) [0|0] "" Vector__XXX
 SG_ EPBR_windowLiftRearUpMonitor m0 : 13|10@1+ (0.017595307917888565,0) [0|0] "" Vector__XXX
 SG_ EPBR_BLEBPillarMonitor m4 : 3|10@1+ (0.017595307917888565,0) [0|0] "" Vector__XXX
 SG_ EPBR_efuseContinousMonitor m1 : 3|10@1+ (0.017595307917888565,0) [0|0] "" Vector__XXX
 SG_ EPBR_hvacRightVentDuctTemp m3 : 3|10@1+ (0.0009775171065493646,0) [0|0] "" Vector__XXX
 SG_ EPBR_mirrorDimMonitor m2 : 3|10@1+ (0.004887585532746823,0) [0|0] "" Vector__XXX
 SG_ EPBR_rearGlassHeaterCurrent m5 : 3|10@1+ (0.068359375,0) [0|0] "" Vector__XXX
 SG_ EPBR_windowLiftFrontDownMonitor m0 : 3|10@1+ (0.017595307917888565,0) [0|0] "" Vector__XXX
 SG_ EPBR_remoteADCIndex M : 0|3@1+ (1,0) [0|0] "" Vector__XXX

BO_ 1981 V2G_vehLogData: 8 Vector__XXX
 SG_ V2G_chgParamReq_evReady m7 : 60|1@1+ (1,0) [0|0] "" Vector__XXX
 SG_ V2G_chgParamReq_evStatusCode m7 : 56|4@1+ (1,0) [0|0] "" Vector__XXX
 SG_ V2G_currentDemReq_maxPowerLim m11 : 50|10@1+ (1.494138,0) [0|0] "" Vector__XXX
 SG_ V2G_chgParamReq_maxPowerLim m7 : 40|13@1+ (0.1867675781,0) [0|0] "" Vector__XXX
 SG_ V2G_currentDemReq_maxVoltageLim m11 : 40|10@1+ (1.171875,0) [0|0] "" Vector__XXX
 SG_ V2G_currentDemReq_maxCurrentLim m11 : 29|10@1+ (1.7578125,0) [0|0] "" Vector__XXX
 SG_ V2G_chgParamReq_maxVoltageLim m7 : 24|13@1+ (0.146484375,0) [0|0] "" Vector__XXX
 SG_ V2G_currentDemReq_targetV m11 : 16|13@1+ (0.146484375,0) [0|0] "" Vector__XXX
 SG_ V2G_chgParamReq_maxCurrentLim m7 : 8|13@1+ (0.2197265625,0) [0|0] "" Vector__XXX
 SG_ V2G_prechargeReq_targetV m9 : 8|13@1+ (0.146484375,0) [0|0] "" Vector__XXX
 SG_ V2G_powerDelEndReq_evStatusCode m13 : 6|1@1+ (1,0) [0|0] "" Vector__XXX
 SG_ V2G_cableCheckReq_sent m8 : 5|1@1+ (1,0) [0|0] "" Vector__XXX
 SG_ V2G_chargingStatusReq_sent m12 : 5|1@1+ (1,0) [0|0] "" Vector__XXX
 SG_ V2G_contractAuthReq_sent m6 : 5|1@1+ (1,0) [0|0] "" Vector__XXX
 SG_ V2G_currentDemReq_targetI m11 : 5|10@1+ (1.7578125,0) [0|0] "" Vector__XXX
 SG_ V2G_paymentDetailsReq_sent m5 : 5|1@1+ (1,0) [0|0] "" Vector__XXX
 SG_ V2G_powerDeliveryEndReq_sent m13 : 5|1@1+ (1,0) [0|0] "" Vector__XXX
 SG_ V2G_powerDeliveryStartReq_sent m10 : 5|1@1+ (1,0) [0|0] "" Vector__XXX
 SG_ V2G_serviceDetailReq_sent m3 : 5|1@1+ (1,0) [0|0] "" Vector__XXX
 SG_ V2G_serviceDiscoveryReq_sent m2 : 5|1@1+ (1,0) [0|0] "" Vector__XXX
 SG_ V2G_servicePaymentSelReq_sent m4 : 5|1@1+ (1,0) [0|0] "" Vector__XXX
 SG_ V2G_sessionSetupReq_sent m1 : 5|1@1+ (1,0) [0|0] "" Vector__XXX
 SG_ V2G_sessionStopReq_sent m14 : 5|1@1+ (1,0) [0|0] "" Vector__XXX
 SG_ V2G_suppAppProtocolReq_sent m0 : 5|1@1+ (1,0) [0|0] "" Vector__XXX
 SG_ V2G_vehLogDataSelect M : 0|5@1+ (1,0) [0|0] "" Vector__XXX

BO_ 1983 PLC_teslaV2gLog: 1 Vector__XXX
 SG_ TeslaV2G_protoMsgReceived : 4|1@1+ (1,0) [0|0] "" Vector__XXX
 SG_ TeslaV2G_evseChargeStatus : 1|3@1+ (1,0) [0|0] "" Vector__XXX
 SG_ TeslaV2G_cableButtonPressed : 0|1@1+ (1,0) [0|0] "" Vector__XXX

BO_ 2004 PMR_debug: 8 Vector__XXX
 SG_ PMR_resolverDiMIA m17 : 57|1@1+ (1,0) [0|0] "" Vector__XXX
 SG_ PMR_cpu100HzMin m64 : 56|8@1+ (0.4,0) [0|0] "" Vector__XXX
 SG_ PMR_cpu10kHzMax m65 : 56|8@1+ (0.4,0) [0|0] "" Vector__XXX
 SG_ PMR_lmSatCoeff m3 : 56|8@1+ (0.00391,0) [0|0] "" Vector__XXX
 SG_ PMR_resolverClaMIA m17 : 56|1@1+ (1,0) [0|0] "" Vector__XXX
 SG_ PMR_statorT m4 : 56|8@1+ (1,-40) [0|0] "" Vector__XXX
 SG_ PMR_resolverPhaseOutOfSpec m17 : 55|1@1+ (1,0) [0|0] "" Vector__XXX
 SG_ PMR_resolverNoCarrier m17 : 54|1@1+ (1,0) [0|0] "" Vector__XXX
 SG_ PMR_cpu1kHzAvg m64 : 48|8@1+ (0.4,0) [0|0] "" Vector__XXX
 SG_ PMR_cpu20kHzMin m65 : 48|8@1+ (0.4,0) [0|0] "" Vector__XXX
 SG_ PMR_resolverOffsetExt m17 : 48|6@1+ (0.053,0) [0|0] "" Vector__XXX
 SG_ PMR_torqueOutOfMap m5 : 47|1@1+ (1,0) [0|0] "" Vector__XXX
 SG_ PMR_switchingActive m5 : 46|1@1+ (1,0) [0|0] "" Vector__XXX
 SG_ PMR_cpu100HzMax m64 : 40|8@1+ (0.4,0) [0|0] "" Vector__XXX
 SG_ PMR_cpu20kHzMax m65 : 40|8@1+ (0.4,0) [0|0] "" Vector__XXX
 SG_ PMR_iDQmagnitude m3 : 40|16@1- (0.0939,0) [0|0] "" Vector__XXX
 SG_ PMR_motorRPM m4 : 40|16@1- (1,0) [0|0] "" Vector__XXX
 SG_ PMR_resolverOffsetSin m17 : 40|6@1+ (0.053,0) [0|0] "" Vector__XXX
 SG_ PMR_torqueAccelAvg m1 : 40|13@1- (2,0) [0|0] "" Vector__XXX
 SG_ PMR_torqueReversalWindow m2 : 40|13@1- (2,0) [0|0] "" Vector__XXX
 SG_ PMR_cpu10HzMin m65 : 32|8@1+ (0.4,0) [0|0] "" Vector__XXX
 SG_ PMR_cpu10kHzAvg m64 : 32|8@1+ (0.4,0) [0|0] "" Vector__XXX
 SG_ PMR_resolverOffsetCos m17 : 32|6@1+ (0.053,0) [0|0] "" Vector__XXX
 SG_ PMR_Ib m3 : 24|16@1- (0.0939,0) [0|0] "" Vector__XXX
 SG_ PMR_cpu10HzAvg m65 : 24|8@1+ (0.4,0) [0|0] "" Vector__XXX
 SG_ PMR_cpu1kHzMin m64 : 24|8@1+ (0.4,0) [0|0] "" Vector__XXX
 SG_ PMR_idleStackMax m67 : 24|16@1+ (1,0) [0|0] "" Vector__XXX
 SG_ PMR_resolverExcitationGain m17 : 24|7@1+ (0.063,0) [0|0] "" Vector__XXX
 SG_ PMR_sysStackMax m70 : 24|16@1+ (1,0) [0|0] "" Vector__XXX
 SG_ PMR_torqueAccelWindow m1 : 24|13@1- (2,0) [0|0] "" Vector__XXX
 SG_ PMR_torqueDecelAvg m2 : 24|13@1- (2,0) [0|0] "" Vector__XXX
 SG_ PMR_udsStackMax m68 : 24|16@1+ (1,0) [0|0] "" Vector__XXX
 SG_ PMR_xcpStackMax m69 : 24|16@1+ (1,0) [0|0] "" Vector__XXX
 SG_ PMR_offsetIb m5 : 20|12@1- (0.1,0) [0|0] "" Vector__XXX
 SG_ PMR_resolverCommonGain m17 : 17|7@1+ (0.063,0) [0|0] "" Vector__XXX
 SG_ PMR_cpu10HzMax m65 : 16|8@1+ (0.4,0) [0|0] "" Vector__XXX
 SG_ PMR_cpu20kHzAvg m64 : 16|8@1+ (0.4,0) [0|0] "" Vector__XXX
 SG_ PMR_Ia m3 : 8|16@1- (0.0939,0) [0|0] "" Vector__XXX
 SG_ PMR_cpu100HzAvg m65 : 8|8@1+ (0.4,0) [0|0] "" Vector__XXX
 SG_ PMR_cpu10kHzMin m66 : 8|8@1+ (0.4,0) [0|0] "" Vector__XXX
 SG_ PMR_cpu1kHzMax m64 : 8|8@1+ (0.4,0) [0|0] "" Vector__XXX
 SG_ PMR_idleStackSize m67 : 8|16@1+ (1,0) [0|0] "" Vector__XXX
 SG_ PMR_offsetIa m5 : 8|12@1- (0.1,0) [0|0] "" Vector__XXX
 SG_ PMR_resolverPhaseAngle m17 : 8|9@1+ (0.001537,0) [0|0] "" Vector__XXX
 SG_ PMR_resolverSpeedError m16 : 8|16@1- (0.75,0) [0|0] "" Vector__XXX
 SG_ PMR_slipFrequency m4 : 8|16@1- (0.005,0) [0|0] "" Vector__XXX
 SG_ PMR_sysStackSize m70 : 8|16@1+ (1,0) [0|0] "" Vector__XXX
 SG_ PMR_torqueDecelWindow m2 : 8|13@1- (2,0) [0|0] "" Vector__XXX
 SG_ PMR_torqueSignError m1 : 8|13@1- (2,0) [0|0] "" Vector__XXX
 SG_ PMR_udsStackSize m68 : 8|16@1+ (1,0) [0|0] "" Vector__XXX
 SG_ PMR_xcpStackSize m69 : 8|16@1+ (1,0) [0|0] "" Vector__XXX
 SG_ PMR_debugSelector M : 0|8@1+ (1,0) [0|0] "" Vector__XXX

BO_ 2013 CP_comboDebug: 5 Vector__XXX
 SG_ CP_kvasVinEncrypted : 37|1@1+ (1,0) [0|0] "" Vector__XXX
 SG_ CP_ccsEnergyType : 35|2@1+ (1,0) [0|0] "" Vector__XXX
 SG_ CP_kvasSelectStatus : 33|2@1+ (1,0) [0|0] "" Vector__XXX
 SG_ CP_tlsPncCpoDetected : 32|1@1+ (1,0) [0|0] "" Vector__XXX
 SG_ CP_pncIso15118OkToUse : 31|1@1+ (1,0) [0|0] "" Vector__XXX
 SG_ CP_certificateState : 28|3@1+ (1,0) [0|0] "" Vector__XXX
 SG_ CP_tlsSuperchargerDetected : 27|1@1+ (1,0) [0|0] "" Vector__XXX
 SG_ CP_tlsEcdhKeyState : 24|3@1+ (1,0) [0|0] "" Vector__XXX
 SG_ CP_ccsAuthType : 22|2@1+ (1,0) [0|0] "" Vector__XXX
 SG_ CP_tlsState : 20|2@1+ (1,0) [0|0] "" Vector__XXX
 SG_ CP_selectedCcsProtocol : 17|3@1+ (1,0) [0|0] "" Vector__XXX
 SG_ CP_plcModemConfigComplete : 16|1@1+ (1,0) [0|0] "" Vector__XXX
 SG_ CP_ccsShutdownReason : 12|4@1+ (1,0) [0|0] "" Vector__XXX
 SG_ CP_numEvseNodesDetected : 8|4@1+ (1,0) [0|0] "" Vector__XXX
 SG_ CP_slacAttenuation : 0|8@1+ (1,0) [0|0] "" Vector__XXX

BO_ 2036 GTW_canLogAvailability: 1 Vector__XXX
 SG_ GTW_canLogServiceAvailability : 0|2@1+ (1,0) [0|0] "" Vector__XXX

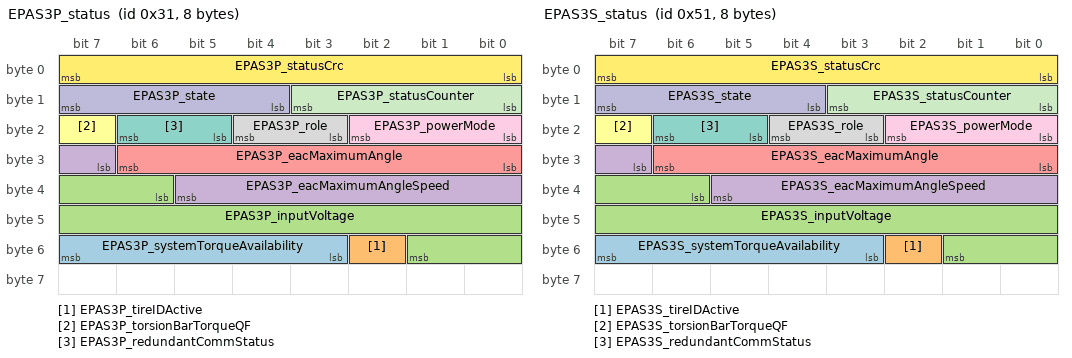
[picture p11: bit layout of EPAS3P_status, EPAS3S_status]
BO_ 49 EPAS3P_status: 8 Vector__XXX
 SG_ EPAS3P_systemTorqueAvailability : 51|5@1+ (5,0) [0|0] "" Vector__XXX
 SG_ EPAS3P_tireIDActive : 50|1@1+ (1,0) [0|0] "" Vector__XXX
 SG_ EPAS3P_inputVoltage : 38|12@1+ (0.0073,0) [0|0] "" Vector__XXX
 SG_ EPAS3P_eacMaximumAngleSpeed : 31|7@1+ (10,0) [0|0] "" Vector__XXX
 SG_ EPAS3P_eacMaximumAngle : 24|7@1+ (10,0) [0|0] "" Vector__XXX
 SG_ EPAS3P_torsionBarTorqueQF : 23|1@1+ (1,0) [0|0] "" Vector__XXX
 SG_ EPAS3P_redundantCommStatus : 21|2@1+ (1,0) [0|0] "" Vector__XXX
 SG_ EPAS3P_role : 19|2@1+ (1,0) [0|0] "" Vector__XXX
 SG_ EPAS3P_powerMode : 16|3@1+ (1,0) [0|0] "" Vector__XXX
 SG_ EPAS3P_state : 12|4@1+ (1,0) [0|0] "" Vector__XXX
 SG_ EPAS3P_statusCounter : 8|4@1+ (1,0) [0|0] "" Vector__XXX
 SG_ EPAS3P_statusCrc : 0|8@1+ (1,0) [0|0] "" Vector__XXX

BO_ 81 EPAS3S_status: 8 Vector__XXX
 SG_ EPAS3S_systemTorqueAvailability : 51|5@1+ (5,0) [0|0] "" Vector__XXX
 SG_ EPAS3S_tireIDActive : 50|1@1+ (1,0) [0|0] "" Vector__XXX
 SG_ EPAS3S_inputVoltage : 38|12@1+ (0.0073,0) [0|0] "" Vector__XXX
 SG_ EPAS3S_eacMaximumAngleSpeed : 31|7@1+ (10,0) [0|0] "" Vector__XXX
 SG_ EPAS3S_eacMaximumAngle : 24|7@1+ (10,0) [0|0] "" Vector__XXX
 SG_ EPAS3S_torsionBarTorqueQF : 23|1@1+ (1,0) [0|0] "" Vector__XXX
 SG_ EPAS3S_redundantCommStatus : 21|2@1+ (1,0) [0|0] "" Vector__XXX
 SG_ EPAS3S_role : 19|2@1+ (1,0) [0|0] "" Vector__XXX
 SG_ EPAS3S_powerMode : 16|3@1+ (1,0) [0|0] "" Vector__XXX
 SG_ EPAS3S_state : 12|4@1+ (1,0) [0|0] "" Vector__XXX
 SG_ EPAS3S_statusCounter : 8|4@1+ (1,0) [0|0] "" Vector__XXX
 SG_ EPAS3S_statusCrc : 0|8@1+ (1,0) [0|0] "" Vector__XXX

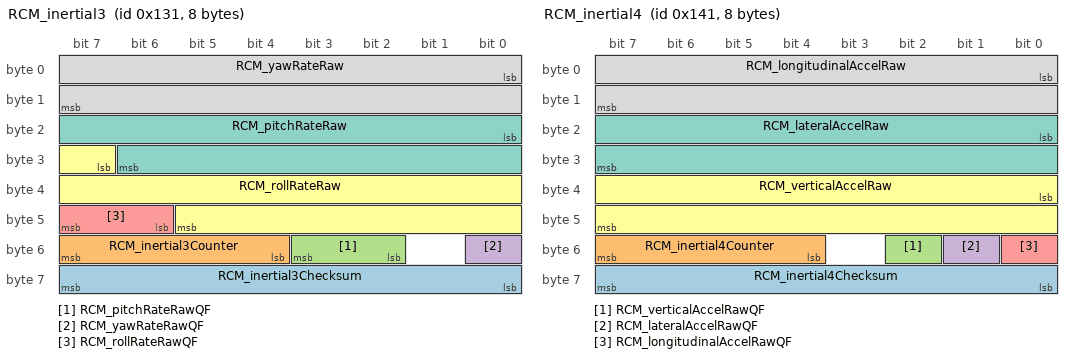
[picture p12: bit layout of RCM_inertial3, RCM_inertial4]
BO_ 305 RCM_inertial3: 8 Vector__XXX
 SG_ RCM_inertial3Checksum : 56|8@1+ (1,0) [0|0] "" Vector__XXX
 SG_ RCM_inertial3Counter : 52|4@1+ (1,0) [0|0] "" Vector__XXX
 SG_ RCM_pitchRateRawQF : 50|2@1+ (1,0) [0|0] "" Vector__XXX
 SG_ RCM_yawRateRawQF : 48|1@1+ (1,0) [0|0] "" Vector__XXX
 SG_ RCM_rollRateRawQF : 46|2@1+ (1,0) [0|0] "" Vector__XXX
 SG_ RCM_rollRateRaw : 31|15@1- (0.00025,0) [0|0] "" Vector__XXX
 SG_ RCM_pitchRateRaw : 16|15@1- (0.00025,0) [0|0] "" Vector__XXX
 SG_ RCM_yawRateRaw : 0|16@1- (0.0001,0) [0|0] "" Vector__XXX

BO_ 321 RCM_inertial4: 8 Vector__XXX
 SG_ RCM_inertial4Checksum : 56|8@1+ (1,0) [0|0] "" Vector__XXX
 SG_ RCM_inertial4Counter : 52|4@1+ (1,0) [0|0] "" Vector__XXX
 SG_ RCM_verticalAccelRawQF : 50|1@1+ (1,0) [0|0] "" Vector__XXX
 SG_ RCM_lateralAccelRawQF : 49|1@1+ (1,0) [0|0] "" Vector__XXX
 SG_ RCM_longitudinalAccelRawQF : 48|1@1+ (1,0) [0|0] "" Vector__XXX
 SG_ RCM_verticalAccelRaw : 32|16@1- (0.00125,0) [0|0] "" Vector__XXX
 SG_ RCM_lateralAccelRaw : 16|16@1- (0.00125,0) [0|0] "" Vector__XXX
 SG_ RCM_longitudinalAccelRaw : 0|16@1- (0.00125,0) [0|0] "" Vector__XXX

BO_ 326 ESP_redundantBrakingStatus: 8 Vector__XXX
 SG_ ESP_longitudinalStabilityControlAvailable : 15|1@1+ (1,0) [0|0] "" Vector__XXX
 SG_ ESP_redundantBrakingSystemStatus : 12|3@1+ (1,0) [0|0] "" Vector__XXX
 SG_ ESP_redundantBrakingStatusCounter : 8|4@1+ (1,0) [0|0] "" Vector__XXX
 SG_ ESP_redundantBrakingStatusChecksum : 0|8@1+ (1,0) [0|0] "" Vector__XXX

BO_ 329 IBST_redundantBrakingStatus: 8 Vector__XXX
 SG_ IBST_brakeTorqueTarget : 15|13@1+ (3,0) [0|0] "" Vector__XXX
 SG_ IBST_redundantBrakingSystemStatus : 12|3@1+ (1,0) [0|0] "" Vector__XXX
 SG_ IBST_redundantBrakingStatusCounter : 8|4@1+ (1,0) [0|0] "" Vector__XXX
 SG_ IBST_redundantBrakingStatusChecksum : 0|8@1+ (1,0) [0|0] "" Vector__XXX

BO_ 454 GTW_canErrorCounters: 6 Vector__XXX
 SG_ GTW_CH_canRxErrCount : 40|8@1+ (1,0) [0|0] "" Vector__XXX
 SG_ GTW_CH_canTxErrCount : 32|8@1+ (1,0) [0|0] "" Vector__XXX
 SG_ GTW_VEH_canRxErrCount : 24|8@1+ (1,0) [0|0] "" Vector__XXX
 SG_ GTW_VEH_canTxErrCount : 16|8@1+ (1,0) [0|0] "" Vector__XXX
 SG_ GTW_PARTY_canRxErrCount : 8|8@1+ (1,0) [0|0] "" Vector__XXX
 SG_ GTW_PARTY_canTxErrCount : 0|8@1+ (1,0) [0|0] "" Vector__XXX

BO_ 521 DAS_longControl: 8 Vector__XXX
 SG_ DAS_longControlStack M : 61|3@1+ (1,0) [0|0] "" Vector__XXX
 SG_ DAS_velocityProfile_calcDelay m3 : 58|3@1+ (0.006666666666666667,0) [0|0] "" Vector__XXX
 SG_ DAS_torqueProfiler_jerkMaxPed m2 : 53|8@1+ (0.059,0) [0|0] "" Vector__XXX
 SG_ DAS_velocityProfile_maxAllowedTargetErrorReg m3 : 52|6@1- (0.1,1.1) [0|0] "" Vector__XXX
 SG_ DAS_pedalControl_speedMax m5 : 51|8@1+ (1,0) [0|0] "" Vector__XXX
 SG_ DAS_pedalControl_noGradeAccelMax m5 : 45|6@1+ (0.25,0) [0|0] "" Vector__XXX
 SG_ DAS_torqueProfiler_jerkMinPed m2 : 44|9@1+ (0.03,-15.232) [0|0] "" Vector__XXX
 SG_ DAS_velocityProfile_jerkFwd_t1t2 m3 : 44|8@1- (0.12,0) [0|0] "" Vector__XXX
 SG_ DAS_pedalControl_brakeTorqueCommand m5 : 32|13@1+ (3.5,0) [0|0] "" Vector__XXX
 SG_ DAS_torqueControl_standstillRequest m6 : 32|1@1+ (1,0) [0|0] "" Vector__XXX
 SG_ DAS_torqueProfiler_targetSpeedPed m2 : 32|12@1+ (0.1,0) [0|0] "" Vector__XXX
 SG_ DAS_velocityProfile_futureTargetSpeedFwd m3 : 32|12@1- (0.08,80.08) [0|0] "" Vector__XXX
 SG_ DAS_velocityProfile_jerkFwd_t0t1 m3 : 24|8@1- (0.12,0) [0|0] "" Vector__XXX
 SG_ DAS_torqueProfiler_accelMaxPed m2 : 23|9@1+ (0.04,-15) [0|0] "" Vector__XXX
 SG_ DAS_aebControl_targetAccelDis m4 : 18|11@1- (0.01,-7.5) [0|0] "" Vector__XXX
 SG_ DAS_aebControl_active m4 : 16|2@1+ (1,0) [0|0] "" Vector__XXX
 SG_ DAS_pedalControl_accelPedalPos m5 : 16|12@1+ (0.025,0) [0|0] "" Vector__XXX
 SG_ DAS_torqueControl_sysTorqueCommandFwd m6 : 16|15@1- (2,0) [0|0] "" Vector__XXX
 SG_ DAS_torqueProfiler_accelMinPed m2 : 14|9@1+ (0.04,-15) [0|0] "" Vector__XXX
 SG_ DAS_velocityProfile_accelFwd_t0 m3 : 13|11@1- (0.012,-0.216) [0|0] "" Vector__XXX
 SG_ DAS_gearRequest : 11|2@1+ (1,0) [0|0] "" Vector__XXX
 SG_ DAS_longControlCounter : 8|3@1+ (1,0) [0|0] "" Vector__XXX
 SG_ DAS_longControlChecksum : 0|8@1+ (1,0) [0|0] "" Vector__XXX

BO_ 551 OCS1P_debugCushionMutCNT: 8 Vector__XXX
 SG_ OCS1P_cushionMutCNTFreqMed : 48|16@1+ (10,0) [0|0] "" Vector__XXX
 SG_ OCS1P_cushionMutCNTDuty : 32|16@1+ (1,0) [0|0] "" Vector__XXX
 SG_ OCS1P_cushionMutCNTFreq : 0|32@1+ (1,0) [0|0] "" Vector__XXX

BO_ 561 OCS1P_debugSeatbackSelfCNT: 8 Vector__XXX
 SG_ OCS1P_seatbackSelfCNTFreqMed : 48|16@1+ (10,0) [0|0] "" Vector__XXX
 SG_ OCS1P_seatbackSelfCNTDuty : 32|16@1+ (1,0) [0|0] "" Vector__XXX
 SG_ OCS1P_seatbackSelfCNTFreq : 0|32@1+ (1,0) [0|0] "" Vector__XXX

BO_ 565 OCS1P_debugTHS: 4 Vector__XXX
 SG_ OCS1P_humidity : 16|16@1+ (0.1,0) [0|0] "" Vector__XXX
 SG_ OCS1P_temperature : 0|16@1- (0.1,0) [0|0] "" Vector__XXX

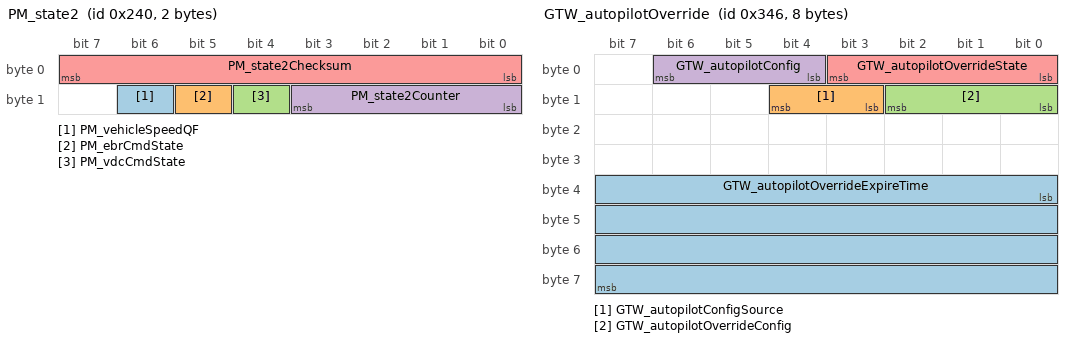
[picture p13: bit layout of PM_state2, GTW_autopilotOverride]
BO_ 576 PM_state2: 2 Vector__XXX
 SG_ PM_vehicleSpeedQF : 14|1@1+ (1,0) [0|0] "" Vector__XXX
 SG_ PM_ebrCmdState : 13|1@1+ (1,0) [0|0] "" Vector__XXX
 SG_ PM_vdcCmdState : 12|1@1+ (1,0) [0|0] "" Vector__XXX
 SG_ PM_state2Counter : 8|4@1+ (1,0) [0|0] "" Vector__XXX
 SG_ PM_state2Checksum : 0|8@1+ (1,0) [0|0] "" Vector__XXX

BO_ 783 OCS1P_debugCushionMutCNTComp: 6 Vector__XXX
 SG_ OCS1P_deltaFreqCushionMut : 32|16@1- (1,0) [0|0] "" Vector__XXX
 SG_ OCS1P_cushionMutCNTFreqComp : 0|16@1+ (1,0) [0|0] "" Vector__XXX

BO_ 838 GTW_autopilotOverride: 8 Vector__XXX
 SG_ GTW_autopilotOverrideExpireTime : 32|32@1+ (1,0) [0|0] "" Vector__XXX
 SG_ GTW_autopilotConfigSource : 11|2@1+ (1,0) [0|0] "" Vector__XXX
 SG_ GTW_autopilotOverrideConfig : 8|3@1+ (1,0) [0|0] "" Vector__XXX
 SG_ GTW_autopilotConfig : 4|3@1+ (1,0) [0|0] "" Vector__XXX
 SG_ GTW_autopilotOverrideState : 0|4@1+ (1,0) [0|0] "" Vector__XXX

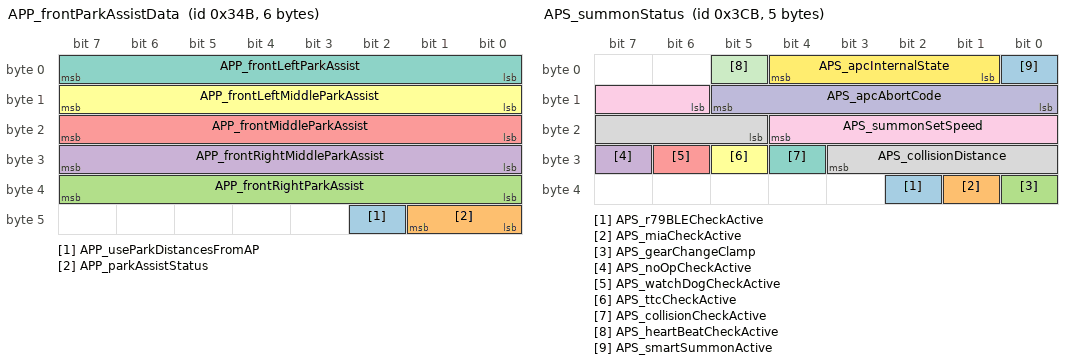
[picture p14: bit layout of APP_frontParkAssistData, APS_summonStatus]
BO_ 843 APP_frontParkAssistData: 6 Vector__XXX
 SG_ APP_useParkDistancesFromAP : 42|1@1+ (1,0) [0|0] "" Vector__XXX
 SG_ APP_parkAssistStatus : 40|2@1+ (1,0) [0|0] "" Vector__XXX
 SG_ APP_frontRightParkAssist : 32|8@1+ (1,0) [0|0] "" Vector__XXX
 SG_ APP_frontRightMiddleParkAssist : 24|8@1+ (1,0) [0|0] "" Vector__XXX
 SG_ APP_frontMiddleParkAssist : 16|8@1+ (1,0) [0|0] "" Vector__XXX
 SG_ APP_frontLeftMiddleParkAssist : 8|8@1+ (1,0) [0|0] "" Vector__XXX
 SG_ APP_frontLeftParkAssist : 0|8@1+ (1,0) [0|0] "" Vector__XXX

BO_ 847 OCS1P_debugCushionSelfCNTComp: 8 Vector__XXX
 SG_ OCS1P_deltaCapCushionSelf : 48|16@1- (0.0025,0) [0|0] "" Vector__XXX
 SG_ OCS1P_deltaFreqCushionSelf : 32|16@1- (1,0) [0|0] "" Vector__XXX
 SG_ OCS1P_cushionSelfCNTCap : 16|16@1+ (0.005,0) [0|0] "" Vector__XXX
 SG_ OCS1P_cushionSelfCNTFreqComp : 0|16@1+ (1,0) [0|0] "" Vector__XXX

BO_ 852 UI_uiHealthStatus: 6 Vector__XXX
 SG_ UI_rearDisplayCompositorOk : 31|1@1+ (1,0) [0|0] "" Vector__XXX
 SG_ UI_rearDisplayWindowManagerOk : 30|1@1+ (1,0) [0|0] "" Vector__XXX
 SG_ UI_rearDisplayHardwareOk : 29|1@1+ (1,0) [0|0] "" Vector__XXX
 SG_ UI_rearDisplayCrtcOk : 28|1@1+ (1,0) [0|0] "" Vector__XXX
 SG_ UI_rearDisplaySM : 25|3@1+ (1,0) [0|0] "" Vector__XXX
 SG_ UI_rearDisplayPowerOn : 24|1@1+ (1,0) [0|0] "" Vector__XXX
 SG_ UI_rearDisplayRunning : 23|1@1+ (1,0) [0|0] "" Vector__XXX
 SG_ UI_autonomyDASServerStatus : 21|2@1+ (1,0) [0|0] "" Vector__XXX
 SG_ UI_autonomyQtCarRearStatus : 19|2@1+ (1,0) [0|0] "" Vector__XXX
 SG_ UI_autonomyQtCarStatus : 17|2@1+ (1,0) [0|0] "" Vector__XXX
 SG_ UI_autonomyConnectivtyHWOk : 16|1@1+ (1,0) [0|0] "" Vector__XXX
 SG_ UI_autonomyConnectivityStatus : 14|2@1+ (1,0) [0|0] "" Vector__XXX
 SG_ UI_autonomyRearDispStatus : 12|2@1+ (1,0) [0|0] "" Vector__XXX
 SG_ UI_autonomyCenterDispStatus : 10|2@1+ (1,0) [0|0] "" Vector__XXX
 SG_ UI_apVisualizationOk : 9|1@1+ (1,0) [0|0] "" Vector__XXX
 SG_ UI_centerDisplayCompositorOk : 8|1@1+ (1,0) [0|0] "" Vector__XXX
 SG_ UI_centerDisplayWindowManagerOk : 7|1@1+ (1,0) [0|0] "" Vector__XXX
 SG_ UI_centerDisplayHardwareOk : 6|1@1+ (1,0) [0|0] "" Vector__XXX
 SG_ UI_centerDisplayCrtcOk : 5|1@1+ (1,0) [0|0] "" Vector__XXX
 SG_ UI_centerDisplayPowerOn : 4|1@1+ (1,0) [0|0] "" Vector__XXX
 SG_ UI_centerDisplaySM : 1|3@1+ (1,0) [0|0] "" Vector__XXX
 SG_ UI_centerDisplayRunning : 0|1@1+ (1,0) [0|0] "" Vector__XXX

BO_ 939 APP_driverMonitorStatus: 5 Vector__XXX
 SG_ APP_ADDWSystemStatus : 28|2@1+ (1,0) [0|0] "" Vector__XXX
 SG_ APP_cabinLowLuxHyst : 27|1@1+ (1,0) [0|0] "" Vector__XXX
 SG_ APP_cabinCamDarkHyst : 26|1@1+ (1,0) [0|0] "" Vector__XXX
 SG_ APP_handsOnInputRequired : 25|1@1+ (1,0) [0|0] "" Vector__XXX
 SG_ APP_driverSeatUnoccupied : 24|1@1+ (1,0) [0|0] "" Vector__XXX
 SG_ APP_driverHandsNotReady : 23|1@1+ (1,0) [0|0] "" Vector__XXX
 SG_ APP_driverLowEyeVisibility : 22|1@1+ (1,0) [0|0] "" Vector__XXX
 SG_ APP_driverLeaningBack : 21|1@1+ (1,0) [0|0] "" Vector__XXX
 SG_ APP_cabinCamInconsistent : 20|1@1+ (1,0) [0|0] "" Vector__XXX
 SG_ APP_cabinLowLux : 19|1@1+ (1,0) [0|0] "" Vector__XXX
 SG_ APP_driverSunglassesUseHyst : 18|1@1+ (1,0) [0|0] "" Vector__XXX
 SG_ APP_driverHeadCappedHyst : 17|1@1+ (1,0) [0|0] "" Vector__XXX
 SG_ APP_driverLowNominal : 16|1@1+ (1,0) [0|0] "" Vector__XXX
 SG_ APP_driverStateUnknownHyst : 15|1@1+ (1,0) [0|0] "" Vector__XXX
 SG_ APP_driverNotLively : 14|1@1+ (1,0) [0|0] "" Vector__XXX
 SG_ APP_driverStateUnknown : 13|1@1+ (1,0) [0|0] "" Vector__XXX
 SG_ APP_cabinCamDark : 12|1@1+ (1,0) [0|0] "" Vector__XXX
 SG_ APP_cabinCamBlinded : 11|1@1+ (1,0) [0|0] "" Vector__XXX
 SG_ APP_handsOnDetectedSource : 8|3@1+ (1,0) [0|0] "" Vector__XXX
 SG_ APP_handsOnDetected : 5|1@1+ (1,0) [0|0] "" Vector__XXX
 SG_ APP_attnBasedDriverMonitorOn : 4|1@1+ (1,0) [0|0] "" Vector__XXX
 SG_ APP_attnMonitorVersion : 1|3@1+ (1,0) [0|0] "" Vector__XXX
 SG_ APP_cabinCamTelemetryOn : 0|1@1+ (1,0) [0|0] "" Vector__XXX

BO_ 943 OCS1P_debugSeatbackSelfCNTComp: 8 Vector__XXX
 SG_ OCS1P_deltaCapSeatbackSelf : 48|16@1- (0.0025,0) [0|0] "" Vector__XXX
 SG_ OCS1P_deltaFreqSeatbackSelf : 32|16@1- (1,0) [0|0] "" Vector__XXX
 SG_ OCS1P_seatbackSelfCNTCap : 16|16@1+ (0.005,0) [0|0] "" Vector__XXX
 SG_ OCS1P_seatbackSelfCNTFreqComp : 0|16@1+ (1,0) [0|0] "" Vector__XXX

BO_ 971 APS_summonStatus: 5 Vector__XXX
 SG_ APS_r79BLECheckActive : 34|1@1+ (1,0) [0|0] "" Vector__XXX
 SG_ APS_miaCheckActive : 33|1@1+ (1,0) [0|0] "" Vector__XXX
 SG_ APS_gearChangeClamp : 32|1@1+ (1,0) [0|0] "" Vector__XXX
 SG_ APS_noOpCheckActive : 31|1@1+ (1,0) [0|0] "" Vector__XXX
 SG_ APS_watchDogCheckActive : 30|1@1+ (1,0) [0|0] "" Vector__XXX
 SG_ APS_ttcCheckActive : 29|1@1+ (1,0) [0|0] "" Vector__XXX
 SG_ APS_collisionCheckActive : 28|1@1+ (1,0) [0|0] "" Vector__XXX
 SG_ APS_collisionDistance : 21|7@1+ (0.05,0) [0|0] "" Vector__XXX
 SG_ APS_summonSetSpeed : 14|7@1+ (0.1,0) [0|0] "" Vector__XXX
 SG_ APS_apcAbortCode : 8|6@1+ (1,0) [0|0] "" Vector__XXX
 SG_ APS_heartBeatCheckActive : 5|1@1+ (1,0) [0|0] "" Vector__XXX
 SG_ APS_apcInternalState : 1|4@1+ (1,0) [0|0] "" Vector__XXX
 SG_ APS_smartSummonActive : 0|1@1+ (1,0) [0|0] "" Vector__XXX

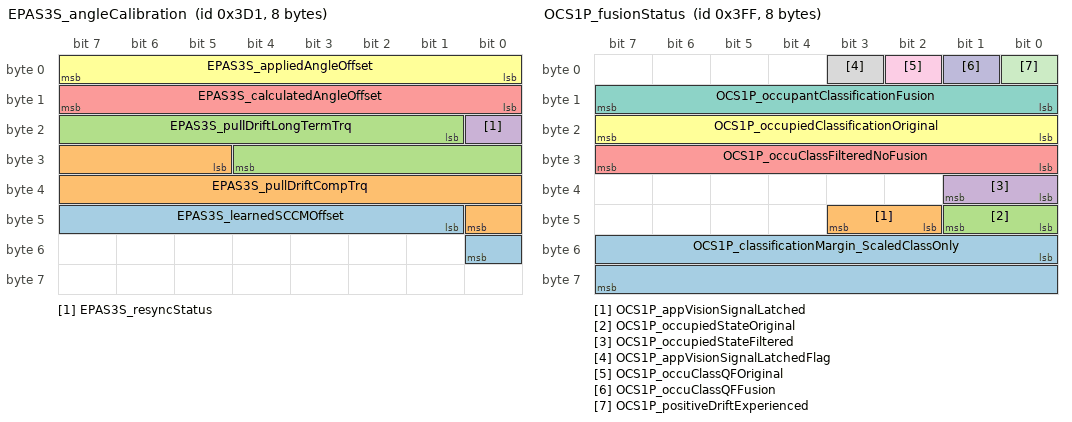
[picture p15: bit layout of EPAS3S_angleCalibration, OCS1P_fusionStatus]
BO_ 977 EPAS3S_angleCalibration: 8 Vector__XXX
 SG_ EPAS3S_learnedSCCMOffset : 41|8@1+ (0.1,-12.8) [0|0] "" Vector__XXX
 SG_ EPAS3S_pullDriftCompTrq : 29|12@1+ (0.01,-10) [0|0] "" Vector__XXX
 SG_ EPAS3S_pullDriftLongTermTrq : 17|12@1+ (0.01,-10) [0|0] "" Vector__XXX
 SG_ EPAS3S_resyncStatus : 16|1@1+ (1,0) [0|0] "" Vector__XXX
 SG_ EPAS3S_calculatedAngleOffset : 8|8@1+ (0.1,-12.8) [0|0] "" Vector__XXX
 SG_ EPAS3S_appliedAngleOffset : 0|8@1+ (0.1,-12.8) [0|0] "" Vector__XXX

BO_ 988 UI_summonGoal: 8 Vector__XXX
 SG_ UI_goalOrientation : 57|7@1+ (2.8125,0) [0|0] "" Vector__XXX
 SG_ UI_goalLongitude : 28|29@1- (1e-06,0) [0|0] "" Vector__XXX
 SG_ UI_goalLatitude : 0|28@1- (1e-06,0) [0|0] "" Vector__XXX

BO_ 1023 OCS1P_fusionStatus: 8 Vector__XXX
 SG_ OCS1P_classificationMargin_ScaledClassOnly : 48|16@1- (2,0) [0|0] "" Vector__XXX
 SG_ OCS1P_appVisionSignalLatched : 42|2@1+ (1,0) [0|0] "" Vector__XXX
 SG_ OCS1P_occupiedStateOriginal : 40|2@1+ (1,0) [0|0] "" Vector__XXX
 SG_ OCS1P_occupiedStateFiltered : 32|2@1+ (1,0) [0|0] "" Vector__XXX
 SG_ OCS1P_occuClassFilteredNoFusion : 24|8@1+ (1,0) [0|0] "" Vector__XXX
 SG_ OCS1P_occupiedClassificationOriginal : 16|8@1+ (1,0) [0|0] "" Vector__XXX
 SG_ OCS1P_occupantClassificationFusion : 8|8@1+ (1,0) [0|0] "" Vector__XXX
 SG_ OCS1P_appVisionSignalLatchedFlag : 3|1@1+ (1,0) [0|0] "" Vector__XXX
 SG_ OCS1P_occuClassQFOriginal : 2|1@1+ (1,0) [0|0] "" Vector__XXX
 SG_ OCS1P_occuClassQFFusion : 1|1@1+ (1,0) [0|0] "" Vector__XXX
 SG_ OCS1P_positiveDriftExperienced : 0|1@1+ (1,0) [0|0] "" Vector__XXX

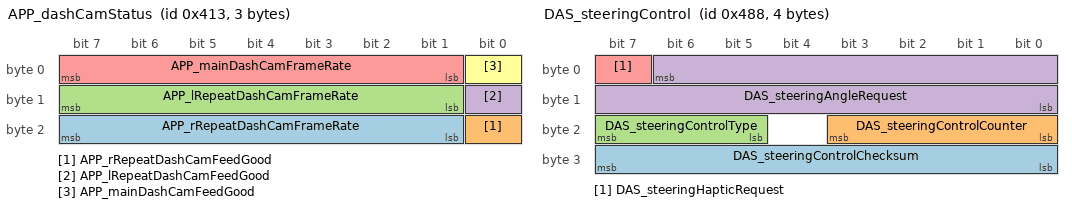
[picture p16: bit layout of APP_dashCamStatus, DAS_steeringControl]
BO_ 1043 APP_dashCamStatus: 3 Vector__XXX
 SG_ APP_rRepeatDashCamFrameRate : 17|7@1+ (1,0) [0|0] "" Vector__XXX
 SG_ APP_rRepeatDashCamFeedGood : 16|1@1+ (1,0) [0|0] "" Vector__XXX
 SG_ APP_lRepeatDashCamFrameRate : 9|7@1+ (1,0) [0|0] "" Vector__XXX
 SG_ APP_lRepeatDashCamFeedGood : 8|1@1+ (1,0) [0|0] "" Vector__XXX
 SG_ APP_mainDashCamFrameRate : 1|7@1+ (1,0) [0|0] "" Vector__XXX
 SG_ APP_mainDashCamFeedGood : 0|1@1+ (1,0) [0|0] "" Vector__XXX

BO_ 1045 APP_backupDashCamStatus: 1 Vector__XXX
 SG_ APP_backupDashCamFrameRate : 1|7@1+ (1,0) [0|0] "" Vector__XXX
 SG_ APP_backupDashCamFeedGood : 0|1@1+ (1,0) [0|0] "" Vector__XXX

BO_ 1048 GTW_chNm: 2 Vector__XXX
 SG_ GTW_chWakeUpReason : 8|5@1+ (1,0) [0|0] "" Vector__XXX
 SG_ GTW_chHeartBeatCounter : 4|4@1+ (1,0) [0|0] "" Vector__XXX
 SG_ GTW_chWakeUpBus : 1|1@1+ (1,0) [0|0] "" Vector__XXX
 SG_ GTW_chGotoSleep : 0|1@1+ (1,0) [0|0] "" Vector__XXX

BO_ 1061 APP_factorySummonGoal: 8 Vector__XXX
 SG_ APP_factoryGoalSpeed : 57|7@1+ (1,0) [0|0] "" Vector__XXX
 SG_ APP_factoryGoalLongitude : 28|29@1- (1e-06,0) [0|0] "" Vector__XXX
 SG_ APP_factoryGoalLatitude : 0|28@1- (1e-06,0) [0|0] "" Vector__XXX

BO_ 1149 APP_warningMatrix6: 8 Vector__XXX
 SG_ APP_w448_leftRepeaterImagerConfigMismatch : 63|1@1+ (1,0) [0|0] "" Vector__XXX
 SG_ APP_w447_rightPillarImagerConfigMismatch : 62|1@1+ (1,0) [0|0] "" Vector__XXX
 SG_ APP_w446_leftPillarImagerConfigMismatch : 61|1@1+ (1,0) [0|0] "" Vector__XXX
 SG_ APP_w445_fisheyeImagerConfigMismatch : 60|1@1+ (1,0) [0|0] "" Vector__XXX
 SG_ APP_w444_narrowImagerConfigMismatch : 59|1@1+ (1,0) [0|0] "" Vector__XXX
 SG_ APP_w443_mainImagerConfigMismatch : 58|1@1+ (1,0) [0|0] "" Vector__XXX
 SG_ APP_w442_autonomyCancelMethod : 57|1@1+ (1,0) [0|0] "" Vector__XXX
 SG_ APP_w441_cabinCamLEDRailOff : 56|1@1+ (1,0) [0|0] "" Vector__XXX
 SG_ APP_w440_lensHoodOcclusion : 55|1@1+ (1,0) [0|0] "" Vector__XXX
 SG_ APP_w439_ethernetCommFailure : 54|1@1+ (1,0) [0|0] "" Vector__XXX
 SG_ APP_w438_rcuMia : 53|1@1+ (1,0) [0|0] "" Vector__XXX
 SG_ APP_w437_missingCloudEepromData : 52|1@1+ (1,0) [0|0] "" Vector__XXX
 SG_ APP_w436_camCsiError : 51|1@1+ (1,0) [0|0] "" Vector__XXX
 SG_ APP_w435_repeaterAeroRibInfoMismatched : 50|1@1+ (1,0) [0|0] "" Vector__XXX
 SG_ APP_w434_rightRepeaterDowngradeDetected : 49|1@1+ (1,0) [0|0] "" Vector__XXX
 SG_ APP_w433_leftRepeaterDowngradeDetected : 48|1@1+ (1,0) [0|0] "" Vector__XXX
 SG_ APP_w432_frontVisibilityDegraded_HIGH : 47|1@1+ (1,0) [0|0] "" Vector__XXX
 SG_ APP_w431_frontVisibilityDegraded_MEDIUM : 46|1@1+ (1,0) [0|0] "" Vector__XXX
 SG_ APP_w430_frontVisibilityDegraded_LOW : 45|1@1+ (1,0) [0|0] "" Vector__XXX
 SG_ APP_w429_cameraVisPopUpFascia : 44|1@1+ (1,0) [0|0] "" Vector__XXX
 SG_ APP_w428_cameraVisPopUpBackup : 43|1@1+ (1,0) [0|0] "" Vector__XXX
 SG_ APP_w427_cameraVisPopUpRRepeater : 42|1@1+ (1,0) [0|0] "" Vector__XXX
 SG_ APP_w426_cameraVisPopUpLRepeater : 41|1@1+ (1,0) [0|0] "" Vector__XXX
 SG_ APP_w425_cameraVisPopUpRPillar : 40|1@1+ (1,0) [0|0] "" Vector__XXX
 SG_ APP_w424_cameraVisPopUpLPillar : 39|1@1+ (1,0) [0|0] "" Vector__XXX
 SG_ APP_w423_cameraVisPopUpForward : 38|1@1+ (1,0) [0|0] "" Vector__XXX
 SG_ APP_w422_autonomyDegradedUser : 37|1@1+ (1,0) [0|0] "" Vector__XXX
 SG_ APP_w421_autonomyUnavailableUser : 36|1@1+ (1,0) [0|0] "" Vector__XXX
 SG_ APP_w420_autonomyDegradedApSystem : 35|1@1+ (1,0) [0|0] "" Vector__XXX
 SG_ APP_w419_autonomyUnavailableApSystem : 34|1@1+ (1,0) [0|0] "" Vector__XXX
 SG_ APP_w418_autonomyDegradedVisibility : 33|1@1+ (1,0) [0|0] "" Vector__XXX
 SG_ APP_w417_autonomyUnavailableVisibility : 32|1@1+ (1,0) [0|0] "" Vector__XXX
 SG_ APP_w416_autonomyDegradedSystem : 31|1@1+ (1,0) [0|0] "" Vector__XXX
 SG_ APP_w415_autonomyUnavailableSystem : 30|1@1+ (1,0) [0|0] "" Vector__XXX
 SG_ APP_w413_autonomyDegraded5 : 28|1@1+ (1,0) [0|0] "" Vector__XXX
 SG_ APP_w412_abortBackupCamOccluded : 27|1@1+ (1,0) [0|0] "" Vector__XXX
 SG_ APP_w411_backupCameraOccluded : 26|1@1+ (1,0) [0|0] "" Vector__XXX
 SG_ APP_w410_autonomyDegraded4 : 25|1@1+ (1,0) [0|0] "" Vector__XXX
 SG_ APP_w409_autonomyDegraded3 : 24|1@1+ (1,0) [0|0] "" Vector__XXX
 SG_ APP_w408_autonomyDegraded2 : 23|1@1+ (1,0) [0|0] "" Vector__XXX
 SG_ APP_w407_autonomyDegraded1 : 22|1@1+ (1,0) [0|0] "" Vector__XXX
 SG_ APP_w406_gnssHWHealthDegraded : 21|1@1+ (1,0) [0|0] "" Vector__XXX
 SG_ APP_w405_apsMia : 20|1@1+ (1,0) [0|0] "" Vector__XXX
 SG_ APP_w404_epbrMiaVehBus : 19|1@1+ (1,0) [0|0] "" Vector__XXX
 SG_ APP_w403_notifyCameraSelfCleanAction : 18|1@1+ (1,0) [0|0] "" Vector__XXX
 SG_ APP_w402_rightPillarCameraHeaterFaulted : 17|1@1+ (1,0) [0|0] "" Vector__XXX
 SG_ APP_w401_leftPillarCameraHeaterFaulted : 16|1@1+ (1,0) [0|0] "" Vector__XXX
 SG_ APP_w400_selfieCameraFanFault : 15|1@1+ (1,0) [0|0] "" Vector__XXX
 SG_ APP_w399_brakeboosterMia : 14|1@1+ (1,0) [0|0] "" Vector__XXX
 SG_ APP_w398_imuOutputUnhealthy : 13|1@1+ (1,0) [0|0] "" Vector__XXX
 SG_ APP_w397_apFeatDisabledPermanent : 12|1@1+ (1,0) [0|0] "" Vector__XXX
 SG_ APP_w396_severeResidueDetected : 11|1@1+ (1,0) [0|0] "" Vector__XXX
 SG_ APP_w395_cabinCameraLEDFaultSvc : 10|1@1+ (1,0) [0|0] "" Vector__XXX
 SG_ APP_w394_apImuGrossErrors : 9|1@1+ (1,0) [0|0] "" Vector__XXX
 SG_ APP_w393_attnMntrUnavailable : 8|1@1+ (1,0) [0|0] "" Vector__XXX
 SG_ APP_w392_fsdSuspended : 7|1@1+ (1,0) [0|0] "" Vector__XXX
 SG_ APP_w391_cabinCameraBlockedonAP : 6|1@1+ (1,0) [0|0] "" Vector__XXX
 SG_ APP_w390_cabinCamVisDegraded : 5|1@1+ (1,0) [0|0] "" Vector__XXX
 SG_ APP_w389_camFovResidueDetected : 4|1@1+ (1,0) [0|0] "" Vector__XXX
 SG_ APP_w388_windshieldCameraHeaterFaulted : 3|1@1+ (1,0) [0|0] "" Vector__XXX
 SG_ APP_w387_radarBlockageDetected : 2|1@1+ (1,0) [0|0] "" Vector__XXX
 SG_ APP_w386_radarOnlyBrakingEvent : 1|1@1+ (1,0) [0|0] "" Vector__XXX
 SG_ APP_w385_posEngineUnhealthy : 0|1@1+ (1,0) [0|0] "" Vector__XXX

BO_ 1151 APP_warningMatrix5: 8 Vector__XXX
 SG_ APP_w384_posEngineInitInMotion : 63|1@1+ (1,0) [0|0] "" Vector__XXX
 SG_ APP_w383_manyApRebootsWhileInP : 62|1@1+ (1,0) [0|0] "" Vector__XXX
 SG_ APP_w382_ubloxImuTimestampIssue : 61|1@1+ (1,0) [0|0] "" Vector__XXX
 SG_ APP_w381_apImuTimestampIssue : 60|1@1+ (1,0) [0|0] "" Vector__XXX
 SG_ APP_w380_gnssPpsTimestampIssue : 59|1@1+ (1,0) [0|0] "" Vector__XXX
 SG_ APP_w379_positioningEngineMia : 58|1@1+ (1,0) [0|0] "" Vector__XXX
 SG_ APP_w378_ubloxImuMia : 57|1@1+ (1,0) [0|0] "" Vector__XXX
 SG_ APP_w377_apImuMia : 56|1@1+ (1,0) [0|0] "" Vector__XXX
 SG_ APP_w376_wheeltickCountMia : 55|1@1+ (1,0) [0|0] "" Vector__XXX
 SG_ APP_w375_gnssPpsMia : 54|1@1+ (1,0) [0|0] "" Vector__XXX
 SG_ APP_w374_gnssDataMia : 53|1@1+ (1,0) [0|0] "" Vector__XXX
 SG_ APP_w373_gnssUartError : 52|1@1+ (1,0) [0|0] "" Vector__XXX
 SG_ APP_w372_cabinCameraBlocked : 51|1@1+ (1,0) [0|0] "" Vector__XXX
 SG_ APP_w371_networkLoadingIssue : 50|1@1+ (1,0) [0|0] "" Vector__XXX
 SG_ APP_w370_accApUnavUserSettings : 49|1@1+ (1,0) [0|0] "" Vector__XXX
 SG_ APP_w369_cruiseWithSingleClick : 48|1@1+ (1,0) [0|0] "" Vector__XXX
 SG_ APP_w361_cabinCameraLEDFault : 40|1@1+ (1,0) [0|0] "" Vector__XXX
 SG_ APP_w360_apImuNoiseDetected : 39|1@1+ (1,0) [0|0] "" Vector__XXX
 SG_ APP_w359_aebDegraded : 38|1@1+ (1,0) [0|0] "" Vector__XXX
 SG_ APP_w358_isaSystemFault : 37|1@1+ (1,0) [0|0] "" Vector__XXX
 SG_ APP_w357_ddawSystemFault : 36|1@1+ (1,0) [0|0] "" Vector__XXX
 SG_ APP_w356_driverOverriding : 35|1@1+ (1,0) [0|0] "" Vector__XXX
 SG_ APP_w355_camQuadPowerFault : 34|1@1+ (1,0) [0|0] "" Vector__XXX
 SG_ APP_w354_tradfcMia : 33|1@1+ (1,0) [0|0] "" Vector__XXX
 SG_ APP_w353_csiDevice2Down : 32|1@1+ (1,0) [0|0] "" Vector__XXX
 SG_ APP_w352_csiDevice1Down : 31|1@1+ (1,0) [0|0] "" Vector__XXX
 SG_ APP_w351_csiDevice0Down : 30|1@1+ (1,0) [0|0] "" Vector__XXX
 SG_ APP_w350_tradfcSensorMisaligned : 29|1@1+ (1,0) [0|0] "" Vector__XXX
 SG_ APP_w349_cameraPersistentlyFaulted : 28|1@1+ (1,0) [0|0] "" Vector__XXX
 SG_ APP_w348_cameraSwUpdateRequired : 27|1@1+ (1,0) [0|0] "" Vector__XXX
 SG_ APP_w347_vcbattMiaVehBus : 26|1@1+ (1,0) [0|0] "" Vector__XXX
 SG_ APP_w346_gpsSwEvent : 25|1@1+ (1,0) [0|0] "" Vector__XXX
 SG_ APP_w345_tradfcPerfDegraded : 24|1@1+ (1,0) [0|0] "" Vector__XXX
 SG_ APP_w344_tradfcDspAlgoTimeout : 23|1@1+ (1,0) [0|0] "" Vector__XXX
 SG_ APP_w343_tradfcDspSwError : 22|1@1+ (1,0) [0|0] "" Vector__XXX
 SG_ APP_w342_tradfcDspHwError : 21|1@1+ (1,0) [0|0] "" Vector__XXX
 SG_ APP_w341_tradfcCalibError : 20|1@1+ (1,0) [0|0] "" Vector__XXX
 SG_ APP_w340_tradfcCsiError : 19|1@1+ (1,0) [0|0] "" Vector__XXX
 SG_ APP_w339_tradfcRfTempError : 18|1@1+ (1,0) [0|0] "" Vector__XXX
 SG_ APP_w338_tradfcLfTempError : 17|1@1+ (1,0) [0|0] "" Vector__XXX
 SG_ APP_w337_tradfcRfPmicError : 16|1@1+ (1,0) [0|0] "" Vector__XXX
 SG_ APP_w336_tradfcLfPmicError : 15|1@1+ (1,0) [0|0] "" Vector__XXX
 SG_ APP_w335_tradfcRfSensorError : 14|1@1+ (1,0) [0|0] "" Vector__XXX
 SG_ APP_w334_frontCameraOccluded : 13|1@1+ (1,0) [0|0] "" Vector__XXX
 SG_ APP_w333_fsdUnavailableLocation : 12|1@1+ (1,0) [0|0] "" Vector__XXX
 SG_ APP_w332_cameraPositionsSwapped : 11|1@1+ (1,0) [0|0] "" Vector__XXX
 SG_ APP_w331_fsdDegradedUnavailable : 10|1@1+ (1,0) [0|0] "" Vector__XXX
 SG_ APP_w330_cabinCameraFault : 9|1@1+ (1,0) [0|0] "" Vector__XXX
 SG_ APP_w329_evasiveManeuver : 8|1@1+ (1,0) [0|0] "" Vector__XXX
 SG_ APP_w328_autoparkDegraded : 7|1@1+ (1,0) [0|0] "" Vector__XXX
 SG_ APP_w327_vehicleConfigMismatch : 6|1@1+ (1,0) [0|0] "" Vector__XXX
 SG_ APP_w326_kernelPanic : 5|1@1+ (1,0) [0|0] "" Vector__XXX
 SG_ APP_w325_watchdogReset : 4|1@1+ (1,0) [0|0] "" Vector__XXX
 SG_ APP_w324_adspMia : 3|1@1+ (1,0) [0|0] "" Vector__XXX
 SG_ APP_w323_drivableSpaceFCW : 2|1@1+ (1,0) [0|0] "" Vector__XXX
 SG_ APP_w322_autoWiperWash : 1|1@1+ (1,0) [0|0] "" Vector__XXX
 SG_ APP_w321_bmsMia : 0|1@1+ (1,0) [0|0] "" Vector__XXX

BO_ 1160 DAS_steeringControl: 4 Vector__XXX
 SG_ DAS_steeringControlChecksum : 31|8@0+ (1,0) [0|0] "" Vector__XXX
 SG_ DAS_steeringControlCounter : 19|4@0+ (1,0) [0|0] "" Vector__XXX
 SG_ DAS_steeringControlType : 23|3@0+ (1,0) [0|0] "" Vector__XXX
 SG_ DAS_steeringAngleRequest : 6|15@0+ (0.1,-1638.35) [0|0] "" Vector__XXX
 SG_ DAS_steeringHapticRequest : 7|1@0+ (1,0) [0|0] "" Vector__XXX

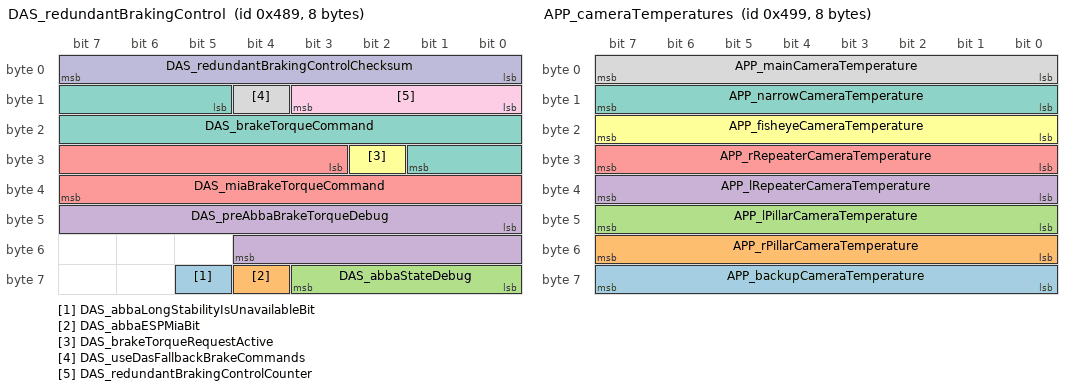
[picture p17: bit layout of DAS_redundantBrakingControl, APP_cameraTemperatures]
BO_ 1161 DAS_redundantBrakingControl: 8 Vector__XXX
 SG_ DAS_abbaLongStabilityIsUnavailableBit : 61|1@1+ (1,0) [0|0] "" Vector__XXX
 SG_ DAS_abbaESPMiaBit : 60|1@1+ (1,0) [0|0] "" Vector__XXX
 SG_ DAS_abbaStateDebug : 56|4@1+ (1,0) [0|0] "" Vector__XXX
 SG_ DAS_preAbbaBrakeTorqueDebug : 40|13@1+ (3,0) [0|0] "" Vector__XXX
 SG_ DAS_miaBrakeTorqueCommand : 27|13@1+ (3,0) [0|0] "" Vector__XXX
 SG_ DAS_brakeTorqueRequestActive : 26|1@1+ (1,0) [0|0] "" Vector__XXX
 SG_ DAS_brakeTorqueCommand : 13|13@1+ (3,0) [0|0] "" Vector__XXX
 SG_ DAS_useDasFallbackBrakeCommands : 12|1@1+ (1,0) [0|0] "" Vector__XXX
 SG_ DAS_redundantBrakingControlCounter : 8|4@1+ (1,0) [0|0] "" Vector__XXX
 SG_ DAS_redundantBrakingControlChecksum : 0|8@1+ (1,0) [0|0] "" Vector__XXX

BO_ 1177 APP_cameraTemperatures: 8 Vector__XXX
 SG_ APP_backupCameraTemperature : 56|8@1+ (1,-60) [0|0] "" Vector__XXX
 SG_ APP_rPillarCameraTemperature : 48|8@1+ (1,-60) [0|0] "" Vector__XXX
 SG_ APP_lPillarCameraTemperature : 40|8@1+ (1,-60) [0|0] "" Vector__XXX
 SG_ APP_lRepeaterCameraTemperature : 32|8@1+ (1,-60) [0|0] "" Vector__XXX
 SG_ APP_rRepeaterCameraTemperature : 24|8@1+ (1,-60) [0|0] "" Vector__XXX
 SG_ APP_fisheyeCameraTemperature : 16|8@1+ (1,-60) [0|0] "" Vector__XXX
 SG_ APP_narrowCameraTemperature : 8|8@1+ (1,-60) [0|0] "" Vector__XXX
 SG_ APP_mainCameraTemperature : 0|8@1+ (1,-60) [0|0] "" Vector__XXX

BO_ 1179 APP_cameraRedundancyInfo: 1 Vector__XXX
 SG_ APP_cameraTakeoverActionSource : 5|3@1+ (1,0) [0|0] "" Vector__XXX
 SG_ APP_cameraTakeoverAction : 2|3@1+ (1,0) [0|0] "" Vector__XXX
 SG_ APP_cameraHwControl : 0|2@1+ (1,0) [0|0] "" Vector__XXX

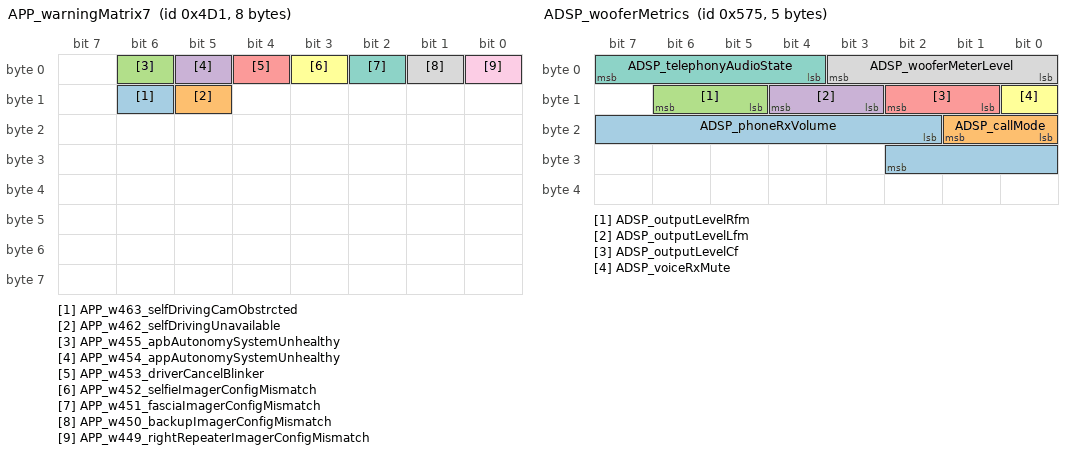
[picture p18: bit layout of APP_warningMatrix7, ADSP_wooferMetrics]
BO_ 1233 APP_warningMatrix7: 8 Vector__XXX
 SG_ APP_w463_selfDrivingCamObstrcted : 14|1@1+ (1,0) [0|0] "" Vector__XXX
 SG_ APP_w462_selfDrivingUnavailable : 13|1@1+ (1,0) [0|0] "" Vector__XXX
 SG_ APP_w455_apbAutonomySystemUnhealthy : 6|1@1+ (1,0) [0|0] "" Vector__XXX
 SG_ APP_w454_appAutonomySystemUnhealthy : 5|1@1+ (1,0) [0|0] "" Vector__XXX
 SG_ APP_w453_driverCancelBlinker : 4|1@1+ (1,0) [0|0] "" Vector__XXX
 SG_ APP_w452_selfieImagerConfigMismatch : 3|1@1+ (1,0) [0|0] "" Vector__XXX
 SG_ APP_w451_fasciaImagerConfigMismatch : 2|1@1+ (1,0) [0|0] "" Vector__XXX
 SG_ APP_w450_backupImagerConfigMismatch : 1|1@1+ (1,0) [0|0] "" Vector__XXX
 SG_ APP_w449_rightRepeaterImagerConfigMismatch : 0|1@1+ (1,0) [0|0] "" Vector__XXX

BO_ 1285 ESP_alertLog: 8 Vector__XXX
 SG_ ESP_alertState : 15|1@1+ (1,0) [0|0] "" Vector__XXX
 SG_ ESP_alertID : 0|9@1+ (1,0) [0|0] "" Vector__XXX

BO_ 1301 OCS1P_bootID: 8 Vector__XXX
 SG_ OCS1P_firmwareType : 56|8@1+ (1,0) [0|0] "" Vector__XXX
 SG_ OCS1P_usageID : 40|16@1+ (1,0) [0|0] "" Vector__XXX
 SG_ OCS1P_assemblyID : 32|8@1+ (1,0) [0|0] "" Vector__XXX
 SG_ OCS1P_pcbaID : 16|8@1+ (1,0) [0|0] "" Vector__XXX
 SG_ OCS1P_componentID : 0|16@1+ (1,0) [0|0] "" Vector__XXX

BO_ 1361 EPAS3S_bootID: 8 Vector__XXX
 SG_ EPAS3S_bootIdData : 0|64@1+ (1,0) [0|0] "" Vector__XXX

BO_ 1368 GTW_gitHash: 8 Vector__XXX
 SG_ GTW_appGitHash : 7|64@0+ (1,0) [0|0] "" Vector__XXX

BO_ 1383 ADSP_state: 8 Vector__XXX
 SG_ ADSP_microphoneDataState : 60|1@1+ (1,0) [0|0] "" Vector__XXX
 SG_ ADSP_requestFailoverSpeaker : 59|1@1+ (1,0) [0|0] "" Vector__XXX
 SG_ ADSP_a2baLoadShedded : 58|1@1+ (1,0) [0|0] "" Vector__XXX
 SG_ ADSP_eCallSpeakerStatus : 56|2@1+ (1,0) [0|0] "" Vector__XXX
 SG_ ADSP_eCallMicrophoneStatus : 53|2@1+ (1,0) [0|0] "" Vector__XXX
 SG_ ADSP_telephonyTxMute : 52|1@1+ (1,0) [0|0] "" Vector__XXX
 SG_ ADSP_callState : 51|1@1+ (1,0) [0|0] "" Vector__XXX
 SG_ ADSP_allAudioReady : 50|1@1+ (1,0) [0|0] "" Vector__XXX
 SG_ ADSP_eCallState : 49|1@1+ (1,0) [0|0] "" Vector__XXX
 SG_ ADSP_eCallSelfTest : 47|2@1+ (1,0) [0|0] "" Vector__XXX
 SG_ ADSP_eCall_ENS_state : 44|3@1+ (1,0) [0|0] "" Vector__XXX
 SG_ ADSP_spkMuteAll : 43|1@1+ (1,0) [0|0] "" Vector__XXX
 SG_ ADSP_ancMode : 38|5@1+ (1,0) [0|0] "" Vector__XXX
 SG_ ADSP_tunerSelect : 37|1@1+ (1,0) [0|0] "" Vector__XXX
 SG_ ADSP_sourceSelect : 35|2@1+ (1,0) [0|0] "" Vector__XXX
 SG_ ADSP_ancState : 32|3@1+ (1,0) [0|0] "" Vector__XXX
 SG_ ADSP_telephonyRxMute : 31|1@1+ (1,0) [0|0] "" Vector__XXX
 SG_ ADSP_tcuI2SEnabled : 28|1@1+ (1,0) [0|0] "" Vector__XXX
 SG_ ADSP_audioReady : 27|1@1+ (1,0) [0|0] "" Vector__XXX
 SG_ ADSP_baseamp3State : 24|3@1+ (1,0) [0|0] "" Vector__XXX
 SG_ ADSP_baseamp2State : 19|3@1+ (1,0) [0|0] "" Vector__XXX
 SG_ ADSP_baseamp1State : 16|3@1+ (1,0) [0|0] "" Vector__XXX
 SG_ ADSP_baseamp0State : 13|3@1+ (1,0) [0|0] "" Vector__XXX
 SG_ ADSP_a2bbState : 8|5@1+ (1,0) [0|0] "" Vector__XXX
 SG_ ADSP_a2baState : 0|5@1+ (1,0) [0|0] "" Vector__XXX

BO_ 1397 ADSP_wooferMetrics: 5 Vector__XXX
 SG_ ADSP_phoneRxVolume : 18|9@1- (1,0) [0|0] "" Vector__XXX
 SG_ ADSP_callMode : 16|2@1+ (1,0) [0|0] "" Vector__XXX
 SG_ ADSP_outputLevelRfm : 13|2@1+ (1,0) [0|0] "" Vector__XXX
 SG_ ADSP_outputLevelLfm : 11|2@1+ (1,0) [0|0] "" Vector__XXX
 SG_ ADSP_outputLevelCf : 9|2@1+ (1,0) [0|0] "" Vector__XXX
 SG_ ADSP_voiceRxMute : 8|1@1+ (1,0) [0|0] "" Vector__XXX
 SG_ ADSP_telephonyAudioState : 4|4@1+ (1,0) [0|0] "" Vector__XXX
 SG_ ADSP_wooferMeterLevel : 0|4@1+ (10,-100) [0|0] "" Vector__XXX

BO_ 1429 OCS1P_alertLog: 8 Vector__XXX
 SG_ OCS1P_a145_humidity m145 : 56|8@1+ (1,0) [0|0] "" Vector__XXX
 SG_ OCS1P_a000_alertDataW2 m0 : 48|16@1+ (1,0) [0|0] "" Vector__XXX
 SG_ OCS1P_a145_temperature m145 : 48|8@1+ (1,-40) [0|0] "" Vector__XXX
 SG_ OCS1P_a148_filtRBClass m148 : 43|3@1+ (1,0) [0|0] "" Vector__XXX
 SG_ OCS1P_a148_filtCapClass m148 : 40|3@1+ (1,0) [0|0] "" Vector__XXX
 SG_ OCS1P_a151_seatbackSelfMin m151 : 40|16@1+ (0.005,0) [0|0] "" Vector__XXX
 SG_ OCS1P_a154_seatbackSelfMin m154 : 40|16@1+ (0.005,0) [0|0] "" Vector__XXX
 SG_ OCS1P_a148_filtFreqClass m148 : 35|3@1+ (1,0) [0|0] "" Vector__XXX
 SG_ OCS1P_a000_alertDataW1 m0 : 32|16@1+ (1,0) [0|0] "" Vector__XXX
 SG_ OCS1P_a145_seatbackSelfOffset m145 : 32|16@1- (0.0025,0) [0|0] "" Vector__XXX
 SG_ OCS1P_a148_rawRBClass m148 : 32|3@1+ (1,0) [0|0] "" Vector__XXX
 SG_ OCS1P_a150_seatbackSelfBaseline m150 : 32|16@1+ (0.005,0) [0|0] "" Vector__XXX
 SG_ OCS1P_a152_seatbackSelfPreExit m152 : 32|16@1+ (0.005,0) [0|0] "" Vector__XXX
 SG_ OCS1P_a155_seatbackSelfBaseline m155 : 32|16@1+ (0.005,0) [0|0] "" Vector__XXX
 SG_ OCS1P_a148_rawCapClass m148 : 27|3@1+ (1,0) [0|0] "" Vector__XXX
 SG_ OCS1P_a148_rawFreqClass m148 : 24|3@1+ (1,0) [0|0] "" Vector__XXX
 SG_ OCS1P_a151_cushionSelfMin m151 : 24|16@1+ (0.005,0) [0|0] "" Vector__XXX
 SG_ OCS1P_a154_cushionSelfMin m154 : 24|16@1+ (0.005,0) [0|0] "" Vector__XXX
 SG_ OCS1P_a015_NVMMWriteFailed m15 : 21|1@1+ (1,0) [0|0] "" Vector__XXX
 SG_ OCS1P_a148_filtRBVsCap m148 : 21|1@1+ (1,0) [0|0] "" Vector__XXX
 SG_ OCS1P_a015_NVMMMemOverflow m15 : 20|1@1+ (1,0) [0|0] "" Vector__XXX
 SG_ OCS1P_a148_filtRBVsFreq m148 : 20|1@1+ (1,0) [0|0] "" Vector__XXX
 SG_ OCS1P_a015_NVMMRecordUpgraded m15 : 19|1@1+ (1,0) [0|0] "" Vector__XXX
 SG_ OCS1P_a148_filtCapVsFreq m148 : 19|1@1+ (1,0) [0|0] "" Vector__XXX
 SG_ OCS1P_a015_NVMMVersionMismatch m15 : 18|1@1+ (1,0) [0|0] "" Vector__XXX
 SG_ OCS1P_a148_rawRBVsCap m148 : 18|1@1+ (1,0) [0|0] "" Vector__XXX
 SG_ OCS1P_a015_NVMMCRCMismatch m15 : 17|1@1+ (1,0) [0|0] "" Vector__XXX
 SG_ OCS1P_a148_rawRBVsFreq m148 : 17|1@1+ (1,0) [0|0] "" Vector__XXX
 SG_ OCS1P_a000_alertDataW0 m0 : 16|16@1+ (1,0) [0|0] "" Vector__XXX
 SG_ OCS1P_a015_NVMMRecordNotFound m15 : 16|1@1+ (1,0) [0|0] "" Vector__XXX
 SG_ OCS1P_a121_sandwichFreq m121 : 16|32@1+ (1,0) [0|0] "" Vector__XXX
 SG_ OCS1P_a122_sandwichFreq m122 : 16|32@1+ (1,0) [0|0] "" Vector__XXX
 SG_ OCS1P_a123_sandwichFreq m123 : 16|32@1+ (1,0) [0|0] "" Vector__XXX
 SG_ OCS1P_a124_cushionSelfFreq m124 : 16|32@1+ (1,0) [0|0] "" Vector__XXX
 SG_ OCS1P_a125_cushionSelfFreq m125 : 16|32@1+ (1,0) [0|0] "" Vector__XXX
 SG_ OCS1P_a126_cushionSelfFreq m126 : 16|32@1+ (1,0) [0|0] "" Vector__XXX
 SG_ OCS1P_a127_seatbackSelfFreq m127 : 16|32@1+ (1,0) [0|0] "" Vector__XXX
 SG_ OCS1P_a128_seatbackSelfFreq m128 : 16|32@1+ (1,0) [0|0] "" Vector__XXX
 SG_ OCS1P_a129_seatbackSelfFreq m129 : 16|32@1+ (1,0) [0|0] "" Vector__XXX
 SG_ OCS1P_a130_sandwichNoCalib m130 : 16|1@1+ (1,0) [0|0] "" Vector__XXX
 SG_ OCS1P_a131_cushionSelfNoCalib m131 : 16|1@1+ (1,0) [0|0] "" Vector__XXX
 SG_ OCS1P_a132_seatbackSelfNoCalib m132 : 16|1@1+ (1,0) [0|0] "" Vector__XXX
 SG_ OCS1P_a133_sandwichBadCalib m133 : 16|1@1+ (1,0) [0|0] "" Vector__XXX
 SG_ OCS1P_a134_uninitializedCalib m134 : 16|1@1+ (1,0) [0|0] "" Vector__XXX
 SG_ OCS1P_a135_tempNoCalib m135 : 16|1@1+ (1,0) [0|0] "" Vector__XXX
 SG_ OCS1P_a136_cushionSelfDuty m136 : 16|32@1+ (1,0) [0|0] "" Vector__XXX
 SG_ OCS1P_a137_cushionSelfDuty m137 : 16|32@1+ (1,0) [0|0] "" Vector__XXX
 SG_ OCS1P_a138_seatbackSelfDuty m138 : 16|32@1+ (1,0) [0|0] "" Vector__XXX
 SG_ OCS1P_a139_seatbackSelfDuty m139 : 16|32@1+ (1,0) [0|0] "" Vector__XXX
 SG_ OCS1P_a140_tempInvalidCalib m140 : 16|1@1+ (1,0) [0|0] "" Vector__XXX
 SG_ OCS1P_a141_humidityInvalidCalib m141 : 16|1@1+ (1,0) [0|0] "" Vector__XXX
 SG_ OCS1P_a142_tempHumidityInvalid m142 : 16|1@1+ (1,0) [0|0] "" Vector__XXX
 SG_ OCS1P_a143_mismatchPassAirbag m143 : 16|1@1+ (1,0) [0|0] "" Vector__XXX
 SG_ OCS1P_a144_mismatchCarRegion m144 : 16|1@1+ (1,0) [0|0] "" Vector__XXX
 SG_ OCS1P_a145_cushionSelfOffset m145 : 16|16@1- (0.005,0) [0|0] "" Vector__XXX
 SG_ OCS1P_a148_rawCapVsFreq m148 : 16|1@1+ (1,0) [0|0] "" Vector__XXX
 SG_ OCS1P_a150_cushionSelfBaseline m150 : 16|16@1+ (0.005,0) [0|0] "" Vector__XXX
 SG_ OCS1P_a151_reason m151 : 16|3@1+ (1,0) [0|0] "" Vector__XXX
 SG_ OCS1P_a152_cushionSelfPreExit m152 : 16|16@1+ (0.005,0) [0|0] "" Vector__XXX
 SG_ OCS1P_a153_reason m153 : 16|3@1+ (1,0) [0|0] "" Vector__XXX
 SG_ OCS1P_a154_reason m154 : 16|3@1+ (1,0) [0|0] "" Vector__XXX
 SG_ OCS1P_a155_cushionSelfBaseline m155 : 16|16@1+ (0.005,0) [0|0] "" Vector__XXX
 SG_ OCS1P_alertState : 15|1@1+ (1,0) [0|0] "" Vector__XXX
 SG_ OCS1P_alertID M : 0|8@1+ (1,0) [0|0] "" Vector__XXX

BO_ 1469 IBST_alertLog: 8 Vector__XXX
 SG_ IBST_alertState : 15|1@1+ (1,0) [0|0] "" Vector__XXX
 SG_ IBST_alertID : 0|8@1+ (1,0) [0|0] "" Vector__XXX

BO_ 1497 DAS_carLog: 8 Vector__XXX
 SG_ DAS_pmmNotActivatingReason m2 : 53|5@1+ (1,0) [0|0] "" Vector__XXX
 SG_ DAS_closestInLaneTargetVxRel m4 : 52|10@1+ (0.1,-51.1) [0|0] "" Vector__XXX
 SG_ DAS_radarTarget4_dx m3 : 48|12@1+ (0.0625,0) [0|0] "" Vector__XXX
 SG_ DAS_accUnavailableReason m2 : 46|7@1+ (1,0) [0|0] "" Vector__XXX
 SG_ DAS_closestRightLaneTargetDx m4 : 40|12@1+ (0.0625,0) [0|0] "" Vector__XXX
 SG_ DAS_driveOnNavUnavailableReason m2 : 40|5@1+ (1,0) [0|0] "" Vector__XXX
 SG_ DAS_handsOnDetected m2 : 38|2@1+ (1,0) [0|0] "" Vector__XXX
 SG_ DAS_radarTarget1_VxRel m1 : 36|8@1+ (0.2,-25.6) [0|0] "" Vector__XXX
 SG_ DAS_radarTarget3_dx m3 : 36|12@1+ (0.0625,0) [0|0] "" Vector__XXX
 SG_ DAS_aeb_not_activating_reason m2 : 32|5@1+ (1,0) [0|0] "" Vector__XXX
 SG_ DAS_ACC_camStatus m2 : 30|2@1+ (1,0) [0|0] "" Vector__XXX
 SG_ DAS_closestLeftLaneTargetDx m4 : 28|12@1+ (0.0625,0) [0|0] "" Vector__XXX
 SG_ DAS_LC_handsOnReason m2 : 24|6@1+ (1,0) [0|0] "" Vector__XXX
 SG_ DAS_radarTarget1_dx m1 : 24|12@1+ (0.0625,0) [0|0] "" Vector__XXX
 SG_ DAS_radarTarget2_dx m3 : 24|12@1+ (0.0625,0) [0|0] "" Vector__XXX
 SG_ DAS_associated_rad_object m2 : 22|2@1+ (1,0) [0|0] "" Vector__XXX
 SG_ DAS_restrictionLowSpeedTraffic m2 : 21|1@1+ (1,0) [0|0] "" Vector__XXX
 SG_ DAS_constructionArea m2 : 19|2@1+ (1,0) [0|0] "" Vector__XXX
 SG_ DAS_desiredTarget_dx m3 : 16|8@1+ (0.5,0) [0|0] "" Vector__XXX
 SG_ DAS_fcmThreatAssesmentMode m2 : 16|3@1+ (1,0) [0|0] "" Vector__XXX
 SG_ DAS_secondInLaneTargetDx m4 : 16|12@1+ (0.0625,0) [0|0] "" Vector__XXX
 SG_ DAS_alcBehaviorState m0 : 15|3@1+ (1,0) [0|0] "" Vector__XXX
 SG_ DAS_alcBehaviorAbortReason m0 : 11|4@1+ (1,0) [0|0] "" Vector__XXX
 SG_ DAS_fcmCollisionStage3Checks m2 : 8|8@1+ (1,0) [0|0] "" Vector__XXX
 SG_ DAS_fcmSteeringOverride m2 : 7|1@1+ (1,0) [0|0] "" Vector__XXX
 SG_ DAS_mobileyeIPSOapproved m2 : 6|1@1+ (1,0) [0|0] "" Vector__XXX
 SG_ DAS_mobileyePedAebFlag m2 : 5|1@1+ (1,0) [0|0] "" Vector__XXX
 SG_ DAS_autosteerUnavailableReason m0 : 4|7@1+ (1,0) [0|0] "" Vector__XXX
 SG_ DAS_closestInLaneTargetDx m4 : 4|12@1+ (0.0625,0) [0|0] "" Vector__XXX
 SG_ DAS_mobileyeVehAebFlag m2 : 4|1@1+ (1,0) [0|0] "" Vector__XXX
 SG_ DAS_radarTarget5_dx m1 : 4|12@1+ (0.0625,0) [0|0] "" Vector__XXX
 SG_ DAS_carLogMultiplexer M : 0|4@1+ (1,0) [0|0] "" Vector__XXX

BO_ 1521 RCM_bootID: 8 Vector__XXX
 SG_ RCM_bootFirmwareType : 63|8@0+ (1,0) [0|0] "" Vector__XXX
 SG_ RCM_bootUsageId : 39|16@0+ (1,0) [0|0] "" Vector__XXX
 SG_ RCM_bootAssemblyId : 31|8@0+ (1,0) [0|0] "" Vector__XXX
 SG_ RCM_bootPcbaId : 23|8@0+ (1,0) [0|0] "" Vector__XXX
 SG_ RCM_bootComponentId : 7|16@0+ (1,0) [0|0] "" Vector__XXX

BO_ 1592 EPAS3P_udsResponseCH: 8 Vector__XXX
 SG_ EPAS3P_udsResponseDataCH : 7|64@0+ (1,0) [0|0] "" Vector__XXX

BO_ 1601 UDS_rcmRequest: 8 Vector__XXX
 SG_ UDS_rcmRequestData : 7|64@0+ (1,0) [0|0] "" Vector__XXX

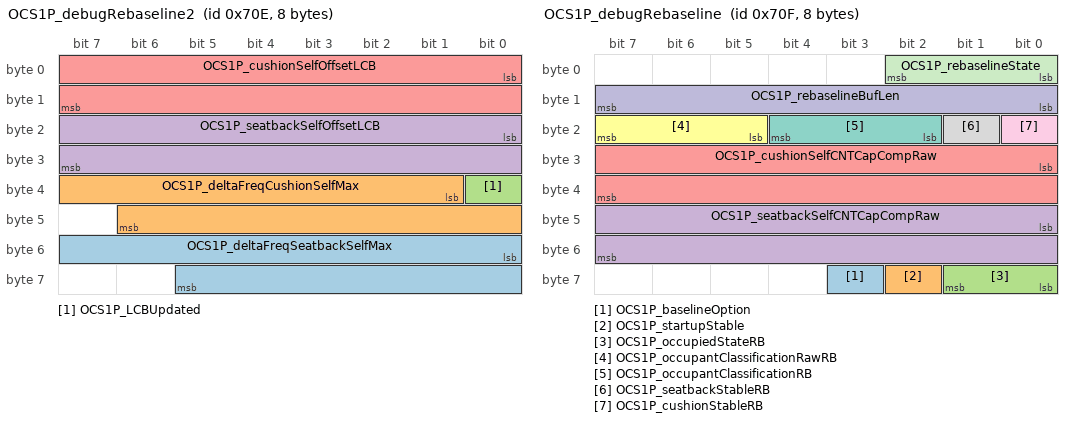
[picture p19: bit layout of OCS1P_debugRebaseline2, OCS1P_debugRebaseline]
BO_ 1806 OCS1P_debugRebaseline2: 8 Vector__XXX
 SG_ OCS1P_deltaFreqSeatbackSelfMax : 48|14@1- (10,0) [0|0] "" Vector__XXX
 SG_ OCS1P_deltaFreqCushionSelfMax : 33|14@1- (10,0) [0|0] "" Vector__XXX
 SG_ OCS1P_LCBUpdated : 32|1@1+ (1,0) [0|0] "" Vector__XXX
 SG_ OCS1P_seatbackSelfOffsetLCB : 16|16@1- (0.005,0) [0|0] "" Vector__XXX
 SG_ OCS1P_cushionSelfOffsetLCB : 0|16@1- (0.005,0) [0|0] "" Vector__XXX

BO_ 1807 OCS1P_debugRebaseline: 8 Vector__XXX
 SG_ OCS1P_baselineOption : 59|1@1+ (1,0) [0|0] "" Vector__XXX
 SG_ OCS1P_startupStable : 58|1@1+ (1,0) [0|0] "" Vector__XXX
 SG_ OCS1P_occupiedStateRB : 56|2@1+ (1,0) [0|0] "" Vector__XXX
 SG_ OCS1P_seatbackSelfCNTCapCompRaw : 40|16@1+ (0.005,0) [0|0] "" Vector__XXX
 SG_ OCS1P_cushionSelfCNTCapCompRaw : 24|16@1+ (0.005,0) [0|0] "" Vector__XXX
 SG_ OCS1P_occupantClassificationRawRB : 21|3@1+ (1,0) [0|0] "" Vector__XXX
 SG_ OCS1P_occupantClassificationRB : 18|3@1+ (1,0) [0|0] "" Vector__XXX
 SG_ OCS1P_seatbackStableRB : 17|1@1+ (1,0) [0|0] "" Vector__XXX
 SG_ OCS1P_cushionStableRB : 16|1@1+ (1,0) [0|0] "" Vector__XXX
 SG_ OCS1P_rebaselineBufLen : 8|8@1+ (1,0) [0|0] "" Vector__XXX
 SG_ OCS1P_rebaselineState : 0|3@1+ (1,0) [0|0] "" Vector__XXX

BO_ 1776 UNK_6F0_alive: 2 Vector__XXX
 SG_ UNK_6F0_crc : 0|8@1+ (1,0) [0|255] "" Vector__XXX
 SG_ UNK_6F0_counter : 8|4@1+ (1,0) [0|15] "" Vector__XXX

BO_ 1779 UNK_6F3_alive: 3 Vector__XXX
 SG_ UNK_6F3_crc : 0|8@1+ (1,0) [0|255] "" Vector__XXX
 SG_ UNK_6F3_counter : 8|4@1+ (1,0) [0|15] "" Vector__XXX

BO_ 654 UNK_28E_alive: 8 Vector__XXX
 SG_ UNK_28E_checksum : 0|8@1+ (1,0) [0|255] "" Vector__XXX
 SG_ UNK_28E_counter : 8|4@1+ (1,0) [0|15] "" Vector__XXX

BO_ 655 UNK_28F_alive: 8 Vector__XXX
 SG_ UNK_28F_checksum : 0|8@1+ (1,0) [0|255] "" Vector__XXX
 SG_ UNK_28F_counter : 8|4@1+ (1,0) [0|15] "" Vector__XXX

BO_ 608 UNK_260: 8 Vector__XXX
 SG_ UNK_260_flag : 0|1@1+ (1,0) [0|1] "" Vector__XXX
 SG_ UNK_260_counter : 52|4@1+ (1,0) [0|15] "" Vector__XXX
 SG_ UNK_260_checksum : 56|8@1+ (1,0) [0|255] "" Vector__XXX

BO_ 337 UNK_151: 8 Vector__XXX
 SG_ UNK_151_state : 48|2@1+ (1,0) [0|3] "" Vector__XXX

CM_ BO_ 963 "ESP32-DualCAN Model3_VEH. Seen on this car: 8-byte frames; fit good (bits covered 100%, mux 100%, ranges 100%).";
VAL_ 963 VCRIGHT_rearRightOccupancySwitch 0 "SNA" 1 "OFF" 2 "ON" 3 "FAULT" ;
VAL_ 963 VCRIGHT_rearCenterBuckleSwitch 0 "SNA" 1 "OFF" 2 "ON" 3 "FAULT" ;
VAL_ 963 VCRIGHT_frontOccupancySwitch 0 "SNA" 1 "OFF" 2 "ON" 3 "FAULT" ;
VAL_ 963 VCRIGHT_frontBuckleSwitch 0 "SNA" 1 "OFF" 2 "ON" 3 "FAULT" ;
VAL_ 963 VCRIGHT_frontSeatLumbarOut 0 "SNA" 1 "OFF" 2 "ON" 3 "FAULT" ;
VAL_ 963 VCRIGHT_frontSeatLumbarIn 0 "SNA" 1 "OFF" 2 "ON" 3 "FAULT" ;
VAL_ 963 VCRIGHT_frontSeatLumbarUp 0 "SNA" 1 "OFF" 2 "ON" 3 "FAULT" ;
VAL_ 963 VCRIGHT_frontSeatLumbarDown 0 "SNA" 1 "OFF" 2 "ON" 3 "FAULT" ;
VAL_ 963 VCRIGHT_frontSeatBackrestForward 0 "SNA" 1 "OFF" 2 "ON" 3 "FAULT" ;
VAL_ 963 VCRIGHT_frontSeatBackrestBack 0 "SNA" 1 "OFF" 2 "ON" 3 "FAULT" ;
VAL_ 963 VCRIGHT_frontSeatLiftUp 0 "SNA" 1 "OFF" 2 "ON" 3 "FAULT" ;
VAL_ 963 VCRIGHT_frontSeatLiftDown 0 "SNA" 1 "OFF" 2 "ON" 3 "FAULT" ;
VAL_ 963 VCRIGHT_frontSeatTiltUp 0 "SNA" 1 "OFF" 2 "ON" 3 "FAULT" ;
VAL_ 963 VCRIGHT_frontSeatTiltDown 0 "SNA" 1 "OFF" 2 "ON" 3 "FAULT" ;
VAL_ 963 VCRIGHT_frontSeatTrackForward 0 "SNA" 1 "OFF" 2 "ON" 3 "FAULT" ;
VAL_ 963 VCRIGHT_frontSeatTrackBack 0 "SNA" 1 "OFF" 2 "ON" 3 "FAULT" ;
VAL_ 963 VCRIGHT_switchStatusIndex 0 "0" 1 "1" 2 "INVALID" ;
CM_ BO_ 989 "ESP32-DualCAN Model3_VEH. Seen on this car: 8-byte frames; fit good (bits covered 100%, mux 91%, ranges 100%).";
VAL_ 989 CP_inletHeaterState 0 "DISABLED" 1 "ENABLED_HIGHTEMP" 2 "ENABLED_LOWTEMP" 3 "FAULTED" ;
VAL_ 989 CP_inlet2HarnessIdState 0 "UNKNOWN_SNA" 1 "INVALID" 2 "VALID" ;
VAL_ 989 CP_inlet1HarnessIdState 0 "UNKNOWN_SNA" 1 "INVALID" 2 "VALID" ;
VAL_ 989 CP_loggingSlowSelect 0 "0" 1 "1" 2 "2" 3 "3" 4 "4" 5 "5" ;
CM_ BO_ 1014 "ESP32-DualCAN Model3_VEH. Seen on this car: 8-byte frames; fit good (bits covered 100%, mux 100%, ranges 100%).";
VAL_ 1014 VCFRONT_parkRightStatus 0 "OFF" 1 "ON" 2 "FAULT" 3 "SNA" ;
VAL_ 1014 VCFRONT_parkLeftStatus 0 "OFF" 1 "ON" 2 "FAULT" 3 "SNA" ;
VAL_ 1014 VCFRONT_turnSignalRightStatus 0 "OFF" 1 "ON" 2 "FAULT" 3 "SNA" ;
VAL_ 1014 VCFRONT_turnSignalLeftStatus 0 "OFF" 1 "ON" 2 "FAULT" 3 "SNA" ;
VAL_ 1014 VCFRONT_sideRepeaterRightStatus 0 "OFF" 1 "ON" 2 "FAULT" 3 "SNA" ;
VAL_ 1014 VCFRONT_sideRepeaterLeftStatus 0 "OFF" 1 "ON" 2 "FAULT" 3 "SNA" ;
VAL_ 1014 VCFRONT_sideMarkersStatus 0 "OFF" 1 "ON" 2 "FAULT" 3 "SNA" ;
VAL_ 1014 VCFRONT_fogRightStatus 0 "OFF" 1 "ON" 2 "FAULT" 3 "SNA" ;
VAL_ 1014 VCFRONT_fogLeftStatus 0 "OFF" 1 "ON" 2 "FAULT" 3 "SNA" ;
VAL_ 1014 VCFRONT_DRLRightStatus 0 "OFF" 1 "ON" 2 "FAULT" 3 "SNA" ;
VAL_ 1014 VCFRONT_DRLLeftStatus 0 "OFF" 1 "ON" 2 "FAULT" 3 "SNA" ;
VAL_ 1014 VCFRONT_highBeamRightStatus 0 "OFF" 1 "ON" 2 "FAULT" 3 "SNA" ;
VAL_ 1014 VCFRONT_highBeamLeftStatus 0 "OFF" 1 "ON" 2 "FAULT" 3 "SNA" ;
VAL_ 1014 VCFRONT_lowBeamRightStatus 0 "OFF" 1 "ON" 2 "FAULT" 3 "SNA" ;
VAL_ 1014 VCFRONT_lowBeamLeftStatus 0 "OFF" 1 "ON" 2 "FAULT" 3 "SNA" ;
CM_ BO_ 1024 "ESP32-DualCAN Model3_VEH. Seen on this car: 7-byte frames; fit ok (bits covered 100%, mux 100%, ranges 100%).";
CM_ BO_ 1031 "ESP32-DualCAN Model3_VEH. Seen on this car: 8-byte frames; fit good (bits covered 100%, mux 100%, ranges 100%, checksum 100%).";
VAL_ 1031 DAS_frunkRequest 0 "NONE" 1 "MOVE" 2 "STOP" 3 "SNA" ;
VAL_ 1031 DAS_windowRequest 0 "IDLE" 1 "GOTO_PERCENT" 2 "GOTO_VENT" 3 "GOTO_CLOSED" 4 "GOTO_OPEN" ;
VAL_ 1031 DAS_trunkRequest 0 "NONE" 1 "MOVE" 2 "STOP" 3 "SNA" ;
CM_ BO_ 1033 "ESP32-DualCAN Model3_VEH. Seen on this car: 1-byte frames; fit ok (bits covered 100%, mux 100%, ranges 100%).";
VAL_ 1033 DAS_nmKeepAwakeReason 0 "NONE_SNA" 1 "CTRS_CLOSED" 2 "CRITICAL_ALERT" 3 "FC_CTR_CLEANING" 4 "HVP_ACTIVE" 5 "BMS_ACTIVE" 6 "CP_ACTIVE" ;
VAL_ 1033 DAS_nmWakeUpReason 0 "NONE" 1 "CAN_VEH" 2 "CAN_HVS" 3 "WANTTOCHARGE" 4 "CRITICALALERT" 5 "WANTTOWARM" ;
CM_ BO_ 1044 "ESP32-DualCAN Model3_VEH. Seen on this car: 8-byte frames; fit ok (bits covered 100%, mux 100%, ranges 100%).";
CM_ BO_ 1049 "ESP32-DualCAN Model3_VEH. Seen on this car: 1-byte frames; fit ok (bits covered 100%, mux 100%, ranges 100%).";
VAL_ 1049 APS_nmKeepAwakeReason 0 "NONE_SNA" 1 "CTRS_CLOSED" 2 "CRITICAL_ALERT" 3 "FC_CTR_CLEANING" 4 "HVP_ACTIVE" 5 "BMS_ACTIVE" 6 "CP_ACTIVE" ;
VAL_ 1049 APS_nmWakeUpReason 0 "NONE" 1 "CAN_VEH" 2 "CAN_HVS" 3 "WANTTOCHARGE" 4 "CRITICALALERT" 5 "WANTTOWARM" ;
CM_ BO_ 1053 "ESP32-DualCAN Model3_VEH. Seen on this car: 2-byte frames; fit ok (bits covered 100%, mux 100%, ranges 100%).";
VAL_ 1053 CP_nmKeepAwakeReason 0 "NONE_SNA" 1 "CTRS_CLOSED" 2 "CRITICAL_ALERT" 3 "FC_CTR_CLEANING" 4 "HVP_ACTIVE" 5 "BMS_ACTIVE" 6 "CP_ACTIVE" ;
VAL_ 1053 CP_nmWakeUpReason 0 "NONE" 1 "CAN_VEH" 2 "CAN_HVS" 3 "WANTTOCHARGE" 4 "CRITICALALERT" 5 "WANTTOWARM" ;
CM_ BO_ 1056 "ESP32-DualCAN Model3_VEH. Seen on this car: 8-byte frames; fit good (bits covered 100%, mux 100%, ranges 100%).";
VAL_ 1056 APS_B_faultState 0 "NONE" 1 "GIC" 2 "MIF_ECC_CORRECTED" 3 "MIF_ECC_UNCORRECTED" 4 "MIF0_DFI_ALERT" 5 "MIF1_DFI_ALERT" 6 "MIF2_DFI_ALERT" 7 "MIF3_DFI_ALERT" 8 "MIF4_DFI_ALERT" 9 "MIF5_DFI_ALERT" 10 "MIF6_DFI_ALERT" 11 "MIF7_DFI_ALERT" 12 "MIF_ECC_AP" 13 "DROOP_CPUCL0" 14 "DROOP_CPUCL1" 15 "DROOP_CPUCL2" 16 "DROOP_GPU" 17 "DROOP_TRIP" 18 "CPU_FAULT" 19 "WDT" 20 "TRIP0_FAULT" 21 "TRIP1_FAULT" 22 "SOFTWARE_FAULT" 23 "SCS" 24 "UNEXPECTED" 25 "MIA" 26 "UNKNOWN" 27 "COUNT" ;
VAL_ 1056 APS_B_resetState 0 "NOT_RESETTING" 1 "RESETTING" 2 "FAULT" 3 "MIA" 4 "UNKNOWN" 5 "COUNT" ;
VAL_ 1056 APS_B_sleepState 0 "IDLE" 1 "WAIT_FOR_BUS_SILENCE" 2 "READY" 3 "GOING_TO_SLEEP" 4 "SLEEPING" 5 "ABORT" 6 "FAULT" 7 "MIA" 8 "UNKNOWN" 9 "COUNT" ;
VAL_ 1056 APS_B_powerState 0 "IDLE" 1 "AP_ON_PREPARE" 2 "AP_ON_PREPARE_WAIT_FOR_ACK" 3 "AP_ON_PREPARE_WAIT_FOR_RESPONSE" 4 "AP_ON_READY" 5 "AP_ON_READY_WAIT_FOR_ACK" 6 "AP_ON_READY_WAIT_FOR_RESPONSE" 7 "AP_BOOTING" 8 "AP_IN_COREBOOT" 9 "AP_ON" 10 "AP_WAIT_FOR_SHUTDOWN" 11 "AP_OFF_PREPARE" 12 "AP_OFF_READY" 13 "AP_OFF_READY_WAIT_FOR_ACK" 14 "AP_OFF_READY_WAIT_FOR_RESPONSE" 15 "AP_OFF_ABORT" 16 "AP_OFF_ABORT_WAIT_FOR_ACK" 17 "AP_SUSPENDED" 18 "SOC_OFF_READY" 19 "SOC_OFF" 20 "SOC_OFF_ABORT" 21 "FAULT" 22 "MIA" 23 "UNKNOWN" 24 "COUNT" ;
VAL_ 1056 APS_B_arbState 0 "INIT" 1 "IDLE" 2 "PRIMARY" 3 "SECONDARY" 4 "FAULT" 5 "MIA" 6 "UNKNOWN" 7 "COUNT" ;
VAL_ 1056 APS_secondaryTurbo 0 "A" 1 "B" 2 "UNKNOWN" ;
VAL_ 1056 APS_A_faultState 0 "NONE" 1 "GIC" 2 "MIF_ECC_CORRECTED" 3 "MIF_ECC_UNCORRECTED" 4 "MIF0_DFI_ALERT" 5 "MIF1_DFI_ALERT" 6 "MIF2_DFI_ALERT" 7 "MIF3_DFI_ALERT" 8 "MIF4_DFI_ALERT" 9 "MIF5_DFI_ALERT" 10 "MIF6_DFI_ALERT" 11 "MIF7_DFI_ALERT" 12 "MIF_ECC_AP" 13 "DROOP_CPUCL0" 14 "DROOP_CPUCL1" 15 "DROOP_CPUCL2" 16 "DROOP_GPU" 17 "DROOP_TRIP" 18 "CPU_FAULT" 19 "WDT" 20 "TRIP0_FAULT" 21 "TRIP1_FAULT" 22 "SOFTWARE_FAULT" 23 "SCS" 24 "UNEXPECTED" 25 "MIA" 26 "UNKNOWN" 27 "COUNT" ;
VAL_ 1056 APS_A_resetState 0 "NOT_RESETTING" 1 "RESETTING" 2 "FAULT" 3 "MIA" 4 "UNKNOWN" 5 "COUNT" ;
VAL_ 1056 APS_A_sleepState 0 "IDLE" 1 "WAIT_FOR_BUS_SILENCE" 2 "READY" 3 "GOING_TO_SLEEP" 4 "SLEEPING" 5 "ABORT" 6 "FAULT" 7 "MIA" 8 "UNKNOWN" 9 "COUNT" ;
VAL_ 1056 APS_A_powerState 0 "IDLE" 1 "AP_ON_PREPARE" 2 "AP_ON_PREPARE_WAIT_FOR_ACK" 3 "AP_ON_PREPARE_WAIT_FOR_RESPONSE" 4 "AP_ON_READY" 5 "AP_ON_READY_WAIT_FOR_ACK" 6 "AP_ON_READY_WAIT_FOR_RESPONSE" 7 "AP_BOOTING" 8 "AP_IN_COREBOOT" 9 "AP_ON" 10 "AP_WAIT_FOR_SHUTDOWN" 11 "AP_OFF_PREPARE" 12 "AP_OFF_READY" 13 "AP_OFF_READY_WAIT_FOR_ACK" 14 "AP_OFF_READY_WAIT_FOR_RESPONSE" 15 "AP_OFF_ABORT" 16 "AP_OFF_ABORT_WAIT_FOR_ACK" 17 "AP_SUSPENDED" 18 "SOC_OFF_READY" 19 "SOC_OFF" 20 "SOC_OFF_ABORT" 21 "FAULT" 22 "MIA" 23 "UNKNOWN" 24 "COUNT" ;
VAL_ 1056 APS_A_arbState 0 "INIT" 1 "IDLE" 2 "PRIMARY" 3 "SECONDARY" 4 "FAULT" 5 "MIA" 6 "UNKNOWN" 7 "COUNT" ;
VAL_ 1056 APS_primaryTurbo 0 "A" 1 "B" 2 "UNKNOWN" ;
CM_ BO_ 1057 "ESP32-DualCAN Model3_VEH. Seen on this car: 7-byte frames; fit ok (bits covered 100%, mux 100%, ranges 100%).";
VAL_ 1057 VCFRONT_nmWakeUpReason 0 "NONE" 1 "CAN_VEH" 2 "CAN_HVS" 3 "WANTTOCHARGE" 4 "CRITICALALERT" 5 "WANTTOWARM" ;
VAL_ 1057 VCFRONT_nmKeepAwakeReason 0 "NONE_SNA" 1 "CTRS_CLOSED" 2 "CRITICAL_ALERT" 3 "FC_CTR_CLEANING" 4 "HVP_ACTIVE" 5 "BMS_ACTIVE" 6 "CP_ACTIVE" ;
CM_ BO_ 1058 "ESP32-DualCAN Model3_VEH. Seen on this car: 6-byte frames; fit ok (bits covered 100%, mux 100%, ranges 100%).";
VAL_ 1058 VCLEFT_nmDebugWakeUp 2147483648 "31" 1073741824 "30" 536870912 "29" 268435456 "28" 134217728 "27" 67108864 "26" 33554432 "25" 16777216 "24" 0 "NONE" 256 "8" 512 "9" 1024 "10" 2048 "11" 4096 "12" 8192 "13" 16384 "14" 32768 "15" 1 "0" 65536 "16" 2 "1" 131072 "17" 4 "2" 262144 "18" 8 "3" 524288 "19" 16 "4" 1048576 "20" 32 "5" 2097152 "21" 64 "6" 4194304 "22" 128 "7" 8388608 "23" ;
VAL_ 1058 VCLEFT_nmWakeUpReason 0 "NONE" 1 "CAN_VEH" 2 "CAN_HVS" 3 "WANTTOCHARGE" 4 "CRITICALALERT" 5 "WANTTOWARM" ;
VAL_ 1058 VCLEFT_nmKeepAwakeReason 0 "NONE_SNA" 1 "CTRS_CLOSED" 2 "CRITICAL_ALERT" 3 "FC_CTR_CLEANING" 4 "HVP_ACTIVE" 5 "BMS_ACTIVE" 6 "CP_ACTIVE" ;
CM_ BO_ 1059 "ESP32-DualCAN Model3_VEH. Seen on this car: 7-byte frames; fit ok (bits covered 100%, mux 100%, ranges 100%).";
VAL_ 1059 VCRIGHT_nmDebugWakeUp 0 "NONE" 1 "0" 2 "1" 4 "2" 8 "3" 16 "4" 32 "5" 64 "6" 128 "7" 256 "8" 512 "9" 1024 "10" 2048 "11" 4096 "12" 8192 "13" 16384 "14" 32768 "15" 65536 "16" 131072 "17" 262144 "18" 524288 "19" 1048576 "20" 2097152 "21" 4194304 "22" 8388608 "23" 16777216 "24" 33554432 "25" 67108864 "26" 134217728 "27" 268435456 "28" 536870912 "29" 1073741824 "30" 2147483648 "31" ;
VAL_ 1059 VCRIGHT_nmWakeUpReason 0 "NONE" 1 "ECU_SPECIFIC" 2 "SWITCH_INPUT" 3 "RESET" 4 "DOOR_LATCH" 5 "INTERIOR_HANDLE" 6 "EXTERIOR_HANDLE" 7 "LIN_RX" 8 "TRUNK_SWITCH" 9 "TRUNK_LATCH" 10 "CABIN_HOT" 11 "POWER_ON_RESET" 15 "UNKNOWN" ;
VAL_ 1059 VCRIGHT_nmKeepAwakeReason 0 "NONE_SNA" 1 "EPB_STATE_NOT_SAVED" 2 "EPB_NOT_SECURE" 3 "HVAC_CABIN_PURGE" 4 "HVAC_PRECONDITIONING" 5 "CLOSURE_LATCH" 6 "EPB_SUMMON_ACTIVE" 7 "HANDLE" 8 "SEAT" 9 "TRUNK_LIGHT" 10 "UDS_ACTIVE" 11 "HVAC_EVAP_DRYING" 12 "TRUNK_SWITCH" 14 "OTHER" 15 "MULTIPLE" ;
CM_ BO_ 1070 "ESP32-DualCAN Model3_VEH. Seen on this car: 8-byte frames; fit weak (bits covered 0%, mux 100%, ranges 100%).";
CM_ BO_ 1071 "ESP32-DualCAN Model3_VEH. Seen on this car: 7-byte frames; fit ok (bits covered 96%, mux 100%, ranges 100%).";
CM_ BO_ 1083 "ESP32-DualCAN Model3_VEH. Seen on this car: 8-byte frames; fit good (bits covered 100%, mux 100%, ranges 100%).";
CM_ BO_ 1089 "ESP32-DualCAN Model3_VEH. Seen on this car: 8-byte frames; fit ok (bits covered 100%, mux 100%, ranges 100%, checksum 0%).";
VAL_ 1089 VC_pcsInterfaceMuxIndex 0 "0" 1 "1" ;
CM_ BO_ 1091 "ESP32-DualCAN Model3_VEH. Seen on this car: 6-byte frames; fit weak (bits covered 100%, mux 100%, ranges 100%, checksum 0%).";
CM_ BO_ 1106 "ESP32-DualCAN Model3_VEH. Seen on this car: 3-byte frames; fit ok (bits covered 100%, mux 100%, ranges 100%).";
CM_ BO_ 1107 "ESP32-DualCAN Model3_VEH. Seen on this car: 4-byte frames; fit ok (bits covered 100%, mux 100%, ranges 100%).";
CM_ BO_ 1114 "ESP32-DualCAN Model3_VEH. Seen on this car: 8-byte frames; fit good (bits covered 100%, mux 100%, ranges 100%).";
VAL_ 1114 VCRIGHT_AP_tempDuctDefrost 255 "SNA" ;
VAL_ 1114 VCRIGHT_AP_hvacAirDistributionMode 0 "NONE" 1 "FLOOR" 2 "PANEL" 3 "PANEL_FLOOR" 4 "DEFROST" 5 "DEFROST_FLOOR" 6 "DEFROST_PANEL" 7 "DEFROST_PANEL_FLOOR" ;
VAL_ 1114 VCRIGHT_AP_cabinTempSideGlassLeft 255 "SNA" ;
VAL_ 1114 VCRIGHT_AP_cabinTempSideGlassRight 255 "SNA" ;
VAL_ 1114 VCRIGHT_AP_cabinTempWindshield 255 "SNA" ;
VAL_ 1114 VCRIGHT_AP_hvacModelInitStatus 0 "NOT_INIT_WAIT_FOR_SENSORS" 1 "NOT_INIT_WAIT_FOR_GTW" 2 "INIT_FROM_SENSORS" 3 "INIT_FROM_SENSORS_PREDICTION_ERROR" 4 "INIT_FORWARD_CALC" 5 "INIT_WAITING_FOR_SENSORS" ;
CM_ BO_ 1115 "ESP32-DualCAN Model3_VEH. Seen on this car: 2-byte frames; fit poor (bits covered 0%, mux 100%, ranges 100%).";
CM_ BO_ 1138 "ESP32-DualCAN Model3_VEH. Seen on this car: 8-byte frames; fit good (bits covered 100%, mux 100%, ranges 100%).";
CM_ BO_ 1154 "ESP32-DualCAN Model3_VEH. Seen on this car: 8-byte frames; fit ok (bits covered 100%, mux 100%, ranges 100%).";
CM_ BO_ 1170 "ESP32-DualCAN Model3_VEH. Seen on this car: 7-byte frames; fit ok (bits covered 100%, mux 100%, ranges 100%).";
CM_ BO_ 1181 "ESP32-DualCAN Model3_VEH. Seen on this car: 7-byte frames; fit ok (bits covered 100%, mux 100%, ranges 100%).";
CM_ BO_ 1267 "ESP32-DualCAN Model3_VEH. Seen on this car: 4-byte frames; fit poor (bits covered 0%, mux 100%, ranges 100%).";
CM_ BO_ 1279 "ESP32-DualCAN Model3_VEH. Seen on this car: 8-byte frames; fit weak (bits covered 0%, mux 100%, ranges 100%).";
CM_ BO_ 1289 "ESP32-DualCAN Model3_VEH. Seen on this car: 5-byte frames; fit poor (bits covered 0%, mux 100%, ranges 100%).";
CM_ BO_ 1304 "ESP32-DualCAN Model3_VEH. Seen on this car: 2-byte frames; fit weak (bits covered 60%, mux 100%, ranges 100%).";
CM_ BO_ 1314 "ESP32-DualCAN Model3_VEH. Seen on this car: 2-byte frames; fit weak (bits covered 67%, mux 100%, ranges 100%).";
CM_ BO_ 1321 "ESP32-DualCAN Model3_VEH. Seen on this car: 8-byte frames; fit weak (bits covered 0%, mux 100%, ranges 100%).";
CM_ BO_ 1327 "ESP32-DualCAN Model3_VEH. Seen on this car: 8-byte frames; fit ok (bits covered 100%, mux 100%, ranges 100%).";
CM_ BO_ 1349 "ESP32-DualCAN Model3_VEH. Seen on this car: 8-byte frames; fit good (bits covered 100%, mux 100%, ranges 100%, checksum 100%).";
VAL_ 1349 VCFRONT_vehicleLoadShedStage 0 "IDLE_OR_UNDEFINED" 1 "1" 2 "2" 3 "3" ;
VAL_ 1349 VCFRONT_DCDCSaturationLoadShedStage 0 "IDLE" 255 "MAX" ;
VAL_ 1349 VCFRONT_VCRightEFuseLoadShedStage 0 "IDLE" 255 "MAX" ;
VAL_ 1349 VCFRONT_loadShedReason 0 "NONE" 1 "DCDC_EFUSE_PROTECTION" 2 "LVBRIDGE_EFUSE_PROTECTION" 4 "DCDC_SATURATION" 8 "POST_CRASH" 16 "HV_FAULT" ;
VAL_ 1349 VCFRONT_systemStatusMuxIndex 0 "SYSTEM_DATA" 1 "ACTIVE_LOAD_SHED_REASONS" 2 "LOAD_SHED_STATUSES_AND_COMMANDS" ;
CM_ BO_ 1362 "ESP32-DualCAN Model3_VEH. Seen on this car: 8-byte frames; fit good (bits covered 100%, mux 100%, ranges 100%, checksum 100%).";
VAL_ 1362 VCLEFT_loadShedReason 0 "NONE" 1 "DCDC_EFUSE_PROTECTION" 2 "LVBRIDGE_EFUSE_PROTECTION" 4 "DCDC_SATURATION" 8 "POST_CRASH" 16 "HV_FAULT" ;
CM_ BO_ 1363 "ESP32-DualCAN Model3_VEH. Seen on this car: 8-byte frames; fit good (bits covered 100%, mux 100%, ranges 100%, checksum 100%).";
VAL_ 1363 VCRIGHT_loadShedReason 0 "NONE" 1 "DCDC_EFUSE_PROTECTION" 2 "LVBRIDGE_EFUSE_PROTECTION" 4 "DCDC_SATURATION" 8 "POST_CRASH" 16 "HV_FAULT" ;
CM_ BO_ 1364 "ESP32-DualCAN Model3_VEH. Seen on this car: 7-byte frames; fit poor (bits covered 0%, mux 100%, ranges 100%).";
CM_ BO_ 1524 "ESP32-DualCAN Model3_VEH. Seen on this car: 8-byte frames; fit poor (bits covered 0%, mux 100%, ranges 100%).";
CM_ BO_ 1536 "ESP32-DualCAN Model3_VEH. Seen on this car: 8-byte frames; fit ok (bits covered 100%, mux 100%, ranges 100%).";
CM_ BO_ 1537 "ESP32-DualCAN Model3_VEH. Seen on this car: 8-byte frames; fit ok (bits covered 100%, mux 100%, ranges 100%).";
CM_ BO_ 1541 "ESP32-DualCAN Model3_VEH. Seen on this car: 8-byte frames; fit poor (bits covered 0%, mux 100%, ranges 100%).";
CM_ BO_ 1542 "ESP32-DualCAN Model3_VEH. Seen on this car: 8-byte frames; fit ok (bits covered 100%, mux 100%, ranges 100%).";
CM_ BO_ 1544 "ESP32-DualCAN Model3_VEH. Seen on this car: 8-byte frames; fit ok (bits covered 100%, mux 100%, ranges 100%).";
CM_ BO_ 1545 "ESP32-DualCAN Model3_VEH. Seen on this car: 8-byte frames; fit ok (bits covered 100%, mux 100%, ranges 100%).";
CM_ BO_ 1546 "ESP32-DualCAN Model3_VEH. Seen on this car: 8-byte frames; fit ok (bits covered 100%, mux 100%, ranges 100%).";
CM_ BO_ 1547 "ESP32-DualCAN Model3_VEH. Seen on this car: 8-byte frames; fit ok (bits covered 100%, mux 100%, ranges 100%).";
CM_ BO_ 1550 "ESP32-DualCAN Model3_VEH. Seen on this car: 8-byte frames; fit ok (bits covered 100%, mux 100%, ranges 100%).";
CM_ BO_ 1558 "ESP32-DualCAN Model3_VEH. Seen on this car: 8-byte frames; fit ok (bits covered 100%, mux 100%, ranges 100%).";
CM_ BO_ 1565 "ESP32-DualCAN Model3_VEH. Seen on this car: 8-byte frames; fit ok (bits covered 82%, mux 100%, ranges 100%).";
CM_ BO_ 1566 "ESP32-DualCAN Model3_VEH. Seen on this car: 8-byte frames; fit ok (bits covered 100%, mux 100%, ranges 100%).";
CM_ BO_ 1570 "ESP32-DualCAN Model3_VEH. Seen on this car: 8-byte frames; fit ok (bits covered 100%, mux 100%, ranges 100%).";
CM_ BO_ 1571 "ESP32-DualCAN Model3_VEH. Seen on this car: 8-byte frames; fit ok (bits covered 100%, mux 100%, ranges 100%).";
CM_ BO_ 1572 "ESP32-DualCAN Model3_VEH. Seen on this car: 8-byte frames; fit ok (bits covered 100%, mux 100%, ranges 100%).";
CM_ BO_ 1573 "ESP32-DualCAN Model3_VEH. Seen on this car: 8-byte frames; fit ok (bits covered 100%, mux 100%, ranges 100%).";
CM_ BO_ 1574 "ESP32-DualCAN Model3_VEH. Seen on this car: 8-byte frames; fit ok (bits covered 100%, mux 100%, ranges 100%).";
CM_ BO_ 1575 "ESP32-DualCAN Model3_VEH. Seen on this car: 8-byte frames; fit ok (bits covered 100%, mux 100%, ranges 100%).";
CM_ BO_ 1576 "ESP32-DualCAN Model3_VEH. Seen on this car: 8-byte frames; fit poor (bits covered 0%, mux 100%, ranges 100%).";
CM_ BO_ 1577 "ESP32-DualCAN Model3_VEH. Seen on this car: 8-byte frames; fit poor (bits covered 0%, mux 100%, ranges 100%).";
CM_ BO_ 1588 "ESP32-DualCAN Model3_VEH. Seen on this car: 8-byte frames; fit poor (bits covered 0%, mux 100%, ranges 100%).";
CM_ BO_ 1617 "ESP32-DualCAN Model3_VEH. Seen on this car: 8-byte frames; fit ok (bits covered 100%, mux 100%, ranges 100%).";
CM_ BO_ 1638 "ESP32-DualCAN Model3_VEH. Seen on this car: 4-byte frames; fit ok (bits covered 100%, mux 100%, ranges 100%).";
VAL_ 1638 GTW_diagLevel 0 "FACTORY" 10 "DIAG_LINK_ACTIVE" 25 "SERVICE" 50 "SERVICE_DRIVE" 80 "PARK" 100 "NORMAL_OPERATION" ;
CM_ BO_ 1651 "ESP32-DualCAN Model3_VEH. Seen on this car: 8-byte frames; fit good (bits covered 100%, mux 100%, ranges 100%).";
CM_ BO_ 1655 "ESP32-DualCAN Model3_VEH. Seen on this car: 8-byte frames; fit good (bits covered 100%, mux 100%, ranges 100%).";
VAL_ 1655 VC_LVBMS_MOSTemperature 4095 "SNA" ;
VAL_ 1655 VC_LVBMS_maxAllowedDischargeCurrent 8191 "SNA" ;
VAL_ 1655 VC_LVBMS_packTemperature 511 "SNA" ;
VAL_ 1655 VC_LVBMS_maxAllowedChargeCurrent 8191 "SNA" ;
VAL_ 1655 VC_LVBMS_packVoltage 65535 "SNA" ;
VAL_ 1655 VC_LVBMS_currentTarget 32767 "SNA" ;
VAL_ 1655 VC_LVBMS_chargeType 0 "UNDEFINED" 1 "CONSTANT_CURRENT" 2 "CONSTANT_VOLTAGE" 3 "COMPLETE" 4 "SNA" ;
VAL_ 1655 VC_LVBMS_LINWakeDisabled 0 "ENABLED" 1 "DISABLED" ;
VAL_ 1655 VC_LVBMS_VehicleState 0 "DRIVE" 1 "ACCESSORY" 2 "CONDITIONING" 3 "OFF" ;
VAL_ 1655 VC_LVBMS_MOSState 0 "OPEN" 1 "CLOSED" 2 "INVALID" 3 "SNA" ;
VAL_ 1655 VC_LVBMS_ECPAState 0 "OPEN" 1 "CLOSED" 2 "INVALID" 3 "SNA" ;
VAL_ 1655 VC_LVBMS_sumCellVoltage 65534 "INVALID" 65535 "SNA" ;
VAL_ 1655 VC_LVBMS_packCurrent 4194303 "SNA" ;
VAL_ 1655 VC_LVBMS_voltageTarget 32767 "SNA" ;
VAL_ 1655 VC_lvbmsStatusHighIndex 0 "PACK_VITALS_1" 1 "CELL_VITALS_1" 2 "CELL_VITALS_2" 3 "TARGETS" 4 "STATE_AND_COMMANDS" 5 "PCS_INTERFACE" 6 "INVALID" ;
CM_ BO_ 1662 "ESP32-DualCAN Model3_VEH. Seen on this car: 8-byte frames; fit good (bits covered 100%, mux 100%, ranges 100%).";
CM_ BO_ 1666 "ESP32-DualCAN Model3_VEH. Seen on this car: 8-byte frames; fit ok (bits covered 100%, mux 100%, ranges 100%, checksum 0%).";
VAL_ 1666 HVP_hvilStatus 0 "UNKNOWN" 1 "OK" 2 "FAULT" ;
CM_ BO_ 1698 "ESP32-DualCAN Model3_VEH. Seen on this car: 4-byte frames; fit poor (bits covered 0%, mux 100%, ranges 100%).; 1 signals past the 4 bytes this car sends were left out";
CM_ BO_ 1723 "ESP32-DualCAN Model3_VEH. Seen on this car: 8-byte frames; fit poor (bits covered 0%, mux 100%, ranges 100%).";
CM_ BO_ 1736 "ESP32-DualCAN Model3_VEH. Seen on this car: 8-byte frames; fit good (bits covered 100%, mux 100%, ranges 100%).";
CM_ BO_ 1768 "ESP32-DualCAN Model3_VEH. Seen on this car: 8-byte frames; fit good (bits covered 100%, mux 100%, ranges 100%).";
CM_ BO_ 1799 "ESP32-DualCAN Model3_VEH. Seen on this car: 8-byte frames; fit weak (bits covered 0%, mux 100%, ranges 100%).";
CM_ BO_ 1800 "ESP32-DualCAN Model3_VEH. Seen on this car: 5-byte frames; fit ok (bits covered 100%, mux 100%, ranges 100%).";
CM_ BO_ 1802 "ESP32-DualCAN Model3_VEH. Seen on this car: 5-byte frames; fit ok (bits covered 100%, mux 100%, ranges 100%).";
CM_ BO_ 1803 "ESP32-DualCAN Model3_VEH. Seen on this car: 8-byte frames; fit good (bits covered 100%, mux 90%, ranges 100%).";
VAL_ 1803 VCRIGHT_tempIncarCabinDeep 255 "SNA" ;
CM_ BO_ 1810 "ESP32-DualCAN Model3_VEH. Seen on this car: 8-byte frames; fit good (bits covered 100%, mux 100%, ranges 100%).";
CM_ BO_ 1815 "ESP32-DualCAN Model3_VEH. Seen on this car: 7-byte frames; fit ok (bits covered 100%, mux 100%, ranges 100%).";
CM_ BO_ 1816 "ESP32-DualCAN Model3_VEH. Seen on this car: 8-byte frames; fit good (bits covered 90%, mux 100%, ranges 100%).";
VAL_ 1816 VC_LVBMS_SOP 16777215 "SNA" ;
VAL_ 1816 VC_LVBMS_MaxSleepCurrent 65535 "SNA" ;
VAL_ 1816 VC_LVBMS_MinSleepCurrent 65535 "SNA" ;
VAL_ 1816 VC_LVBMS_dynamicSOCCorrection 0 "INACTIVE" 1 "ACTIVE" ;
VAL_ 1816 VC_LVBMS_staticSOCCorrection 0 "INACTIVE" 1 "ACTIVE" ;
VAL_ 1816 VC_LVBMS_minCellSOC 127 "SNA" ;
VAL_ 1816 VC_LVBMS_SOH 127 "SNA" ;
VAL_ 1816 VC_LVBMS_TimeSlept 16777215 "SNA" ;
VAL_ 1816 VC_LVBMS_maxCellSOC 127 "SNA" ;
VAL_ 1816 VC_LVBMS_SOE 127 "SNA" ;
VAL_ 1816 VC_LVBMS_AvgSleepCurrent 65535 "SNA" ;
VAL_ 1816 VC_LVBMS_SOC 127 "SNA" ;
VAL_ 1816 VC_LVBMS_sumCellVoltageFiltered 65534 "INVALID" 65535 "SNA" ;
VAL_ 1816 VC_lvbmsStatusLowIndex 0 "STATE" 1 "THROUGHPUT_1" 2 "THROUGHPUT_2" 3 "THROUGHPUT_3" 4 "PACK_VITALS_2" 5 "FAULT_STATS" 6 "CELL_VITALS_3" 7 "CELL_VITALS_4" 8 "INVALID" ;
CM_ BO_ 1824 "ESP32-DualCAN Model3_VEH. Seen on this car: 5-byte frames; fit poor (bits covered 0%, mux 100%, ranges 100%).";
CM_ BO_ 1828 "ESP32-DualCAN Model3_VEH. Seen on this car: 3-byte frames; fit ok (bits covered 100%, mux 100%, ranges 100%).";
VAL_ 1828 VCFRONT_loadShedStsBatteryPump_duty 127 "SNA" ;
VAL_ 1828 VCFRONT_loadShedStsCondenserFan_duty 127 "SNA" ;
VAL_ 1828 VCFRONT_loadShedStsPTPump_duty 127 "SNA" ;
CM_ BO_ 1830 "ESP32-DualCAN Model3_VEH. Seen on this car: 3-byte frames; fit ok (bits covered 100%, mux 100%, ranges 100%).";
VAL_ 1830 VCLEFT_loadShedStsHVACBlower_duty 127 "SNA" ;
CM_ BO_ 1831 "ESP32-DualCAN Model3_VEH. Seen on this car: 2-byte frames; fit ok (bits covered 100%, mux 100%, ranges 100%).";
CM_ BO_ 1834 "ESP32-DualCAN Model3_VEH. Seen on this car: 8-byte frames; fit good (bits covered 100%, mux 100%, ranges 100%).";
CM_ BO_ 1847 "ESP32-DualCAN Model3_VEH. Seen on this car: 7-byte frames; fit ok (bits covered 100%, mux 100%, ranges 100%).";
VAL_ 1847 VCFRONT_LVBMS_FWBuildType 0 "UNKNOWN_BUILD" 1 "PLATFORM_BUILD" 2 "LOCAL_BUILD" 3 "TRACEABLE_CI_BUILD" 4 "MFG_BUILD" ;
VAL_ 1847 VCFRONT_LVBMS_InfoIndex 0 "PCBAID_ASSYID" 1 "APP_USAGEID_CRC" 2 "GITHASH" 3 "BUILDTYPE" 4 "SERIAL_NUMBER" 5 "INVALID" ;
CM_ BO_ 1849 "ESP32-DualCAN Model3_VEH. Seen on this car: 5-byte frames; fit ok (bits covered 100%, mux 100%, ranges 100%).";
CM_ BO_ 1850 "ESP32-DualCAN Model3_VEH. Seen on this car: 8-byte frames; fit good (bits covered 100%, mux 100%, ranges 100%).";
CM_ BO_ 1858 "ESP32-DualCAN Model3_VEH. Seen on this car: 8-byte frames; fit weak (bits covered 0%, mux 100%, ranges 100%).";
VAL_ 1858 VCBATT1_LVBMS_MOSTemperature 4095 "SNA" ;
VAL_ 1858 VCBATT1_LVBMS_maxAllowedDischargeCurrent 8191 "SNA" ;
VAL_ 1858 VCBATT1_LVBMS_packTemperature 511 "SNA" ;
VAL_ 1858 VCBATT1_LVBMS_maxAllowedChargeCurrent 8191 "SNA" ;
VAL_ 1858 VCBATT1_LVBMS_packVoltage 65535 "SNA" ;
VAL_ 1858 VCBATT1_LVBMS_currentTarget 32767 "SNA" ;
VAL_ 1858 VCBATT1_LVBMS_chargeType 0 "UNDEFINED" 1 "CONSTANT_CURRENT" 2 "CONSTANT_VOLTAGE" 3 "COMPLETE" 4 "SNA" ;
VAL_ 1858 VCBATT1_LVBMS_LINWakeDisabled 0 "ENABLED" 1 "DISABLED" ;
VAL_ 1858 VCBATT1_LVBMS_VehicleState 0 "DRIVE" 1 "ACCESSORY" 2 "CONDITIONING" 3 "OFF" ;
VAL_ 1858 VCBATT1_LVBMS_MOSState 0 "OPEN" 1 "CLOSED" 2 "INVALID" 3 "SNA" ;
VAL_ 1858 VCBATT1_LVBMS_ECPAState 0 "OPEN" 1 "CLOSED" 2 "INVALID" 3 "SNA" ;
VAL_ 1858 VCBATT1_LVBMS_sumCellVoltage 65534 "INVALID" 65535 "SNA" ;
VAL_ 1858 VCBATT1_LVBMS_packCurrent 4294934528 "SNA" ;
VAL_ 1858 VCBATT1_LVBMS_voltageTarget 32767 "SNA" ;
VAL_ 1858 VCBATT1_lvbmsStatusHighIndex 0 "PACK_VITALS_1" 1 "CELL_VITALS_1" 2 "CELL_VITALS_2" 3 "TARGETS" 4 "STATE_AND_COMMANDS" 5 "PCS_INTERFACE" 6 "INVALID" ;
CM_ BO_ 1864 "ESP32-DualCAN Model3_VEH. Seen on this car: 5-byte frames; fit ok (bits covered 100%, mux 100%, ranges 100%).";
CM_ BO_ 1870 "ESP32-DualCAN Model3_VEH. Seen on this car: 8-byte frames; fit poor (bits covered 0%, mux 100%, ranges 100%).";
CM_ BO_ 1871 "ESP32-DualCAN Model3_VEH. Seen on this car: 8-byte frames; fit poor (bits covered 0%, mux 100%, ranges 100%).";
CM_ BO_ 1897 "ESP32-DualCAN Model3_VEH. Seen on this car: 8-byte frames; fit weak (bits covered 0%, mux 100%, ranges 100%).";
CM_ BO_ 1914 "ESP32-DualCAN Model3_VEH. Seen on this car: 8-byte frames; fit good (bits covered 100%, mux 100%, ranges 100%).";
CM_ BO_ 1917 "ESP32-DualCAN Model3_VEH. Seen on this car: 4-byte frames; fit ok (bits covered 100%, mux 100%, ranges 100%).";
CM_ BO_ 1928 "ESP32-DualCAN Model3_VEH. Seen on this car: 8-byte frames; fit good (bits covered 100%, mux 100%, ranges 100%).";
VAL_ 1928 EPBL_esmCaliperRequest 0 "INVALID" 1 "NONE" 2 "APPLY" 3 "RELEASE" 4 "ENDSTOP" ;
VAL_ 1928 EPBL_pid_duty 127 "SNA" ;
CM_ BO_ 1929 "ESP32-DualCAN Model3_VEH. Seen on this car: 4-byte frames; fit weak (bits covered 100%, mux 100%, ranges 100%, checksum 0%).";
VAL_ 1929 EPBL_vehiclePowerStateDBG 0 "INIT" 1 "LOW_POWER_AWAKE" 2 "CONDITIONING" 3 "ACCESSORY" 4 "ACCESSORY_PLUS" 5 "DRIVE" 6 "OTA" 7 "WAIT_FOR_HIGH_POWER" 8 "TURN_ON_LV" 9 "SYSTEM_CHECKS" 10 "LV_ON" 11 "JUMP_START" 12 "LV_SHUTDOWN" 13 "GO_QUIET" 14 "SLEEP_SHUTDOWN" 15 "LOW_POWER_STANDBY" 16 "RESET" ;
VAL_ 1929 EPBL_lumbarLVState 0 "OFF" 1 "ON" 2 "GOING_DOWN" 3 "FAULT" ;
VAL_ 1929 EPBL_rcmLVState 0 "OFF" 1 "ON" 2 "GOING_DOWN" 3 "FAULT" ;
CM_ BO_ 1930 "ESP32-DualCAN Model3_VEH. Seen on this car: 8-byte frames; fit good (bits covered 100%, mux 100%, ranges 100%).";
CM_ BO_ 1943 "ESP32-DualCAN Model3_VEH. Seen on this car: 4-byte frames; fit weak (bits covered 100%, mux 100%, ranges 100%, checksum 0%).";
VAL_ 1943 EPBR_vehiclePowerStateDBG 0 "INIT" 1 "LOW_POWER_AWAKE" 2 "CONDITIONING" 3 "ACCESSORY" 4 "ACCESSORY_PLUS" 5 "DRIVE" 6 "OTA" 7 "WAIT_FOR_HIGH_POWER" 8 "TURN_ON_LV" 9 "SYSTEM_CHECKS" 10 "LV_ON" 11 "JUMP_START" 12 "LV_SHUTDOWN" 13 "GO_QUIET" 14 "SLEEP_SHUTDOWN" 15 "LOW_POWER_STANDBY" 16 "RESET" ;
VAL_ 1943 EPBR_ptcLVState 0 "OFF" 1 "ON" 2 "GOING_DOWN" 3 "FAULT" ;
VAL_ 1943 EPBR_premAudioLVState 0 "OFF" 1 "ON" 2 "GOING_DOWN" 3 "FAULT" ;
VAL_ 1943 EPBR_parkLVState 0 "OFF" 1 "ON" 2 "GOING_DOWN" 3 "FAULT" ;
VAL_ 1943 EPBR_tunerLVState 0 "OFF" 1 "ON" 2 "GOING_DOWN" 3 "FAULT" ;
VAL_ 1943 EPBR_rcmLVState 0 "OFF" 1 "ON" 2 "GOING_DOWN" 3 "FAULT" ;
CM_ BO_ 1944 "ESP32-DualCAN Model3_VEH. Seen on this car: 8-byte frames; fit ok (bits covered 100%, mux 86%, ranges 100%, checksum 0%).";
VAL_ 1944 EPBL_remoteADCIndex 0 "0" 1 "1" 2 "2" 3 "3" 4 "4" 5 "5" ;
CM_ BO_ 1949 "ESP32-DualCAN Model3_VEH. Seen on this car: 8-byte frames; fit good (bits covered 100%, mux 100%, ranges 100%).";
CM_ BO_ 1960 "ESP32-DualCAN Model3_VEH. Seen on this car: 8-byte frames; fit good (bits covered 100%, mux 100%, ranges 100%).";
VAL_ 1960 EPBR_esmCaliperRequest 0 "INVALID" 1 "NONE" 2 "APPLY" 3 "RELEASE" 4 "ENDSTOP" ;
VAL_ 1960 EPBR_pid_duty 127 "SNA" ;
CM_ BO_ 1973 "ESP32-DualCAN Model3_VEH. Seen on this car: 3-byte frames; fit ok (bits covered 100%, mux 100%, ranges 100%).";
CM_ BO_ 1976 "ESP32-DualCAN Model3_VEH. Seen on this car: 8-byte frames; fit ok (bits covered 100%, mux 86%, ranges 100%, checksum 0%).";
VAL_ 1976 EPBR_remoteADCIndex 0 "0" 1 "1" 2 "2" 3 "3" 4 "4" 5 "5" ;
CM_ BO_ 1981 "ESP32-DualCAN Model3_VEH. Seen on this car: 8-byte frames; fit good (bits covered 100%, mux 100%, ranges 100%).";
CM_ BO_ 1983 "ESP32-DualCAN Model3_VEH. Seen on this car: 1-byte frames; fit poor (bits covered 0%, mux 100%, ranges 100%).";
CM_ BO_ 2004 "ESP32-DualCAN Model3_VEH. Seen on this car: 8-byte frames; fit weak (bits covered 0%, mux 100%, ranges 100%).";
VAL_ 2004 PMR_debugSelector 64 "Mux64" 128 "Mux128" 66 "Mux66" 67 "Mux67" 131 "Mux131" 68 "Mux68" 132 "Mux132" 69 "Mux69" 70 "Mux70" 72 "Mux72" 32 "Mux32" 33 "Mux33" 34 "Mux34" 35 "Mux35" 36 "Mux36" 37 "Mux37" 38 "Mux38" 39 "Mux39" 40 "Mux40" 41 "Mux41" 42 "Mux42" 43 "Mux43" 46 "Mux46" 47 "Mux47" 48 "Mux48" 49 "Mux49" 50 "Mux50" 52 "Mux52" 63 "Mux63" ;
CM_ BO_ 2013 "ESP32-DualCAN Model3_VEH. Seen on this car: 5-byte frames; fit ok (bits covered 100%, mux 100%, ranges 100%).";
CM_ BO_ 2036 "ESP32-DualCAN Model3_VEH. Seen on this car: 1-byte frames; fit poor (bits covered 0%, mux 100%, ranges 100%).";
CM_ BO_ 49 "ESP32-DualCAN Model3_CH. Seen on this car: 8-byte frames; fit good (bits covered 92%, mux 100%, ranges 100%).";
VAL_ 49 EPAS3P_state 0 "STANDBY" 1 "DRIVE" 2 "SUPPORT" 3 "CHARGE" 4 "FEIM" 5 "CLEAR_FAULT" 6 "FAULT" 7 "WELD" 8 "TEST" 9 "SNA" 10 "DIAG" ;
CM_ BO_ 81 "ESP32-DualCAN Model3_CH. Seen on this car: 8-byte frames; fit good (bits covered 92%, mux 100%, ranges 100%).";
VAL_ 81 EPAS3S_state 0 "STANDBY" 1 "DRIVE" 2 "SUPPORT" 3 "CHARGE" 4 "FEIM" 5 "CLEAR_FAULT" 6 "FAULT" 7 "WELD" 8 "TEST" 9 "SNA" 10 "DIAG" ;
CM_ BO_ 305 "ESP32-DualCAN Model3_CH. Seen on this car: 8-byte frames; fit good (bits covered 100%, mux 100%, ranges 100%, checksum 100%).";
CM_ BO_ 321 "ESP32-DualCAN Model3_CH. Seen on this car: 8-byte frames; fit good (bits covered 100%, mux 100%, ranges 100%, checksum 100%).";
CM_ BO_ 326 "ESP32-DualCAN Model3_CH. Seen on this car: 8-byte frames; fit good (bits covered 88%, mux 100%, ranges 100%, checksum 100%).";
CM_ BO_ 329 "ESP32-DualCAN Model3_CH. Seen on this car: 8-byte frames; fit good (bits covered 100%, mux 100%, ranges 100%, checksum 100%).";
VAL_ 329 IBST_brakeTorqueTarget 8191 "SNA" ;
CM_ BO_ 454 "ESP32-DualCAN Model3_CH. Seen on this car: 6-byte frames; fit ok (bits covered 100%, mux 100%, ranges 100%).";
CM_ BO_ 521 "ESP32-DualCAN Model3_CH. Seen on this car: 8-byte frames; fit ok (bits covered 100%, mux 0%, ranges 100%, checksum 100%).";
VAL_ 521 DAS_pedalControl_accelPedalPos 255 "SNA" ;
VAL_ 521 DAS_gearRequest 0 "IDLE_SNA" 1 "PARK" 2 "REVERSE" 3 "NEUTRAL" 4 "DRIVE" ;
CM_ BO_ 551 "ESP32-DualCAN Model3_CH. Seen on this car: 8-byte frames; fit good (bits covered 100%, mux 100%, ranges 100%).";
CM_ BO_ 561 "ESP32-DualCAN Model3_CH. Seen on this car: 8-byte frames; fit good (bits covered 100%, mux 100%, ranges 100%).";
CM_ BO_ 565 "ESP32-DualCAN Model3_CH. Seen on this car: 4-byte frames; fit ok (bits covered 100%, mux 100%, ranges 100%).";
CM_ BO_ 576 "ESP32-DualCAN Model3_CH. Seen on this car: 2-byte frames; fit ok (bits covered 100%, mux 100%, ranges 100%, checksum 100%).";
CM_ BO_ 783 "ESP32-DualCAN Model3_CH. Seen on this car: 6-byte frames; fit poor (bits covered 0%, mux 100%, ranges 100%).";
CM_ BO_ 838 "ESP32-DualCAN Model3_CH. Seen on this car: 8-byte frames; fit weak (bits covered 0%, mux 100%, ranges 100%).";
VAL_ 838 GTW_autopilotOverrideState 0 "BASE" 1 "SUBSCRIPTION" 2 "TRIAL" ;
CM_ BO_ 843 "ESP32-DualCAN Model3_CH. Seen on this car: 6-byte frames; fit ok (bits covered 100%, mux 100%, ranges 100%).";
CM_ BO_ 847 "ESP32-DualCAN Model3_CH. Seen on this car: 8-byte frames; fit good (bits covered 100%, mux 100%, ranges 100%).";
CM_ BO_ 852 "ESP32-DualCAN Model3_CH. Seen on this car: 6-byte frames; fit ok (bits covered 100%, mux 100%, ranges 100%).";
CM_ BO_ 939 "ESP32-DualCAN Model3_CH. Seen on this car: 5-byte frames; fit poor (bits covered 0%, mux 100%, ranges 100%).";
CM_ BO_ 943 "ESP32-DualCAN Model3_CH. Seen on this car: 8-byte frames; fit good (bits covered 100%, mux 100%, ranges 100%).";
CM_ BO_ 971 "ESP32-DualCAN Model3_CH. Seen on this car: 5-byte frames; fit ok (bits covered 100%, mux 100%, ranges 100%).";
CM_ BO_ 977 "ESP32-DualCAN Model3_CH. Seen on this car: 8-byte frames; fit good (bits covered 100%, mux 100%, ranges 100%).";
VAL_ 977 EPAS3S_resyncStatus 0 "PENDING" 1 "COMPLETE" ;
CM_ BO_ 988 "ESP32-DualCAN Model3_CH. Seen on this car: 8-byte frames; fit weak (bits covered 0%, mux 100%, ranges 100%).";
CM_ BO_ 1023 "ESP32-DualCAN Model3_CH. Seen on this car: 8-byte frames; fit ok (bits covered 56%, mux 100%, ranges 100%).";
CM_ BO_ 1043 "ESP32-DualCAN Model3_CH. Seen on this car: 3-byte frames; fit ok (bits covered 100%, mux 100%, ranges 100%).";
CM_ BO_ 1045 "ESP32-DualCAN Model3_CH. Seen on this car: 1-byte frames; fit ok (bits covered 100%, mux 100%, ranges 100%).";
CM_ BO_ 1048 "ESP32-DualCAN Model3_CH. Seen on this car: 2-byte frames; fit ok (bits covered 100%, mux 100%, ranges 100%).";
CM_ BO_ 1061 "ESP32-DualCAN Model3_CH. Seen on this car: 8-byte frames; fit weak (bits covered 0%, mux 100%, ranges 100%).";
CM_ BO_ 1149 "ESP32-DualCAN Model3_CH. Seen on this car: 8-byte frames; fit good (bits covered 100%, mux 100%, ranges 100%).";
CM_ BO_ 1151 "ESP32-DualCAN Model3_CH. Seen on this car: 8-byte frames; fit weak (bits covered 0%, mux 100%, ranges 100%).";
CM_ BO_ 1160 "ESP32-DualCAN Model3_CH. Seen on this car: 4-byte frames; fit ok (bits covered 100%, mux 100%, ranges 100%).";
CM_ BO_ 1161 "ESP32-DualCAN Model3_CH. Seen on this car: 8-byte frames; fit good (bits covered 100%, mux 100%, ranges 100%, checksum 100%).";
CM_ BO_ 1177 "ESP32-DualCAN Model3_CH. Seen on this car: 8-byte frames; fit good (bits covered 100%, mux 100%, ranges 100%).";
CM_ BO_ 1179 "ESP32-DualCAN Model3_CH. Seen on this car: 1-byte frames; fit poor (bits covered 0%, mux 100%, ranges 100%).";
CM_ BO_ 1233 "ESP32-DualCAN Model3_CH. Seen on this car: 8-byte frames; fit weak (bits covered 0%, mux 100%, ranges 100%).";
CM_ BO_ 1285 "ESP32-DualCAN Model3_CH. Seen on this car: 8-byte frames; fit good (bits covered 100%, mux 100%, ranges 100%).";
VAL_ 1285 ESP_alertState 0 "CLEARED" 1 "SET" ;
VAL_ 1285 ESP_alertID 0 "ALERT_DO_NOT_USE_ZERO" 1 "a001_DriverDoorOpen" 2 "a002_DoorOpen" 3 "a003_TrunkOpen" 4 "a004_FrunkOpen" 5 "a005_HeadlightsOnDoorOpen" 6 "a006_RemoteServiceAlert" 7 "a007_SoftPackConfigMismatch" 8 "a008_TouchScreenError" 9 "a009_SquashfsError" 10 "a010_MapsMissing" 11 "a011_IncorrectMap" 12 "a012_NotOnPrivateProperty" 13 "a013_TPMSHardWarning" 14 "a014_TPMSSoftWarning" 15 "a015_TPMSOverPressureWarning" 16 "a016_TPMSTemperatureWarning" 17 "a017_TPMSSystemFault" 18 "a018_SlipStartOn" 19 "a019_ParkBrakeFault" 20 "a020_SteeringReduced" 21 "a021_RearSeatbeltUnbuckled" 22 "a022_ApeFusesEtc" 23 "a023_CellInternetCheckFailed" 24 "a024_WifiInternetCheckFailed" 25 "a025_WifiOnlineCheckFailed" 26 "a026_ModemResetLoopDetected" 27 "a027_AutoSteerMIA" 28 "a028_FrontTrunkPopupClosed" 29 "a029_ModemMIA" 30 "a030_ModemVMCrash" 31 "a031_BrakeFluidLow" 32 "a032_CellModemRecoveryResets" 33 "a033_ApTrialExpired" 34 "a034_WakeupProblem" 35 "a035_AudioWatchdogKernelError" 36 "a036_AudioWatchdogHfpError" 37 "a037_AudioWatchdogXrunStormError" 38 "a038_AudioWatchdogA2bI2cLockupError" 39 "a039_AudioA2bNeedRediscovery" 40 "a040_HomelinkTransmit" 41 "a041_AudioDmesgXrun" 42 "a042_AudioDmesgRtThrottling" 43 "a043_InvalidMapDataOverride" 44 "a044_AudioDmesgDspException" 45 "a045_ECallNeedsService" 46 "a046_BackupCameraStreamError" 47 "a047_CellRoamingDisallowed" 48 "a048_AudioPremiumAmpCheckFailed" 49 "a049_BrakeShiftRequired" 50 "a050_BackupCameraIPUTimeout" 51 "a051_BackupCameraFrameTimeout" 52 "a052_KernelPanicReported" 53 "a053_QtCarExitError" 54 "a054_AudioBoostPowerBad" 55 "a055_ManualECallDisabled" 56 "a056_ManualECallButtonDisconnected" 57 "a057_CellAntennaDisconnected" 58 "a058_GPSAntennaDisconnected" 59 "a059_ECallSpeakerDisconnected" 60 "a060_ECallMicDisconnected" 61 "a061_SIMTestFailed" 62 "a062_ENSTestFailed" 63 "a063_CellularTestFailed" 64 "a064_ModemFirmwareTestFailed" 65 "a065_WiFiRecoveryReset" 66 "a066_GpuHangDetected" 67 "a067_WarnOnI915" 68 "a068_VideoUnexpectedExit" 69 "a069_VideoUDPTimeout" 70 "a070_VideoPipelineWarning" 71 "a071_VideoPipelineError" 72 "a072_ECallAnalogMicFailed" 73 "a073_ECallDigitalMicFailed" 74 "a074_EMMCHangDetected" 75 "a075_BackupCameraInitError" 76 "a076_NumFalseManualECalls" 77 "a077_AudioA2bMicChannelSwap" 78 "a078_DashcamUsbDriveUnmountable" 79 "a079_DashcamUsbDriveFull" 80 "a080_DashcamUsbDriveSlow" 81 "a081_CellModemSearchExpired" 82 "a082_NumModemRebootStuckInECall" 83 "a083_ECallProxyWatchdogTriggered" 84 "a084_SerializerError" 85 "a085_DeserializerError" 86 "a086_TouchEnumerationError" 87 "a087_BmpReset" 88 "a088_CellRemovableSimMissing" 89 "a089_RadioSoftResetError" 90 "a090_RadioPingFailError" 91 "a091_VehicleLinkStall" 92 "a092_updateStarted" 93 "a093_updateEnded" 94 "a094_ModemPowerOnFailure" 95 "a095_CidStorageRunningLow" 96 "a096_VideodPipelineIssueDetected" 97 "a097_AudiodRestarted" 98 "a098_DiskCheckFailure" 99 "a099_eMMCStatusError" 100 "a100_eMMCFTLError" 101 "a101_wifiStackProblem" 102 "a102_A2bDiscoveryFailed" 103 "a103_UsbHubNotEnumerating" 104 "a104_DashcamUsbDriveMissing" 105 "a105_firmwareReinstallRequested" 106 "a106_rebootBackstopTriggered" 107 "a107_DashcamUsbDriveTooBigForVfatFsck" 108 "a108_DashcamUsbDriveGettingFull" 109 "a109_DashcamUsbDriveTooSmall" 110 "a110_DashcamUsbDriveCorrupt" 111 "a111_DashcamUsbDriveWrongPort" 112 "a112_badUSBDevice" 113 "a113_DashcamHasOnboardSentryClips" ;
CM_ BO_ 1301 "ESP32-DualCAN Model3_CH. Seen on this car: 8-byte frames; fit weak (bits covered 0%, mux 100%, ranges 100%).";
CM_ BO_ 1361 "ESP32-DualCAN Model3_CH. Seen on this car: 8-byte frames; fit weak (bits covered 0%, mux 100%, ranges 100%).";
CM_ BO_ 1368 "ESP32-DualCAN Model3_CH. Seen on this car: 8-byte frames; fit ok (bits covered 100%, mux 100%, ranges 100%).";
CM_ BO_ 1383 "ESP32-DualCAN Model3_CH. Seen on this car: 8-byte frames; fit good (bits covered 87%, mux 100%, ranges 100%).";
VAL_ 1383 ADSP_eCallSpeakerStatus 0 "NOT_RUN_YET" 1 "PASSED" 2 "FAILED_DISCONNECT" 3 "FAILED_DIAG" ;
VAL_ 1383 ADSP_eCallMicrophoneStatus 0 "NOT_RUN_YET" 1 "PASSED" 2 "FAILED" ;
VAL_ 1383 ADSP_eCallState 0 "INACTIVE" 1 "ACTIVE" ;
VAL_ 1383 ADSP_eCallSelfTest 0 "NOT_RUN_YET" 1 "PASSED" 2 "FAILED" ;
VAL_ 1383 ADSP_eCall_ENS_state 0 "UNKOWN" 1 "SIGNAL_ERROR" 2 "SOURCE_MISSING" 3 "SOURCE_ERROR" 4 "EMERGENCY" 5 "NORMAL" ;
VAL_ 1383 ADSP_ancMode 0 "OFF" 1 "FRONT" 2 "REAR" 3 "ALL" 4 "CALIBRATING_00" 5 "DISABLED_REASON_A2BA" 6 "DISABLED_REASON_A2BB" 7 "DISABLED_REASON_CLOSURE_OPEN" 8 "DISABLED_REASON_HVAC" 9 "DISABLED_REASON_SEAT_MOVING" 10 "DISABLED_REASON_REAR_OCCUPANT" 11 "DISABLED_REASON_WINDOW_OPEN" 12 "CALIBRATING_20" 13 "CALIBRATING_40" 14 "CALIBRATING_60" 15 "CALIBRATING_80" 16 "UNKNOWN" ;
VAL_ 1383 ADSP_tunerSelect 0 "FM" 1 "XM" ;
VAL_ 1383 ADSP_sourceSelect 0 "MEDIA" 1 "A2DP" 2 "TUNER" 3 "SINE" 4 "PINK" ;
VAL_ 1383 ADSP_ancState 0 "INIT" 1 "DSP_OFF" 2 "DSP_ON" 3 "ENABLED" ;
VAL_ 1383 ADSP_baseamp2State 0 "INIT" 1 "CONFIGURED" 2 "ENABLED" 3 "HALT" 4 "TURN_OFF" 5 "OFF" 6 "DIAG" ;
VAL_ 1383 ADSP_baseamp1State 0 "INIT" 1 "CONFIGURED" 2 "ENABLED" 3 "HALT" 4 "TURN_OFF" 5 "OFF" 6 "DIAG" ;
VAL_ 1383 ADSP_baseamp0State 0 "INIT" 1 "CONFIGURED" 2 "ENABLED" 3 "HALT" 4 "TURN_OFF" 5 "OFF" 6 "DIAG" ;
VAL_ 1383 ADSP_a2bbState 0 "INIT" 1 "DOWN" 2 "RESTART" 3 "DISCOVER" 4 "DISCOVER_WAIT" 5 "IDLE" 6 "DIAG" 7 "DISCOVER_RETRY" 8 "GOING_DOWN" ;
VAL_ 1383 ADSP_a2baState 0 "INIT" 1 "DOWN" 2 "RESTART" 3 "DISCOVER" 4 "DISCOVER_WAIT" 5 "IDLE" 6 "DIAG" 7 "DISCOVER_RETRY" 8 "GOING_DOWN" ;
CM_ BO_ 1397 "ESP32-DualCAN Model3_CH. Seen on this car: 5-byte frames; fit ok (bits covered 75%, mux 100%, ranges 100%).";
CM_ BO_ 1429 "ESP32-DualCAN Model3_CH. Seen on this car: 8-byte frames; fit good (bits covered 100%, mux 100%, ranges 100%).";
VAL_ 1429 OCS1P_alertState 0 "CLEARED" 1 "SET" ;
VAL_ 1429 OCS1P_alertID 0 "ALERT_DO_NOT_USE_ZERO" 1 "a001_DriverDoorOpen" 2 "a002_DoorOpen" 3 "a003_TrunkOpen" 4 "a004_FrunkOpen" 5 "a005_HeadlightsOnDoorOpen" 6 "a006_RemoteServiceAlert" 7 "a007_SoftPackConfigMismatch" 8 "a008_TouchScreenError" 9 "a009_SquashfsError" 10 "a010_MapsMissing" 11 "a011_IncorrectMap" 12 "a012_NotOnPrivateProperty" 13 "a013_TPMSHardWarning" 14 "a014_TPMSSoftWarning" 15 "a015_TPMSOverPressureWarning" 16 "a016_TPMSTemperatureWarning" 17 "a017_TPMSSystemFault" 18 "a018_SlipStartOn" 19 "a019_ParkBrakeFault" 20 "a020_SteeringReduced" 21 "a021_RearSeatbeltUnbuckled" 22 "a022_ApeFusesEtc" 23 "a023_CellInternetCheckFailed" 24 "a024_WifiInternetCheckFailed" 25 "a025_WifiOnlineCheckFailed" 26 "a026_ModemResetLoopDetected" 27 "a027_AutoSteerMIA" 28 "a028_FrontTrunkPopupClosed" 29 "a029_ModemMIA" 30 "a030_ModemVMCrash" 31 "a031_BrakeFluidLow" 32 "a032_CellModemRecoveryResets" 33 "a033_ApTrialExpired" 34 "a034_WakeupProblem" 35 "a035_AudioWatchdogKernelError" 36 "a036_AudioWatchdogHfpError" 37 "a037_AudioWatchdogXrunStormError" 38 "a038_AudioWatchdogA2bI2cLockupError" 39 "a039_AudioA2bNeedRediscovery" 40 "a040_HomelinkTransmit" 41 "a041_AudioDmesgXrun" 42 "a042_AudioDmesgRtThrottling" 43 "a043_InvalidMapDataOverride" 44 "a044_AudioDmesgDspException" 45 "a045_ECallNeedsService" 46 "a046_BackupCameraStreamError" 47 "a047_CellRoamingDisallowed" 48 "a048_AudioPremiumAmpCheckFailed" 49 "a049_BrakeShiftRequired" 50 "a050_BackupCameraIPUTimeout" 51 "a051_BackupCameraFrameTimeout" 52 "a052_KernelPanicReported" 53 "a053_QtCarExitError" 54 "a054_AudioBoostPowerBad" 55 "a055_ManualECallDisabled" 56 "a056_ManualECallButtonDisconnected" 57 "a057_CellAntennaDisconnected" 58 "a058_GPSAntennaDisconnected" 59 "a059_ECallSpeakerDisconnected" 60 "a060_ECallMicDisconnected" 61 "a061_SIMTestFailed" 62 "a062_ENSTestFailed" 63 "a063_CellularTestFailed" 64 "a064_ModemFirmwareTestFailed" 65 "a065_WiFiRecoveryReset" 66 "a066_GpuHangDetected" 67 "a067_WarnOnI915" 68 "a068_VideoUnexpectedExit" 69 "a069_VideoUDPTimeout" 70 "a070_VideoPipelineWarning" 71 "a071_VideoPipelineError" 72 "a072_ECallAnalogMicFailed" 73 "a073_ECallDigitalMicFailed" 74 "a074_EMMCHangDetected" 75 "a075_BackupCameraInitError" 76 "a076_NumFalseManualECalls" 77 "a077_AudioA2bMicChannelSwap" 78 "a078_DashcamUsbDriveUnmountable" 79 "a079_DashcamUsbDriveFull" 80 "a080_DashcamUsbDriveSlow" 81 "a081_CellModemSearchExpired" 82 "a082_NumModemRebootStuckInECall" 83 "a083_ECallProxyWatchdogTriggered" 84 "a084_SerializerError" 85 "a085_DeserializerError" 86 "a086_TouchEnumerationError" 87 "a087_BmpReset" 88 "a088_CellRemovableSimMissing" 89 "a089_RadioSoftResetError" 90 "a090_RadioPingFailError" 91 "a091_VehicleLinkStall" 92 "a092_updateStarted" 93 "a093_updateEnded" 94 "a094_ModemPowerOnFailure" 95 "a095_CidStorageRunningLow" 96 "a096_VideodPipelineIssueDetected" 97 "a097_AudiodRestarted" 98 "a098_DiskCheckFailure" 99 "a099_eMMCStatusError" 100 "a100_eMMCFTLError" 101 "a101_wifiStackProblem" 102 "a102_A2bDiscoveryFailed" 103 "a103_UsbHubNotEnumerating" 104 "a104_DashcamUsbDriveMissing" 105 "a105_firmwareReinstallRequested" 106 "a106_rebootBackstopTriggered" 107 "a107_DashcamUsbDriveTooBigForVfatFsck" 108 "a108_DashcamUsbDriveGettingFull" 109 "a109_DashcamUsbDriveTooSmall" 110 "a110_DashcamUsbDriveCorrupt" 111 "a111_DashcamUsbDriveWrongPort" 112 "a112_badUSBDevice" 113 "a113_DashcamHasOnboardSentryClips" ;
CM_ BO_ 1469 "ESP32-DualCAN Model3_CH. Seen on this car: 8-byte frames; fit weak (bits covered 0%, mux 100%, ranges 100%).";
VAL_ 1469 IBST_alertState 0 "CLEARED" 1 "SET" ;
VAL_ 1469 IBST_alertID 0 "ALERT_DO_NOT_USE_ZERO" 1 "a001_DriverDoorOpen" 2 "a002_DoorOpen" 3 "a003_TrunkOpen" 4 "a004_FrunkOpen" 5 "a005_HeadlightsOnDoorOpen" 6 "a006_RemoteServiceAlert" 7 "a007_SoftPackConfigMismatch" 8 "a008_TouchScreenError" 9 "a009_SquashfsError" 10 "a010_MapsMissing" 11 "a011_IncorrectMap" 12 "a012_NotOnPrivateProperty" 13 "a013_TPMSHardWarning" 14 "a014_TPMSSoftWarning" 15 "a015_TPMSOverPressureWarning" 16 "a016_TPMSTemperatureWarning" 17 "a017_TPMSSystemFault" 18 "a018_SlipStartOn" 19 "a019_ParkBrakeFault" 20 "a020_SteeringReduced" 21 "a021_RearSeatbeltUnbuckled" 22 "a022_ApeFusesEtc" 23 "a023_CellInternetCheckFailed" 24 "a024_WifiInternetCheckFailed" 25 "a025_WifiOnlineCheckFailed" 26 "a026_ModemResetLoopDetected" 27 "a027_AutoSteerMIA" 28 "a028_FrontTrunkPopupClosed" 29 "a029_ModemMIA" 30 "a030_ModemVMCrash" 31 "a031_BrakeFluidLow" 32 "a032_CellModemRecoveryResets" 33 "a033_ApTrialExpired" 34 "a034_WakeupProblem" 35 "a035_AudioWatchdogKernelError" 36 "a036_AudioWatchdogHfpError" 37 "a037_AudioWatchdogXrunStormError" 38 "a038_AudioWatchdogA2bI2cLockupError" 39 "a039_AudioA2bNeedRediscovery" 40 "a040_HomelinkTransmit" 41 "a041_AudioDmesgXrun" 42 "a042_AudioDmesgRtThrottling" 43 "a043_InvalidMapDataOverride" 44 "a044_AudioDmesgDspException" 45 "a045_ECallNeedsService" 46 "a046_BackupCameraStreamError" 47 "a047_CellRoamingDisallowed" 48 "a048_AudioPremiumAmpCheckFailed" 49 "a049_BrakeShiftRequired" 50 "a050_BackupCameraIPUTimeout" 51 "a051_BackupCameraFrameTimeout" 52 "a052_KernelPanicReported" 53 "a053_QtCarExitError" 54 "a054_AudioBoostPowerBad" 55 "a055_ManualECallDisabled" 56 "a056_ManualECallButtonDisconnected" 57 "a057_CellAntennaDisconnected" 58 "a058_GPSAntennaDisconnected" 59 "a059_ECallSpeakerDisconnected" 60 "a060_ECallMicDisconnected" 61 "a061_SIMTestFailed" 62 "a062_ENSTestFailed" 63 "a063_CellularTestFailed" 64 "a064_ModemFirmwareTestFailed" 65 "a065_WiFiRecoveryReset" 66 "a066_GpuHangDetected" 67 "a067_WarnOnI915" 68 "a068_VideoUnexpectedExit" 69 "a069_VideoUDPTimeout" 70 "a070_VideoPipelineWarning" 71 "a071_VideoPipelineError" 72 "a072_ECallAnalogMicFailed" 73 "a073_ECallDigitalMicFailed" 74 "a074_EMMCHangDetected" 75 "a075_BackupCameraInitError" 76 "a076_NumFalseManualECalls" 77 "a077_AudioA2bMicChannelSwap" 78 "a078_DashcamUsbDriveUnmountable" 79 "a079_DashcamUsbDriveFull" 80 "a080_DashcamUsbDriveSlow" 81 "a081_CellModemSearchExpired" 82 "a082_NumModemRebootStuckInECall" 83 "a083_ECallProxyWatchdogTriggered" 84 "a084_SerializerError" 85 "a085_DeserializerError" 86 "a086_TouchEnumerationError" 87 "a087_BmpReset" 88 "a088_CellRemovableSimMissing" 89 "a089_RadioSoftResetError" 90 "a090_RadioPingFailError" 91 "a091_VehicleLinkStall" 92 "a092_updateStarted" 93 "a093_updateEnded" 94 "a094_ModemPowerOnFailure" 95 "a095_CidStorageRunningLow" 96 "a096_VideodPipelineIssueDetected" 97 "a097_AudiodRestarted" 98 "a098_DiskCheckFailure" 99 "a099_eMMCStatusError" 100 "a100_eMMCFTLError" 101 "a101_wifiStackProblem" 102 "a102_A2bDiscoveryFailed" 103 "a103_UsbHubNotEnumerating" 104 "a104_DashcamUsbDriveMissing" 105 "a105_firmwareReinstallRequested" 106 "a106_rebootBackstopTriggered" 107 "a107_DashcamUsbDriveTooBigForVfatFsck" 108 "a108_DashcamUsbDriveGettingFull" 109 "a109_DashcamUsbDriveTooSmall" 110 "a110_DashcamUsbDriveCorrupt" 111 "a111_DashcamUsbDriveWrongPort" 112 "a112_badUSBDevice" 113 "a113_DashcamHasOnboardSentryClips" ;
CM_ BO_ 1497 "ESP32-DualCAN Model3_CH. Seen on this car: 8-byte frames; fit good (bits covered 100%, mux 100%, ranges 100%).";
VAL_ 1497 DAS_closestInLaneTargetVxRel 0 "NO_TARGET" ;
VAL_ 1497 DAS_radarTarget4_dx 0 "NO_TARGET" ;
VAL_ 1497 DAS_closestRightLaneTargetDx 0 "NO_TARGET" ;
VAL_ 1497 DAS_radarTarget1_VxRel 0 "NO_TARGET" ;
VAL_ 1497 DAS_radarTarget3_dx 0 "NO_TARGET" ;
VAL_ 1497 DAS_closestLeftLaneTargetDx 0 "NO_TARGET" ;
VAL_ 1497 DAS_radarTarget1_dx 0 "NO_TARGET" ;
VAL_ 1497 DAS_radarTarget2_dx 0 "NO_TARGET" ;
VAL_ 1497 DAS_desiredTarget_dx 255 "SNA" ;
VAL_ 1497 DAS_secondInLaneTargetDx 0 "NO_TARGET" ;
VAL_ 1497 DAS_closestInLaneTargetDx 0 "NO_TARGET" ;
VAL_ 1497 DAS_radarTarget5_dx 0 "NO_TARGET" ;
VAL_ 1497 DAS_carLogMultiplexer 0 "FEATURE_STATE" 1 "RADAR" 2 "FCM" 3 "PROFILER" ;
CM_ BO_ 1521 "ESP32-DualCAN Model3_CH. Seen on this car: 8-byte frames; fit poor (bits covered 0%, mux 100%, ranges 100%).";
CM_ BO_ 1592 "ESP32-DualCAN Model3_CH. Seen on this car: 8-byte frames; fit ok (bits covered 100%, mux 100%, ranges 100%).";
CM_ BO_ 1601 "ESP32-DualCAN Model3_CH. Seen on this car: 8-byte frames; fit ok (bits covered 100%, mux 100%, ranges 100%).";
CM_ BO_ 1806 "ESP32-DualCAN Model3_CH. Seen on this car: 8-byte frames; fit good (bits covered 100%, mux 100%, ranges 100%).";
CM_ BO_ 1807 "ESP32-DualCAN Model3_CH. Seen on this car: 8-byte frames; fit good (bits covered 100%, mux 100%, ranges 100%).";
CM_ BO_ 1776 "Alive message: checksum + counter only; no data seen (route 494, 2026-11-19). CRC-8 SAE J1850 over byte 1.";
CM_ BO_ 1779 "Alive message: checksum + counter only; no data seen (route 494, 2026-11-19). CRC-8 SAE J1850 over bytes 1-2; byte 2 always 0.";
CM_ BO_ 654 "Alive message: checksum + counter only; no data seen (route 494, 2026-11-19). Byte sum + 0x90; bytes 2-7 constant.";
CM_ BO_ 655 "Alive message: checksum + counter only; no data seen (route 494, 2026-11-19). Byte sum + 0x91; bytes 2-7 constant.";
CM_ BO_ 608 "Unknown 10 Hz: bit 0 flag, counter at 52; byte 7 = byte sum + 0x62.";
CM_ BO_ 337 "Unknown 1 Hz status: only bits 48-49 change.";
